VERSION ""

NS_ :

BS_:

BU_: VCM FAS EBS

BO_ 594 EBS_CpbtyAxle456_C03: 64 EBS
 SG_ CpbtyAxle5_BrkEgyCpctyLe : 320|8@1+ (150,0) [0|38250] "NotApplicable"  VCM
 SG_ CpbtyAxle4_TqCpbtyRateQltyLe : 144|4@1+ (1,0) [0|0] ""  VCM
 SG_ CpbtyAxle4_TqCpbtyRateDecRi : 72|8@1+ (1000,0) [0|255000] "NotApplicable"  VCM
 SG_ CpbtyAxle4_BrkEgyCpctyQltyRi : 44|4@1+ (1,0) [0|0] ""  VCM
 SG_ CpbtyAxle4_TqCpbtyMinRi : 110|10@1+ (50,0) [0|51150] "Nm"  VCM
 SG_ CpbtyAxle5_TqCpbtyMaxLe : 288|10@1+ (50,0) [0|51150] "Nm"  VCM
 SG_ CpbtyAxle5_TqCpbtyQltyLe : 274|4@1+ (1,0) [0|0] ""  VCM
 SG_ CpbtyAxle5_PadWearRi : 256|8@1+ (0.5,0) [0|127.5] "Percent"  VCM
 SG_ CpbtyAxle5_TqCpbtyRateIncLeRi : 224|8@1+ (1000,0) [0|255000] "NotApplicable"  VCM
 SG_ CpbtyAxle6_TqCpbtyRateQltyLe : 480|4@1+ (1,0) [0|0] ""  VCM
 SG_ CpbtyAxle5_TqCpbtyRateDecLe : 216|8@1+ (1000,0) [0|255000] "NotApplicable"  VCM
 SG_ CpbtyAxle6_TqCpbtyMinRi : 446|10@1+ (50,0) [0|51150] "Nm"  VCM
 SG_ CpbtyAxle6_BrkEgyCpctyRi : 360|8@1+ (150,0) [0|38250] "NotApplicable"  VCM
 SG_ CpbtyAxle6_TqCpbtyRateQltyRi : 484|4@1+ (1,0) [0|0] ""  VCM
 SG_ CpbtyAxle6_TqCpbtyRateIncLeRi : 392|8@1+ (1000,0) [0|255000] "NotApplicable"  VCM
 SG_ CpbtyAxle5_TqCpbtyMaxRi : 302|10@1+ (50,0) [0|51150] "Nm"  VCM
 SG_ CpbtyAxle5_CRC : 168|16@1+ (1,0) [0|65535] "NotApplicable"  VCM
 SG_ CpbtyAxle6_TqCpbtyRateDecLe : 384|8@1+ (1000,0) [0|255000] "NotApplicable"  VCM
 SG_ CpbtyAxle5_SlipCtrlEna : 328|2@1+ (1,0) [0|0] ""  VCM
 SG_ CpbtyAxle5_PadWearQltyLe : 200|4@1+ (1,0) [0|0] ""  VCM
 SG_ CpbtyAxle6_BrkEgyCpctyQltyRi : 380|4@1+ (1,0) [0|0] ""  VCM
 SG_ CpbtyAxle5_BrkEgyCpctyQltyLe : 208|4@1+ (1,0) [0|0] ""  VCM
 SG_ CpbtyAxle6_PadWearQltyRi : 372|4@1+ (1,0) [0|0] ""  VCM
 SG_ CpbtyAxle6_TqCpbtyMaxRi : 470|10@1+ (50,0) [0|51150] "Nm"  VCM
 SG_ CpbtyAxle4_TqCpbtyQltyLe : 106|4@1+ (1,0) [0|0] ""  VCM
 SG_ CpbtyAxle4_SlipCtrlEna : 160|2@1+ (1,0) [0|0] ""  VCM
 SG_ CpbtyAxle4_BrkEgyCpctyRi : 24|8@1+ (150,0) [0|38250] "NotApplicable"  VCM
 SG_ CpbtyAxle6_TqCpbtyQltyRi : 466|4@1+ (1,0) [0|0] ""  VCM
 SG_ CpbtyAxle6_CRC : 336|16@1+ (1,0) [0|65535] "NotApplicable"  VCM
 SG_ CpbtyAxle5_TqCpbtyRateQltyLe : 312|4@1+ (1,0) [0|0] ""  VCM
 SG_ CpbtyAxle4_TqCpbtyMaxLe : 120|10@1+ (50,0) [0|51150] "Nm"  VCM
 SG_ CpbtyAxle4_PadWearRi : 88|8@1+ (0.5,0) [0|127.5] "Percent"  VCM
 SG_ CpbtyAxle6_TqCpbtyMinLe : 432|10@1+ (50,0) [0|51150] "Nm"  VCM
 SG_ CpbtyAxle4_CRC : 0|16@1+ (1,0) [0|65535] "NotApplicable"  VCM
 SG_ CpbtyAxle4_SqC : 16|8@1+ (1,0) [0|255] "Count"  VCM
 SG_ CpbtyAxle5_TqCpbtyMinLe : 264|10@1+ (50,0) [0|51150] "Nm"  VCM
 SG_ CpbtyAxle6_PadWearQltyLe : 368|4@1+ (1,0) [0|0] ""  VCM
 SG_ CpbtyAxle6_PadWearRi : 424|8@1+ (0.5,0) [0|127.5] "Percent"  VCM
 SG_ CpbtyAxle5_TqCpbtyRateQltyRi : 316|4@1+ (1,0) [0|0] ""  VCM
 SG_ CpbtyAxle4_TqCpbtyQltyRi : 130|4@1+ (1,0) [0|0] ""  VCM
 SG_ CpbtyAxle6_SlipCtrlEna : 496|2@1+ (1,0) [0|0] ""  VCM
 SG_ CpbtyAxle5_TqCpbtyQltyRi : 298|4@1+ (1,0) [0|0] ""  VCM
 SG_ CpbtyAxle4_BrkEgyCpctyQltyLe : 40|4@1+ (1,0) [0|0] ""  VCM
 SG_ CpbtyAxle4_TqCpbtyMinLe : 96|10@1+ (50,0) [0|51150] "Nm"  VCM
 SG_ CpbtyAxle5_TqCpbtyMinRi : 278|10@1+ (50,0) [0|51150] "Nm"  VCM
 SG_ CpbtyAxle6_SqC : 352|8@1+ (1,0) [0|255] "Count"  VCM
 SG_ CpbtyAxle6_TqCpbtyRateDecRi : 408|8@1+ (1000,0) [0|255000] "NotApplicable"  VCM
 SG_ CpbtyAxle6_TqCpbtyRateIncLeLe : 400|8@1+ (1000,0) [0|255000] "NotApplicable"  VCM
 SG_ CpbtyAxle4_TqCpbtyRateDecLe : 48|8@1+ (1000,0) [0|255000] "NotApplicable"  VCM
 SG_ CpbtyAxle4_TqCpbtyRateQltyRi : 148|4@1+ (1,0) [0|0] ""  VCM
 SG_ CpbtyAxle4_BrkEgyCpctyLe : 152|8@1+ (150,0) [0|38250] "NotApplicable"  VCM
 SG_ CpbtyAxle4_TqCpbtyMaxRi : 134|10@1+ (50,0) [0|51150] "Nm"  VCM
 SG_ CpbtyAxle6_TqCpbtyMaxLe : 456|10@1+ (50,0) [0|51150] "Nm"  VCM
 SG_ CpbtyAxle5_TqCpbtyRateIncLeLe : 232|8@1+ (1000,0) [0|255000] "NotApplicable"  VCM
 SG_ CpbtyAxle5_PadWearQltyRi : 204|4@1+ (1,0) [0|0] ""  VCM
 SG_ CpbtyAxle6_BrkEgyCpctyQltyLe : 376|4@1+ (1,0) [0|0] ""  VCM
 SG_ CpbtyAxle5_TqCpbtyRateDecRi : 240|8@1+ (1000,0) [0|255000] "NotApplicable"  VCM
 SG_ CpbtyAxle6_TqCpbtyQltyLe : 442|4@1+ (1,0) [0|0] ""  VCM
 SG_ CpbtyAxle5_SqC : 184|8@1+ (1,0) [0|255] "Count"  VCM
 SG_ CpbtyAxle4_TqCpbtyRateIncLeRi : 56|8@1+ (1000,0) [0|255000] "NotApplicable"  VCM
 SG_ CpbtyAxle6_BrkEgyCpctyLe : 488|8@1+ (150,0) [0|38250] "NotApplicable"  VCM
 SG_ CpbtyAxle5_BrkEgyCpctyRi : 192|8@1+ (150,0) [0|38250] "NotApplicable"  VCM
 SG_ CpbtyAxle5_BrkEgyCpctyQltyRi : 212|4@1+ (1,0) [0|0] ""  VCM
 SG_ CpbtyAxle6_PadWearLe : 416|8@1+ (0.5,0) [0|127.5] "Percent"  VCM
 SG_ CpbtyAxle4_PadWearLe : 80|8@1+ (0.5,0) [0|127.5] "Percent"  VCM
 SG_ CpbtyAxle4_PadWearQltyRi : 36|4@1+ (1,0) [0|0] ""  VCM
 SG_ CpbtyAxle4_TqCpbtyRateIncLeLe : 64|8@1+ (1000,0) [0|255000] "NotApplicable"  VCM
 SG_ CpbtyAxle5_PadWearLe : 248|8@1+ (0.5,0) [0|127.5] "Percent"  VCM
 SG_ CpbtyAxle4_PadWearQltyLe : 32|4@1+ (1,0) [0|0] ""  VCM

BO_ 592 EBS_CpbtyAxle123_C03: 64 EBS
 SG_ CpbtyAxle3_BrkEgyCpctyQltyLe : 376|4@1+ (1,0) [0|0] ""  VCM
 SG_ CpbtyAxle3_TqCpbtyRateIncLeLe : 400|8@1+ (1000,0) [0|255000] "NotApplicable"  VCM
 SG_ CpbtyAxle3_TqCpbtyRateQltyRi : 484|4@1+ (1,0) [0|0] ""  VCM
 SG_ CpbtyAxle1_PadWearQltyLe : 32|4@1+ (1,0) [0|0] ""  VCM
 SG_ CpbtyAxle1_SlipCtrlEna : 160|2@1+ (1,0) [0|0] ""  VCM
 SG_ CpbtyAxle2_PadWearRi : 256|8@1+ (0.5,0) [0|127.5] "Percent"  VCM
 SG_ CpbtyAxle3_TqCpbtyRateQltyLe : 480|4@1+ (1,0) [0|0] ""  VCM
 SG_ CpbtyAxle1_BrkEgyCpctyQltyRi : 44|4@1+ (1,0) [0|0] ""  VCM
 SG_ CpbtyAxle2_TqCpbtyMaxRi : 302|10@1+ (50,0) [0|51150] "Nm"  VCM
 SG_ CpbtyAxle2_TqCpbtyMinLe : 264|10@1+ (50,0) [0|51150] "Nm"  VCM
 SG_ CpbtyAxle2_BrkEgyCpctyQltyLe : 208|4@1+ (1,0) [0|0] ""  VCM
 SG_ CpbtyAxle2_TqCpbtyRateDecLe : 216|8@1+ (1000,0) [0|255000] "NotApplicable"  VCM
 SG_ CpbtyAxle3_SlipCtrlEna : 496|2@1+ (1,0) [0|0] ""  VCM
 SG_ CpbtyAxle3_TqCpbtyQltyLe : 442|4@1+ (1,0) [0|0] ""  VCM
 SG_ CpbtyAxle3_BrkEgyCpctyRi : 360|8@1+ (150,0) [0|38250] "NotApplicable"  VCM
 SG_ CpbtyAxle1_SqC : 16|8@1+ (1,0) [0|255] "Count"  VCM
 SG_ CpbtyAxle1_TqCpbtyQltyLe : 106|4@1+ (1,0) [0|0] ""  VCM
 SG_ CpbtyAxle2_TqCpbtyRateDecRi : 240|8@1+ (1000,0) [0|255000] "NotApplicable"  VCM
 SG_ CpbtyAxle1_TqCpbtyRateIncLeLe : 64|8@1+ (1000,0) [0|255000] "NotApplicable"  VCM
 SG_ CpbtyAxle3_BrkEgyCpctyQltyRi : 380|4@1+ (1,0) [0|0] ""  VCM
 SG_ CpbtyAxle3_TqCpbtyRateDecLe : 384|8@1+ (1000,0) [0|255000] "NotApplicable"  VCM
 SG_ CpbtyAxle3_TqCpbtyRateDecRi : 408|8@1+ (1000,0) [0|255000] "NotApplicable"  VCM
 SG_ CpbtyAxle1_PadWearRi : 88|8@1+ (0.5,0) [0|127.5] "Percent"  VCM
 SG_ CpbtyAxle2_TqCpbtyMaxLe : 288|10@1+ (50,0) [0|51150] "Nm"  VCM
 SG_ CpbtyAxle3_TqCpbtyQltyRi : 466|4@1+ (1,0) [0|0] ""  VCM
 SG_ CpbtyAxle1_TqCpbtyRateDecLe : 48|8@1+ (1000,0) [0|255000] "NotApplicable"  VCM
 SG_ CpbtyAxle1_BrkEgyCpctyRi : 24|8@1+ (150,0) [0|38250] "NotApplicable"  VCM
 SG_ CpbtyAxle3_TqCpbtyMinLe : 432|10@1+ (50,0) [0|51150] "Nm"  VCM
 SG_ CpbtyAxle3_TqCpbtyMinRi : 446|10@1+ (50,0) [0|51150] "Nm"  VCM
 SG_ CpbtyAxle2_BrkEgyCpctyQltyRi : 212|4@1+ (1,0) [0|0] ""  VCM
 SG_ CpbtyAxle2_PadWearLe : 248|8@1+ (0.5,0) [0|127.5] "Percent"  VCM
 SG_ CpbtyAxle2_TqCpbtyQltyRi : 298|4@1+ (1,0) [0|0] ""  VCM
 SG_ CpbtyAxle2_PadWearQltyRi : 204|4@1+ (1,0) [0|0] ""  VCM
 SG_ CpbtyAxle3_PadWearRi : 424|8@1+ (0.5,0) [0|127.5] "Percent"  VCM
 SG_ CpbtyAxle3_PadWearQltyRi : 372|4@1+ (1,0) [0|0] ""  VCM
 SG_ CpbtyAxle1_TqCpbtyMaxRi : 134|10@1+ (50,0) [0|51150] "Nm"  VCM
 SG_ CpbtyAxle2_TqCpbtyRateQltyRi : 316|4@1+ (1,0) [0|0] ""  VCM
 SG_ CpbtyAxle1_BrkEgyCpctyLe : 152|8@1+ (150,0) [0|38250] "NotApplicable"  VCM
 SG_ CpbtyAxle2_SlipCtrlEna : 328|2@1+ (1,0) [0|0] ""  VCM
 SG_ CpbtyAxle1_TqCpbtyRateIncLeRi : 56|8@1+ (1000,0) [0|255000] "NotApplicable"  VCM
 SG_ CpbtyAxle2_TqCpbtyMinRi : 278|10@1+ (50,0) [0|51150] "Nm"  VCM
 SG_ CpbtyAxle3_TqCpbtyMaxLe : 456|10@1+ (50,0) [0|51150] "Nm"  VCM
 SG_ CpbtyAxle1_TqCpbtyRateQltyRi : 148|4@1+ (1,0) [0|0] ""  VCM
 SG_ CpbtyAxle1_CRC : 0|16@1+ (1,0) [0|65535] "NotApplicable"  VCM
 SG_ CpbtyAxle1_PadWearQltyRi : 36|4@1+ (1,0) [0|0] ""  VCM
 SG_ CpbtyAxle2_CRC : 168|16@1+ (1,0) [0|65535] "NotApplicable"  VCM
 SG_ CpbtyAxle2_SqC : 184|8@1+ (1,0) [0|255] "Count"  VCM
 SG_ CpbtyAxle2_TqCpbtyRateIncLeLe : 232|8@1+ (1000,0) [0|255000] "NotApplicable"  VCM
 SG_ CpbtyAxle2_TqCpbtyRateIncLeRi : 224|8@1+ (1000,0) [0|255000] "NotApplicable"  VCM
 SG_ CpbtyAxle2_BrkEgyCpctyLe : 320|8@1+ (150,0) [0|38250] "NotApplicable"  VCM
 SG_ CpbtyAxle1_TqCpbtyRateDecRi : 72|8@1+ (1000,0) [0|255000] "NotApplicable"  VCM
 SG_ CpbtyAxle3_TqCpbtyMaxRi : 470|10@1+ (50,0) [0|51150] "Nm"  VCM
 SG_ CpbtyAxle3_PadWearQltyLe : 368|4@1+ (1,0) [0|0] ""  VCM
 SG_ CpbtyAxle3_PadWearLe : 416|8@1+ (0.5,0) [0|127.5] "Percent"  VCM
 SG_ CpbtyAxle1_TqCpbtyRateQltyLe : 144|4@1+ (1,0) [0|0] ""  VCM
 SG_ CpbtyAxle1_PadWearLe : 80|8@1+ (0.5,0) [0|127.5] "Percent"  VCM
 SG_ CpbtyAxle1_TqCpbtyMinRi : 110|10@1+ (50,0) [0|51150] "Nm"  VCM
 SG_ CpbtyAxle1_TqCpbtyQltyRi : 130|4@1+ (1,0) [0|0] ""  VCM
 SG_ CpbtyAxle3_BrkEgyCpctyLe : 488|8@1+ (150,0) [0|38250] "NotApplicable"  VCM
 SG_ CpbtyAxle3_TqCpbtyRateIncLeRi : 392|8@1+ (1000,0) [0|255000] "NotApplicable"  VCM
 SG_ CpbtyAxle1_TqCpbtyMinLe : 96|10@1+ (50,0) [0|51150] "Nm"  VCM
 SG_ CpbtyAxle2_TqCpbtyQltyLe : 274|4@1+ (1,0) [0|0] ""  VCM
 SG_ CpbtyAxle2_TqCpbtyRateQltyLe : 312|4@1+ (1,0) [0|0] ""  VCM
 SG_ CpbtyAxle2_BrkEgyCpctyRi : 192|8@1+ (150,0) [0|38250] "NotApplicable"  VCM
 SG_ CpbtyAxle1_BrkEgyCpctyQltyLe : 40|4@1+ (1,0) [0|0] ""  VCM
 SG_ CpbtyAxle2_PadWearQltyLe : 200|4@1+ (1,0) [0|0] ""  VCM
 SG_ CpbtyAxle1_TqCpbtyMaxLe : 120|10@1+ (50,0) [0|51150] "Nm"  VCM
 SG_ CpbtyAxle3_CRC : 336|16@1+ (1,0) [0|65535] "NotApplicable"  VCM
 SG_ CpbtyAxle3_SqC : 352|8@1+ (1,0) [0|255] "Count"  VCM

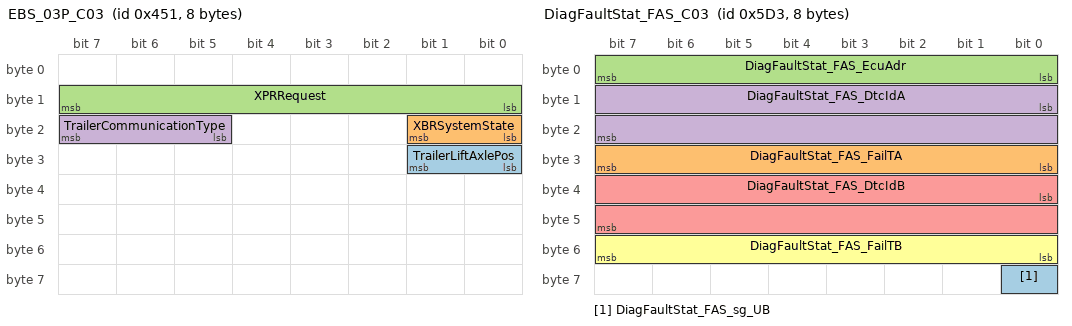
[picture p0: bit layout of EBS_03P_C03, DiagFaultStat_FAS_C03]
BO_ 1105 EBS_03P_C03: 8 EBS
 SG_ TrailerLiftAxlePos : 24|2@1+ (1,0) [0|0] ""  VCM
 SG_ XBRSystemState : 16|2@1+ (1,0) [0|0] ""  VCM
 SG_ XPRRequest : 8|8@1+ (1,0) [0|255] "NotApplicable"  VCM
 SG_ TrailerCommunicationType : 21|3@1+ (1,0) [0|0] ""  VCM

BO_ 439 EBS_02P_C03: 48 EBS
 SG_ ABSAxle5Active : 152|2@1+ (1,0) [0|0] ""  VCM
 SG_ EACompound_CRC : 0|8@1+ (1,0) [0|255] ""  VCM
 SG_ RrAxle1RtWhlBrakeApplPrsHiRng : 72|8@1+ (5,0) [0|1275] "kPa"  VCM
 SG_ RrAxle3RtWhlBrakeApplPrsHiRng : 104|8@1+ (5,0) [0|1275] "kPa"  VCM
 SG_ Trailer1LiftAxle2Pos : 216|2@1+ (1,0) [0|0] ""  VCM
 SG_ Trailer1TractionHelp : 218|2@1+ (1,0) [0|0] ""  VCM
 SG_ FrAxleRtWhlBrakeApplPrsHiRng : 56|8@1+ (5,0) [0|1275] "kPa"  VCM
 SG_ EBSBrakeSwitch : 162|2@1+ (1,0) [0|0] ""  VCM
 SG_ RrAxle3RightWheelRelativeSpeed : 120|8@1+ (0.0625,-7.8125) [-7.8125|8.125] "Km_per_h"  VCM
 SG_ EACompound_SystemState : 12|2@1+ (1,0) [0|0] ""  VCM
 SG_ Trailer1LiftAxle1Pos : 160|2@1+ (1,0) [0|0] ""  VCM
 SG_ EBSBrakePedalPosition : 176|8@1+ (0.4,0) [0|102] "Percent"  VCM
 SG_ AntiLockBrakingActive : 154|2@1+ (1,0) [0|0] ""  FAS,VCM
 SG_ RrAxle3LeftWheelRelativeSpeed : 112|8@1+ (0.0625,-7.8125) [-7.8125|8.125] "Km_per_h"  VCM
 SG_ StretchBrake_Stat : 141|3@1+ (1,0) [0|0] ""  VCM
 SG_ HillHolderMode : 136|3@1+ (1,0) [0|0] ""  VCM
 SG_ ABSAxle4Active : 150|2@1+ (1,0) [0|0] ""  VCM
 SG_ TrailerBrake_Stat : 172|2@1+ (1,0) [0|0] ""  VCM
 SG_ CombinedWheelSpeed_CRC : 184|8@1+ (1,0) [0|255] ""  VCM
 SG_ ABSAxle2Active : 146|2@1+ (1,0) [0|0] ""  VCM
 SG_ TrailerEBSAmberWarning : 174|2@1+ (1,0) [0|0] ""  VCM
 SG_ CombinedWheelSpeed_SqC : 192|4@1+ (1,0) [0|14] "NotApplicable"  VCM
 SG_ ABSAxle1Active : 144|2@1+ (1,0) [0|0] ""  VCM
 SG_ RrAxle2LtWhlBrakeApplPrsHiRng : 80|8@1+ (5,0) [0|1275] "kPa"  VCM
 SG_ ABSAxle3Active : 148|2@1+ (1,0) [0|0] ""  VCM
 SG_ TCMSupply_SqC : 32|4@1+ (1,0) [0|14] "NotApplicable"  VCM
 SG_ PusherLiftAxleLoweringInhibit : 170|2@1+ (1,0) [0|0] ""  VCM
 SG_ CombinedWheelSpeed_Quality : 196|3@1+ (1,0) [0|0] ""  VCM
 SG_ SplitBoxDiffLockActvnFuncReq : 166|2@1+ (1,0) [0|0] ""  VCM
 SG_ FrontParkBrakeOverrideStatus : 158|2@1+ (1,0) [0|0] ""  VCM
 SG_ SteerableLiftAxleLoweringInhib : 168|2@1+ (1,0) [0|0] ""  VCM
 SG_ RrAxle3LtWhlBrakeApplPrsHiRng : 96|8@1+ (5,0) [0|1275] "kPa"  VCM
 SG_ EACompound_AppliedRatio : 16|8@1+ (0.004,0) [0|1.02] ""  VCM
 SG_ BrakingSystemPressureLim_rqst : 156|2@1+ (1,0) [0|0] ""  VCM
 SG_ RrAxle1LtWhlBrakeApplPrsHiRng : 64|8@1+ (5,0) [0|1275] "kPa"  VCM
 SG_ EACompound_SqC : 8|4@1+ (1,0) [0|14] "NotApplicable"  VCM
 SG_ TCMSupply_CRC : 24|8@1+ (1,0) [0|255] ""  VCM
 SG_ TrailerControlPressure : 128|8@1+ (5,0) [0|1275] "kPa"  VCM
 SG_ RrAxle2RtWhlBrakeApplPrsHiRng : 88|8@1+ (5,0) [0|1275] "kPa"  VCM
 SG_ ScndRrAxlDiffLckActvnFuncReq : 164|2@1+ (1,0) [0|0] ""  VCM
 SG_ TCMSupply_TrailerPressure : 40|8@1+ (8,0) [0|2040] "kPa"  VCM
 SG_ CombinedWheelSpeed_Speed : 200|16@1+ (0.00390625,0) [0|255.99609375] "Km_per_h"  VCM
 SG_ HSAState : 139|2@1+ (1,0) [0|0] ""  VCM
 SG_ FrAxleLtWhlBrakeApplPrsHiRng : 48|8@1+ (5,0) [0|1275] "kPa"  VCM

BO_ 315 EBS_01P_C03: 20 EBS
 SG_ FrontAxleLeftWheelSpeed : 80|16@1+ (0.00390625,0) [0|255.99609375] "Km_per_h"  VCM,FAS
 SG_ SteeringWheel_AngleCRC : 16|8@1+ (1,0) [0|255] "NotApplicable"  VCM
 SG_ SteeringWheel_AngleCounter : 24|4@1+ (1,0) [0|15] "NotApplicable"  VCM
 SG_ FrontAxleRightWheelSpeed : 96|16@1+ (0.00390625,0) [0|255.99609375] "Km_per_h"  VCM,FAS
 SG_ SteeringWheel_AngleValue : 0|16@1+ (0.0009765625,-31.374) [-31.374|32.6250234375] "rad"  VCM
 SG_ SteeringWheelAngle : 32|16@1+ (0.0009765625,-31.374) [-31.374|32.6250234375] "rad"  VCM,FAS
 SG_ SteeringWheelAngleComp : 48|16@1+ (0.0009765625,-31.374) [-31.374|32.6250234375] "rad"  VCM,FAS
 SG_ YawRate : 64|16@1+ (0.000122,-3.92) [-3.92|4.07527] "Rad_per_s"  FAS,VCM

BO_ 2671964720 DiagUUDTRespMsg1_F2_30_C03: 8 FAS
 SG_ DiagUUDTRespSig_F2_30 : 0|64@1+ (1,0) [0|0] ""  VCM

BO_ 2671964707 DiagUUDTRespMsg1_F2_23_C03: 8 Vector__XXX
 SG_ DiagUUDTRespSig_F2_23 : 0|64@1+ (1,0) [0|0] "" Vector__XXX

BO_ 2671834160 DiagRespMsgForIntTest_F4_30_C03: 8 FAS
 SG_ InternalTesterDiagSig_F4_30 : 0|64@1+ (1,0) [0|0] ""  VCM

BO_ 2671834147 DiagRespMsgForIntTest_F4_23_C03: 8 Vector__XXX
 SG_ InternalTesterDiagSig_F4_23 : 0|64@1+ (1,0) [0|0] "" Vector__XXX

BO_ 2671784180 DiagReqMsgOfIntTest_30_F4_C03: 8 VCM
 SG_ InternalTesterDiagSig_30_F4 : 0|64@1+ (1,0) [0|0] ""  FAS

BO_ 2671780852 DiagReqMsgOfIntTest_23_F4_C03: 8 Vector__XXX
 SG_ InternalTesterDiagSig_23_F4 : 0|64@1+ (1,0) [0|0] "" Vector__XXX

BO_ 1491 DiagFaultStat_FAS_C03: 8 FAS
 SG_ DiagFaultStat_FAS_sg_UB : 56|1@1+ (1,0) [0|0] ""  VCM
 SG_ DiagFaultStat_FAS_FailTA : 24|8@1+ (1,0) [0|255] ""  VCM
 SG_ DiagFaultStat_FAS_EcuAdr : 0|8@1+ (1,0) [0|255] ""  VCM
 SG_ DiagFaultStat_FAS_DtcIdA : 8|16@1+ (1,0) [0|65535] ""  VCM
 SG_ DiagFaultStat_FAS_DtcIdB : 32|16@1+ (1,0) [0|65535] ""  VCM
 SG_ DiagFaultStat_FAS_FailTB : 48|8@1+ (1,0) [0|255] ""  VCM

BO_ 1954 Debug9_FAS_C03: 8 FAS
 SG_ Debug_9_FAS : 0|64@1+ (1,0) [0|0] "" Vector__XXX

BO_ 1949 Debug8_FAS_C03: 8 Vector__XXX
 SG_ Debug_8_FAS : 0|64@1+ (1,0) [0|0] ""  FAS

BO_ 1944 Debug7_FAS_C03: 8 Vector__XXX
 SG_ Debug_7_FAS : 0|64@1+ (1,0) [0|0] ""  FAS

BO_ 1938 Debug6_FAS_C03: 8 FAS
 SG_ Debug_6_FAS : 0|64@1+ (1,0) [0|0] "" Vector__XXX

BO_ 1930 Debug5_FAS_C03: 8 FAS
 SG_ Debug_5_FAS : 0|64@1+ (1,0) [0|0] "" Vector__XXX

BO_ 1922 Debug4_FAS_C03: 8 FAS
 SG_ Debug_4_FAS : 0|64@1+ (1,0) [0|0] "" Vector__XXX

BO_ 1914 Debug3_FAS_C03: 8 FAS
 SG_ Debug_3_FAS : 0|64@1+ (1,0) [0|0] "" Vector__XXX

BO_ 1906 Debug2_FAS_C03: 8 FAS
 SG_ Debug_2_FAS : 0|64@1+ (1,0) [0|0] "" Vector__XXX

BO_ 1898 Debug1_FAS_C03: 8 Vector__XXX
 SG_ Debug_1_FAS : 0|64@1+ (1,0) [0|0] ""  FAS

BO_ 1959 Debug16_FAS_C03: 8 FAS
 SG_ Debug_16_FAS : 0|64@1+ (1,0) [0|0] "" Vector__XXX

BO_ 1891 Debug15_FAS_C03: 8 FAS
 SG_ Debug_15_FAS : 0|64@1+ (1,0) [0|0] "" Vector__XXX

BO_ 1890 Debug14_FAS_C03: 8 FAS
 SG_ Debug_14_FAS : 0|64@1+ (1,0) [0|0] "" Vector__XXX

BO_ 1889 Debug13_FAS_C03: 8 FAS
 SG_ Debug_13_FAS : 0|64@1+ (1,0) [0|0] "" Vector__XXX

BO_ 1888 Debug12_FAS_C03: 8 FAS
 SG_ Debug_12_FAS : 0|64@1+ (1,0) [0|0] "" Vector__XXX

BO_ 1887 Debug11_FAS_C03: 8 FAS
 SG_ Debug_11_FAS : 0|64@1+ (1,0) [0|0] "" Vector__XXX

BO_ 1886 Debug10_FAS_C03: 8 FAS
 SG_ Debug_10_FAS : 0|64@1+ (1,0) [0|0] "" Vector__XXX

BO_ 2041 DSPTesterRespFAS_C03: 8 FAS
 SG_ DSPTesterRespSigFAS : 0|64@1+ (1,0) [0|0] "" Vector__XXX

BO_ 2047 DSPTesterReqFAS_C03: 8 Vector__XXX
 SG_ DSPTesterReqSigFAS : 0|64@1+ (1,0) [0|0] ""  FAS

BO_ 1703 AnmMsg_VCM_C03: 8 VCM
 SG_ AnmSig_VCM_CAN03 : 0|32@1+ (1,0) [0|0] ""  EBS,FAS

BO_ 1701 AnmMsg_FAS_C03: 8 FAS
 SG_ AnmSig_FAS_CAN03 : 0|32@1+ (1,0) [0|0] ""  EBS,VCM

BO_ 1704 AnmMsg_EBS_C03: 8 EBS
 SG_ AnmSig_EBS_CAN03 : 0|32@1+ (1,0) [0|0] ""  FAS,VCM

BO_ 1702 AnmMsg_APM_C03: 8 Vector__XXX
 SG_ AnmSig_APM_CAN03 : 0|32@1+ (1,0) [0|0] ""  EBS,VCM,FAS

CM_ BO_ 2041 "This message is used only for supplier production test.";
CM_ BO_ 2047 "This message is used only for supplier production test.";
BA_DEF_ BO_  "GenMsgStartDelayTime" INT 0 0;
BA_DEF_ BO_  "GenMsgDelayTime" INT 0 0;
BA_DEF_ BO_  "GenMsgCycleTime" INT 0 0;
BA_DEF_ BO_  "GenMsgSendType" ENUM  "Cyclic","NotUsed","NotUsed","NotUsed","NotUsed","NotUsed","NotUsed","IfActive","NoMsgSendType","NotUsed";
BA_DEF_ SG_  "GenSigStartValue" INT 0 0;
BA_DEF_ SG_  "GenSigCycleTimeActive" INT 0 0;
BA_DEF_ SG_  "GenSigCycleTime" INT 0 0;
BA_DEF_ SG_  "GenSigSendType" ENUM  "Cyclic","OnWrite","OnWriteWithRepetition","OnChange","OnChangeWithRepetition","IfActive","IfActiveWithRepetition","NoSigSendType","NotUsed","NotUsed","NotUsed","NotUsed","NotUsed";
BA_DEF_ BO_  "VFrameFormat" ENUM  "StandardCAN","ExtendedCAN","reserved","J1939PG","reserved","reserved","reserved","reserved","reserved","reserved","reserved","reserved","reserved","reserved","StandardCAN_FD","ExtendedCAN_FD";
BA_DEF_ SG_  "SigType" ENUM  "Default","Range","RangeSigned","ASCII","Discrete","Control","ReferencePGN","DTC","StringDelimiter","StringLength","StringLengthControl";
BA_DEF_ BO_  "NmAsrMessage" ENUM  "No","Yes";
BA_DEF_ SG_  "NeedsUpdateBit" ENUM  "No","Yes";
BA_DEF_ SG_  "MmAnSignal" ENUM  "No","Yes";
BA_DEF_ SG_  "GenSigMaxLatency" INT 0 65535;
BA_DEF_ SG_  "GenSigILSupport" ENUM  "Yes","No";
BA_DEF_ BO_  "GenMsgILSupport" ENUM  "No","Yes";
BA_DEF_ SG_  "E2EProfile" STRING ;
BA_DEF_ SG_  "E2EDataLength" INT 0 65535;
BA_DEF_ SG_  "E2EDataId" INT 0 65535;
BA_DEF_ BO_  "DiagUUDTResponse" ENUM  "No","Yes";
BA_DEF_ BO_  "DiagState" ENUM  "No","Yes";
BA_DEF_ BO_  "DiagResponse" ENUM  "No","Yes";
BA_DEF_ BO_  "DiagRequest" ENUM  "No","Yes";
BA_DEF_ BO_  "DiagConnection" HEX 0 65535;
BA_DEF_ BO_  "CanTpFcFrameId" HEX 0 2147483647;
BA_DEF_ BO_  "CanTpBs" INT 0 255;
BA_DEF_ BO_  "CANFD_BRS" ENUM  "0","1";
BA_DEF_REL_ BU_SG_REL_  "GenSigTimeoutTime" INT 0 65535;
BA_DEF_REL_ BU_SG_REL_  "GenSigFirstTimeoutTime" INT 0 65535;
BA_DEF_DEF_  "GenMsgStartDelayTime" 0;
BA_DEF_DEF_  "GenMsgDelayTime" 0;
BA_DEF_DEF_  "GenMsgCycleTime" 0;
BA_DEF_DEF_  "GenMsgSendType" "Cyclic";
BA_DEF_DEF_  "GenSigStartValue" 0;
BA_DEF_DEF_  "GenSigCycleTimeActive" 0;
BA_DEF_DEF_  "GenSigCycleTime" 0;
BA_DEF_DEF_  "GenSigSendType" "Cyclic";
BA_DEF_DEF_  "VFrameFormat" "ExtendedCAN";
BA_DEF_DEF_  "SigType" "Default";
BA_DEF_DEF_  "NmAsrMessage" "No";
BA_DEF_DEF_  "NeedsUpdateBit" "No";
BA_DEF_DEF_  "MmAnSignal" "No";
BA_DEF_DEF_  "GenSigMaxLatency" 0;
BA_DEF_DEF_  "GenSigILSupport" "Yes";
BA_DEF_DEF_  "GenMsgILSupport" "Yes";
BA_DEF_DEF_  "E2EProfile" "none";
BA_DEF_DEF_  "E2EDataLength" 0;
BA_DEF_DEF_  "E2EDataId" 0;
BA_DEF_DEF_  "DiagUUDTResponse" "No";
BA_DEF_DEF_  "DiagState" "No";
BA_DEF_DEF_  "DiagResponse" "No";
BA_DEF_DEF_  "DiagRequest" "No";
BA_DEF_DEF_  "DiagConnection" 0;
BA_DEF_DEF_  "CanTpFcFrameId" 2147483647;
BA_DEF_DEF_  "CanTpBs" 255;
BA_DEF_DEF_  "CANFD_BRS" "0";
BA_DEF_DEF_REL_ "GenSigTimeoutTime" 0;
BA_DEF_DEF_REL_ "GenSigFirstTimeoutTime" 0;
BA_ "CANFD_BRS" BO_ 594 1;
BA_ "GenMsgCycleTime" BO_ 594 50;
BA_ "GenMsgStartDelayTime" BO_ 594 15;
BA_ "VFrameFormat" BO_ 594 14;
BA_ "CANFD_BRS" BO_ 592 1;
BA_ "GenMsgCycleTime" BO_ 592 50;
BA_ "GenMsgStartDelayTime" BO_ 592 5;
BA_ "VFrameFormat" BO_ 592 14;
BA_ "CANFD_BRS" BO_ 1105 1;
BA_ "GenMsgCycleTime" BO_ 1105 100;
BA_ "GenMsgStartDelayTime" BO_ 1105 35;
BA_ "VFrameFormat" BO_ 1105 14;
BA_ "CANFD_BRS" BO_ 439 1;
BA_ "GenMsgCycleTime" BO_ 439 20;
BA_ "GenMsgStartDelayTime" BO_ 439 5;
BA_ "VFrameFormat" BO_ 439 14;
BA_ "CANFD_BRS" BO_ 315 1;
BA_ "GenMsgCycleTime" BO_ 315 10;
BA_ "GenMsgStartDelayTime" BO_ 315 5;
BA_ "VFrameFormat" BO_ 315 14;
BA_ "DiagConnection" BO_ 2671964720 62000;
BA_ "DiagUUDTResponse" BO_ 2671964720 1;
BA_ "GenMsgILSupport" BO_ 2671964720 0;
BA_ "GenMsgSendType" BO_ 2671964720 8;
BA_ "DiagConnection" BO_ 2671964707 61987;
BA_ "DiagUUDTResponse" BO_ 2671964707 1;
BA_ "GenMsgILSupport" BO_ 2671964707 0;
BA_ "DiagConnection" BO_ 2671834160 62512;
BA_ "DiagResponse" BO_ 2671834160 1;
BA_ "GenMsgILSupport" BO_ 2671834160 0;
BA_ "GenMsgSendType" BO_ 2671834160 8;
BA_ "DiagConnection" BO_ 2671834147 62499;
BA_ "DiagResponse" BO_ 2671834147 1;
BA_ "GenMsgILSupport" BO_ 2671834147 0;
BA_ "DiagConnection" BO_ 2671784180 62512;
BA_ "DiagRequest" BO_ 2671784180 1;
BA_ "GenMsgILSupport" BO_ 2671784180 0;
BA_ "GenMsgSendType" BO_ 2671784180 8;
BA_ "DiagConnection" BO_ 2671780852 62499;
BA_ "DiagRequest" BO_ 2671780852 1;
BA_ "GenMsgILSupport" BO_ 2671780852 0;
BA_ "CANFD_BRS" BO_ 1491 1;
BA_ "GenMsgCycleTime" BO_ 1491 1000;
BA_ "GenMsgDelayTime" BO_ 1491 90;
BA_ "VFrameFormat" BO_ 1491 14;
BA_ "CANFD_BRS" BO_ 1954 1;
BA_ "GenMsgSendType" BO_ 1954 8;
BA_ "VFrameFormat" BO_ 1954 14;
BA_ "CANFD_BRS" BO_ 1949 1;
BA_ "VFrameFormat" BO_ 1949 14;
BA_ "CANFD_BRS" BO_ 1944 1;
BA_ "VFrameFormat" BO_ 1944 14;
BA_ "CANFD_BRS" BO_ 1938 1;
BA_ "GenMsgSendType" BO_ 1938 8;
BA_ "GenMsgDelayTime" BO_ 1938 50;
BA_ "VFrameFormat" BO_ 1938 14;
BA_ "CANFD_BRS" BO_ 1930 1;
BA_ "GenMsgSendType" BO_ 1930 8;
BA_ "VFrameFormat" BO_ 1930 14;
BA_ "CANFD_BRS" BO_ 1922 1;
BA_ "GenMsgSendType" BO_ 1922 8;
BA_ "VFrameFormat" BO_ 1922 14;
BA_ "CANFD_BRS" BO_ 1914 1;
BA_ "GenMsgSendType" BO_ 1914 8;
BA_ "VFrameFormat" BO_ 1914 14;
BA_ "CANFD_BRS" BO_ 1906 1;
BA_ "GenMsgSendType" BO_ 1906 8;
BA_ "VFrameFormat" BO_ 1906 14;
BA_ "CANFD_BRS" BO_ 1898 1;
BA_ "VFrameFormat" BO_ 1898 14;
BA_ "CANFD_BRS" BO_ 1959 1;
BA_ "GenMsgSendType" BO_ 1959 8;
BA_ "VFrameFormat" BO_ 1959 14;
BA_ "CANFD_BRS" BO_ 1891 1;
BA_ "GenMsgSendType" BO_ 1891 8;
BA_ "VFrameFormat" BO_ 1891 14;
BA_ "CANFD_BRS" BO_ 1890 1;
BA_ "GenMsgSendType" BO_ 1890 8;
BA_ "VFrameFormat" BO_ 1890 14;
BA_ "CANFD_BRS" BO_ 1889 1;
BA_ "GenMsgSendType" BO_ 1889 8;
BA_ "VFrameFormat" BO_ 1889 14;
BA_ "CANFD_BRS" BO_ 1888 1;
BA_ "GenMsgSendType" BO_ 1888 8;
BA_ "VFrameFormat" BO_ 1888 14;
BA_ "CANFD_BRS" BO_ 1887 1;
BA_ "GenMsgSendType" BO_ 1887 8;
BA_ "VFrameFormat" BO_ 1887 14;
BA_ "CANFD_BRS" BO_ 1886 1;
BA_ "GenMsgSendType" BO_ 1886 8;
BA_ "GenMsgStartDelayTime" BO_ 1886 50;
BA_ "VFrameFormat" BO_ 1886 14;
BA_ "VFrameFormat" BO_ 2041 0;
BA_ "GenMsgSendType" BO_ 2041 8;
BA_ "GenMsgDelayTime" BO_ 2041 50;
BA_ "VFrameFormat" BO_ 2047 0;
BA_ "CANFD_BRS" BO_ 1703 1;
BA_ "GenMsgCycleTime" BO_ 1703 100;
BA_ "VFrameFormat" BO_ 1703 14;
BA_ "CANFD_BRS" BO_ 1701 1;
BA_ "GenMsgCycleTime" BO_ 1701 100;
BA_ "GenMsgStartDelayTime" BO_ 1701 15;
BA_ "VFrameFormat" BO_ 1701 14;
BA_ "CANFD_BRS" BO_ 1704 1;
BA_ "GenMsgCycleTime" BO_ 1704 100;
BA_ "VFrameFormat" BO_ 1704 14;
BA_ "CANFD_BRS" BO_ 1702 1;
BA_ "VFrameFormat" BO_ 1702 14;
BA_ "GenSigCycleTime" SG_ 594 CpbtyAxle5_BrkEgyCpctyLe 100;
BA_ "GenSigCycleTimeActive" SG_ 594 CpbtyAxle5_BrkEgyCpctyLe 100;
BA_ "GenSigStartValue" SG_ 594 CpbtyAxle5_BrkEgyCpctyLe 255;
BA_ "GenSigCycleTime" SG_ 594 CpbtyAxle4_TqCpbtyRateQltyLe 100;
BA_ "GenSigCycleTimeActive" SG_ 594 CpbtyAxle4_TqCpbtyRateQltyLe 100;
BA_ "GenSigStartValue" SG_ 594 CpbtyAxle4_TqCpbtyRateQltyLe 15;
BA_ "GenSigCycleTime" SG_ 594 CpbtyAxle4_TqCpbtyRateDecRi 100;
BA_ "GenSigCycleTimeActive" SG_ 594 CpbtyAxle4_TqCpbtyRateDecRi 100;
BA_ "GenSigStartValue" SG_ 594 CpbtyAxle4_TqCpbtyRateDecRi 255;
BA_ "GenSigCycleTime" SG_ 594 CpbtyAxle4_BrkEgyCpctyQltyRi 100;
BA_ "GenSigCycleTimeActive" SG_ 594 CpbtyAxle4_BrkEgyCpctyQltyRi 100;
BA_ "GenSigStartValue" SG_ 594 CpbtyAxle4_BrkEgyCpctyQltyRi 15;
BA_ "GenSigCycleTime" SG_ 594 CpbtyAxle4_TqCpbtyMinRi 100;
BA_ "GenSigCycleTimeActive" SG_ 594 CpbtyAxle4_TqCpbtyMinRi 100;
BA_ "GenSigStartValue" SG_ 594 CpbtyAxle4_TqCpbtyMinRi 1023;
BA_ "GenSigCycleTime" SG_ 594 CpbtyAxle5_TqCpbtyMaxLe 100;
BA_ "GenSigCycleTimeActive" SG_ 594 CpbtyAxle5_TqCpbtyMaxLe 100;
BA_ "GenSigStartValue" SG_ 594 CpbtyAxle5_TqCpbtyMaxLe 1023;
BA_ "GenSigCycleTime" SG_ 594 CpbtyAxle5_TqCpbtyQltyLe 100;
BA_ "GenSigCycleTimeActive" SG_ 594 CpbtyAxle5_TqCpbtyQltyLe 100;
BA_ "GenSigStartValue" SG_ 594 CpbtyAxle5_TqCpbtyQltyLe 15;
BA_ "GenSigCycleTime" SG_ 594 CpbtyAxle5_PadWearRi 100;
BA_ "GenSigCycleTimeActive" SG_ 594 CpbtyAxle5_PadWearRi 100;
BA_ "GenSigStartValue" SG_ 594 CpbtyAxle5_PadWearRi 255;
BA_ "GenSigCycleTime" SG_ 594 CpbtyAxle5_TqCpbtyRateIncLeRi 100;
BA_ "GenSigCycleTimeActive" SG_ 594 CpbtyAxle5_TqCpbtyRateIncLeRi 100;
BA_ "GenSigStartValue" SG_ 594 CpbtyAxle5_TqCpbtyRateIncLeRi 255;
BA_ "GenSigCycleTime" SG_ 594 CpbtyAxle6_TqCpbtyRateQltyLe 100;
BA_ "GenSigCycleTimeActive" SG_ 594 CpbtyAxle6_TqCpbtyRateQltyLe 100;
BA_ "GenSigStartValue" SG_ 594 CpbtyAxle6_TqCpbtyRateQltyLe 15;
BA_ "GenSigCycleTime" SG_ 594 CpbtyAxle5_TqCpbtyRateDecLe 100;
BA_ "GenSigCycleTimeActive" SG_ 594 CpbtyAxle5_TqCpbtyRateDecLe 100;
BA_ "GenSigStartValue" SG_ 594 CpbtyAxle5_TqCpbtyRateDecLe 255;
BA_ "GenSigCycleTime" SG_ 594 CpbtyAxle6_TqCpbtyMinRi 100;
BA_ "GenSigCycleTimeActive" SG_ 594 CpbtyAxle6_TqCpbtyMinRi 100;
BA_ "GenSigStartValue" SG_ 594 CpbtyAxle6_TqCpbtyMinRi 1023;
BA_ "GenSigCycleTime" SG_ 594 CpbtyAxle6_BrkEgyCpctyRi 100;
BA_ "GenSigCycleTimeActive" SG_ 594 CpbtyAxle6_BrkEgyCpctyRi 100;
BA_ "GenSigStartValue" SG_ 594 CpbtyAxle6_BrkEgyCpctyRi 255;
BA_ "GenSigCycleTime" SG_ 594 CpbtyAxle6_TqCpbtyRateQltyRi 100;
BA_ "GenSigCycleTimeActive" SG_ 594 CpbtyAxle6_TqCpbtyRateQltyRi 100;
BA_ "GenSigStartValue" SG_ 594 CpbtyAxle6_TqCpbtyRateQltyRi 15;
BA_ "GenSigCycleTime" SG_ 594 CpbtyAxle6_TqCpbtyRateIncLeRi 100;
BA_ "GenSigCycleTimeActive" SG_ 594 CpbtyAxle6_TqCpbtyRateIncLeRi 100;
BA_ "GenSigStartValue" SG_ 594 CpbtyAxle6_TqCpbtyRateIncLeRi 255;
BA_ "GenSigCycleTime" SG_ 594 CpbtyAxle5_TqCpbtyMaxRi 100;
BA_ "GenSigCycleTimeActive" SG_ 594 CpbtyAxle5_TqCpbtyMaxRi 100;
BA_ "GenSigStartValue" SG_ 594 CpbtyAxle5_TqCpbtyMaxRi 1023;
BA_ "GenSigCycleTime" SG_ 594 CpbtyAxle5_CRC 100;
BA_ "GenSigCycleTimeActive" SG_ 594 CpbtyAxle5_CRC 100;
BA_ "GenSigStartValue" SG_ 594 CpbtyAxle5_CRC 65535;
BA_ "E2EDataId" SG_ 594 CpbtyAxle5_CRC 193;
BA_ "E2EDataLength" SG_ 594 CpbtyAxle5_CRC 168;
BA_ "E2EProfile" SG_ 594 CpbtyAxle5_CRC "P05";
BA_ "GenSigCycleTime" SG_ 594 CpbtyAxle6_TqCpbtyRateDecLe 100;
BA_ "GenSigCycleTimeActive" SG_ 594 CpbtyAxle6_TqCpbtyRateDecLe 100;
BA_ "GenSigStartValue" SG_ 594 CpbtyAxle6_TqCpbtyRateDecLe 255;
BA_ "GenSigCycleTime" SG_ 594 CpbtyAxle5_SlipCtrlEna 100;
BA_ "GenSigCycleTimeActive" SG_ 594 CpbtyAxle5_SlipCtrlEna 100;
BA_ "GenSigStartValue" SG_ 594 CpbtyAxle5_SlipCtrlEna 3;
BA_ "GenSigCycleTime" SG_ 594 CpbtyAxle5_PadWearQltyLe 100;
BA_ "GenSigCycleTimeActive" SG_ 594 CpbtyAxle5_PadWearQltyLe 100;
BA_ "GenSigStartValue" SG_ 594 CpbtyAxle5_PadWearQltyLe 15;
BA_ "GenSigCycleTime" SG_ 594 CpbtyAxle6_BrkEgyCpctyQltyRi 100;
BA_ "GenSigCycleTimeActive" SG_ 594 CpbtyAxle6_BrkEgyCpctyQltyRi 100;
BA_ "GenSigStartValue" SG_ 594 CpbtyAxle6_BrkEgyCpctyQltyRi 15;
BA_ "GenSigCycleTime" SG_ 594 CpbtyAxle5_BrkEgyCpctyQltyLe 100;
BA_ "GenSigCycleTimeActive" SG_ 594 CpbtyAxle5_BrkEgyCpctyQltyLe 100;
BA_ "GenSigStartValue" SG_ 594 CpbtyAxle5_BrkEgyCpctyQltyLe 15;
BA_ "GenSigCycleTime" SG_ 594 CpbtyAxle6_PadWearQltyRi 100;
BA_ "GenSigCycleTimeActive" SG_ 594 CpbtyAxle6_PadWearQltyRi 100;
BA_ "GenSigStartValue" SG_ 594 CpbtyAxle6_PadWearQltyRi 15;
BA_ "GenSigCycleTime" SG_ 594 CpbtyAxle6_TqCpbtyMaxRi 100;
BA_ "GenSigCycleTimeActive" SG_ 594 CpbtyAxle6_TqCpbtyMaxRi 100;
BA_ "GenSigStartValue" SG_ 594 CpbtyAxle6_TqCpbtyMaxRi 1023;
BA_ "GenSigCycleTime" SG_ 594 CpbtyAxle4_TqCpbtyQltyLe 100;
BA_ "GenSigCycleTimeActive" SG_ 594 CpbtyAxle4_TqCpbtyQltyLe 100;
BA_ "GenSigStartValue" SG_ 594 CpbtyAxle4_TqCpbtyQltyLe 15;
BA_ "GenSigCycleTime" SG_ 594 CpbtyAxle4_SlipCtrlEna 100;
BA_ "GenSigCycleTimeActive" SG_ 594 CpbtyAxle4_SlipCtrlEna 100;
BA_ "GenSigStartValue" SG_ 594 CpbtyAxle4_SlipCtrlEna 3;
BA_ "GenSigCycleTime" SG_ 594 CpbtyAxle4_BrkEgyCpctyRi 100;
BA_ "GenSigCycleTimeActive" SG_ 594 CpbtyAxle4_BrkEgyCpctyRi 100;
BA_ "GenSigStartValue" SG_ 594 CpbtyAxle4_BrkEgyCpctyRi 255;
BA_ "GenSigCycleTime" SG_ 594 CpbtyAxle6_TqCpbtyQltyRi 100;
BA_ "GenSigCycleTimeActive" SG_ 594 CpbtyAxle6_TqCpbtyQltyRi 100;
BA_ "GenSigStartValue" SG_ 594 CpbtyAxle6_TqCpbtyQltyRi 15;
BA_ "GenSigCycleTime" SG_ 594 CpbtyAxle6_CRC 100;
BA_ "GenSigCycleTimeActive" SG_ 594 CpbtyAxle6_CRC 100;
BA_ "GenSigStartValue" SG_ 594 CpbtyAxle6_CRC 65535;
BA_ "E2EDataId" SG_ 594 CpbtyAxle6_CRC 194;
BA_ "E2EDataLength" SG_ 594 CpbtyAxle6_CRC 168;
BA_ "E2EProfile" SG_ 594 CpbtyAxle6_CRC "P05";
BA_ "GenSigCycleTime" SG_ 594 CpbtyAxle5_TqCpbtyRateQltyLe 100;
BA_ "GenSigCycleTimeActive" SG_ 594 CpbtyAxle5_TqCpbtyRateQltyLe 100;
BA_ "GenSigStartValue" SG_ 594 CpbtyAxle5_TqCpbtyRateQltyLe 15;
BA_ "GenSigCycleTime" SG_ 594 CpbtyAxle4_TqCpbtyMaxLe 100;
BA_ "GenSigCycleTimeActive" SG_ 594 CpbtyAxle4_TqCpbtyMaxLe 100;
BA_ "GenSigStartValue" SG_ 594 CpbtyAxle4_TqCpbtyMaxLe 1023;
BA_ "GenSigCycleTime" SG_ 594 CpbtyAxle4_PadWearRi 100;
BA_ "GenSigCycleTimeActive" SG_ 594 CpbtyAxle4_PadWearRi 100;
BA_ "GenSigStartValue" SG_ 594 CpbtyAxle4_PadWearRi 255;
BA_ "GenSigCycleTime" SG_ 594 CpbtyAxle6_TqCpbtyMinLe 100;
BA_ "GenSigCycleTimeActive" SG_ 594 CpbtyAxle6_TqCpbtyMinLe 100;
BA_ "GenSigStartValue" SG_ 594 CpbtyAxle6_TqCpbtyMinLe 1023;
BA_ "GenSigCycleTime" SG_ 594 CpbtyAxle4_CRC 100;
BA_ "GenSigCycleTimeActive" SG_ 594 CpbtyAxle4_CRC 100;
BA_ "GenSigStartValue" SG_ 594 CpbtyAxle4_CRC 65535;
BA_ "E2EDataId" SG_ 594 CpbtyAxle4_CRC 192;
BA_ "E2EDataLength" SG_ 594 CpbtyAxle4_CRC 168;
BA_ "E2EProfile" SG_ 594 CpbtyAxle4_CRC "P05";
BA_ "GenSigCycleTime" SG_ 594 CpbtyAxle4_SqC 100;
BA_ "GenSigCycleTimeActive" SG_ 594 CpbtyAxle4_SqC 100;
BA_ "GenSigStartValue" SG_ 594 CpbtyAxle4_SqC 255;
BA_ "GenSigCycleTime" SG_ 594 CpbtyAxle5_TqCpbtyMinLe 100;
BA_ "GenSigCycleTimeActive" SG_ 594 CpbtyAxle5_TqCpbtyMinLe 100;
BA_ "GenSigStartValue" SG_ 594 CpbtyAxle5_TqCpbtyMinLe 1023;
BA_ "GenSigCycleTime" SG_ 594 CpbtyAxle6_PadWearQltyLe 100;
BA_ "GenSigCycleTimeActive" SG_ 594 CpbtyAxle6_PadWearQltyLe 100;
BA_ "GenSigStartValue" SG_ 594 CpbtyAxle6_PadWearQltyLe 15;
BA_ "GenSigCycleTime" SG_ 594 CpbtyAxle6_PadWearRi 100;
BA_ "GenSigCycleTimeActive" SG_ 594 CpbtyAxle6_PadWearRi 100;
BA_ "GenSigStartValue" SG_ 594 CpbtyAxle6_PadWearRi 255;
BA_ "GenSigCycleTime" SG_ 594 CpbtyAxle5_TqCpbtyRateQltyRi 100;
BA_ "GenSigCycleTimeActive" SG_ 594 CpbtyAxle5_TqCpbtyRateQltyRi 100;
BA_ "GenSigStartValue" SG_ 594 CpbtyAxle5_TqCpbtyRateQltyRi 15;
BA_ "GenSigCycleTime" SG_ 594 CpbtyAxle4_TqCpbtyQltyRi 100;
BA_ "GenSigCycleTimeActive" SG_ 594 CpbtyAxle4_TqCpbtyQltyRi 100;
BA_ "GenSigStartValue" SG_ 594 CpbtyAxle4_TqCpbtyQltyRi 15;
BA_ "GenSigCycleTime" SG_ 594 CpbtyAxle6_SlipCtrlEna 100;
BA_ "GenSigCycleTimeActive" SG_ 594 CpbtyAxle6_SlipCtrlEna 100;
BA_ "GenSigStartValue" SG_ 594 CpbtyAxle6_SlipCtrlEna 3;
BA_ "GenSigCycleTime" SG_ 594 CpbtyAxle5_TqCpbtyQltyRi 100;
BA_ "GenSigCycleTimeActive" SG_ 594 CpbtyAxle5_TqCpbtyQltyRi 100;
BA_ "GenSigStartValue" SG_ 594 CpbtyAxle5_TqCpbtyQltyRi 15;
BA_ "GenSigCycleTime" SG_ 594 CpbtyAxle4_BrkEgyCpctyQltyLe 100;
BA_ "GenSigCycleTimeActive" SG_ 594 CpbtyAxle4_BrkEgyCpctyQltyLe 100;
BA_ "GenSigStartValue" SG_ 594 CpbtyAxle4_BrkEgyCpctyQltyLe 15;
BA_ "GenSigCycleTime" SG_ 594 CpbtyAxle4_TqCpbtyMinLe 100;
BA_ "GenSigCycleTimeActive" SG_ 594 CpbtyAxle4_TqCpbtyMinLe 100;
BA_ "GenSigStartValue" SG_ 594 CpbtyAxle4_TqCpbtyMinLe 1023;
BA_ "GenSigCycleTime" SG_ 594 CpbtyAxle5_TqCpbtyMinRi 100;
BA_ "GenSigCycleTimeActive" SG_ 594 CpbtyAxle5_TqCpbtyMinRi 100;
BA_ "GenSigStartValue" SG_ 594 CpbtyAxle5_TqCpbtyMinRi 1023;
BA_ "GenSigCycleTime" SG_ 594 CpbtyAxle6_SqC 100;
BA_ "GenSigCycleTimeActive" SG_ 594 CpbtyAxle6_SqC 100;
BA_ "GenSigStartValue" SG_ 594 CpbtyAxle6_SqC 255;
BA_ "GenSigCycleTime" SG_ 594 CpbtyAxle6_TqCpbtyRateDecRi 100;
BA_ "GenSigCycleTimeActive" SG_ 594 CpbtyAxle6_TqCpbtyRateDecRi 100;
BA_ "GenSigStartValue" SG_ 594 CpbtyAxle6_TqCpbtyRateDecRi 255;
BA_ "GenSigCycleTime" SG_ 594 CpbtyAxle6_TqCpbtyRateIncLeLe 100;
BA_ "GenSigCycleTimeActive" SG_ 594 CpbtyAxle6_TqCpbtyRateIncLeLe 100;
BA_ "GenSigStartValue" SG_ 594 CpbtyAxle6_TqCpbtyRateIncLeLe 255;
BA_ "GenSigCycleTime" SG_ 594 CpbtyAxle4_TqCpbtyRateDecLe 100;
BA_ "GenSigCycleTimeActive" SG_ 594 CpbtyAxle4_TqCpbtyRateDecLe 100;
BA_ "GenSigStartValue" SG_ 594 CpbtyAxle4_TqCpbtyRateDecLe 255;
BA_ "GenSigCycleTime" SG_ 594 CpbtyAxle4_TqCpbtyRateQltyRi 100;
BA_ "GenSigCycleTimeActive" SG_ 594 CpbtyAxle4_TqCpbtyRateQltyRi 100;
BA_ "GenSigStartValue" SG_ 594 CpbtyAxle4_TqCpbtyRateQltyRi 15;
BA_ "GenSigCycleTime" SG_ 594 CpbtyAxle4_BrkEgyCpctyLe 100;
BA_ "GenSigCycleTimeActive" SG_ 594 CpbtyAxle4_BrkEgyCpctyLe 100;
BA_ "GenSigStartValue" SG_ 594 CpbtyAxle4_BrkEgyCpctyLe 255;
BA_ "GenSigCycleTime" SG_ 594 CpbtyAxle4_TqCpbtyMaxRi 100;
BA_ "GenSigCycleTimeActive" SG_ 594 CpbtyAxle4_TqCpbtyMaxRi 100;
BA_ "GenSigStartValue" SG_ 594 CpbtyAxle4_TqCpbtyMaxRi 1023;
BA_ "GenSigCycleTime" SG_ 594 CpbtyAxle6_TqCpbtyMaxLe 100;
BA_ "GenSigCycleTimeActive" SG_ 594 CpbtyAxle6_TqCpbtyMaxLe 100;
BA_ "GenSigStartValue" SG_ 594 CpbtyAxle6_TqCpbtyMaxLe 1023;
BA_ "GenSigCycleTime" SG_ 594 CpbtyAxle5_TqCpbtyRateIncLeLe 100;
BA_ "GenSigCycleTimeActive" SG_ 594 CpbtyAxle5_TqCpbtyRateIncLeLe 100;
BA_ "GenSigStartValue" SG_ 594 CpbtyAxle5_TqCpbtyRateIncLeLe 255;
BA_ "GenSigCycleTime" SG_ 594 CpbtyAxle5_PadWearQltyRi 100;
BA_ "GenSigCycleTimeActive" SG_ 594 CpbtyAxle5_PadWearQltyRi 100;
BA_ "GenSigStartValue" SG_ 594 CpbtyAxle5_PadWearQltyRi 15;
BA_ "GenSigCycleTime" SG_ 594 CpbtyAxle6_BrkEgyCpctyQltyLe 100;
BA_ "GenSigCycleTimeActive" SG_ 594 CpbtyAxle6_BrkEgyCpctyQltyLe 100;
BA_ "GenSigStartValue" SG_ 594 CpbtyAxle6_BrkEgyCpctyQltyLe 15;
BA_ "GenSigCycleTime" SG_ 594 CpbtyAxle5_TqCpbtyRateDecRi 100;
BA_ "GenSigCycleTimeActive" SG_ 594 CpbtyAxle5_TqCpbtyRateDecRi 100;
BA_ "GenSigStartValue" SG_ 594 CpbtyAxle5_TqCpbtyRateDecRi 255;
BA_ "GenSigCycleTime" SG_ 594 CpbtyAxle6_TqCpbtyQltyLe 100;
BA_ "GenSigCycleTimeActive" SG_ 594 CpbtyAxle6_TqCpbtyQltyLe 100;
BA_ "GenSigStartValue" SG_ 594 CpbtyAxle6_TqCpbtyQltyLe 15;
BA_ "GenSigCycleTime" SG_ 594 CpbtyAxle5_SqC 100;
BA_ "GenSigCycleTimeActive" SG_ 594 CpbtyAxle5_SqC 100;
BA_ "GenSigStartValue" SG_ 594 CpbtyAxle5_SqC 255;
BA_ "GenSigCycleTime" SG_ 594 CpbtyAxle4_TqCpbtyRateIncLeRi 100;
BA_ "GenSigCycleTimeActive" SG_ 594 CpbtyAxle4_TqCpbtyRateIncLeRi 100;
BA_ "GenSigStartValue" SG_ 594 CpbtyAxle4_TqCpbtyRateIncLeRi 255;
BA_ "GenSigCycleTime" SG_ 594 CpbtyAxle6_BrkEgyCpctyLe 100;
BA_ "GenSigCycleTimeActive" SG_ 594 CpbtyAxle6_BrkEgyCpctyLe 100;
BA_ "GenSigStartValue" SG_ 594 CpbtyAxle6_BrkEgyCpctyLe 255;
BA_ "GenSigCycleTime" SG_ 594 CpbtyAxle5_BrkEgyCpctyRi 100;
BA_ "GenSigCycleTimeActive" SG_ 594 CpbtyAxle5_BrkEgyCpctyRi 100;
BA_ "GenSigStartValue" SG_ 594 CpbtyAxle5_BrkEgyCpctyRi 255;
BA_ "GenSigCycleTime" SG_ 594 CpbtyAxle5_BrkEgyCpctyQltyRi 100;
BA_ "GenSigCycleTimeActive" SG_ 594 CpbtyAxle5_BrkEgyCpctyQltyRi 100;
BA_ "GenSigStartValue" SG_ 594 CpbtyAxle5_BrkEgyCpctyQltyRi 15;
BA_ "GenSigCycleTime" SG_ 594 CpbtyAxle6_PadWearLe 100;
BA_ "GenSigCycleTimeActive" SG_ 594 CpbtyAxle6_PadWearLe 100;
BA_ "GenSigStartValue" SG_ 594 CpbtyAxle6_PadWearLe 255;
BA_ "GenSigCycleTime" SG_ 594 CpbtyAxle4_PadWearLe 100;
BA_ "GenSigCycleTimeActive" SG_ 594 CpbtyAxle4_PadWearLe 100;
BA_ "GenSigStartValue" SG_ 594 CpbtyAxle4_PadWearLe 255;
BA_ "GenSigCycleTime" SG_ 594 CpbtyAxle4_PadWearQltyRi 100;
BA_ "GenSigCycleTimeActive" SG_ 594 CpbtyAxle4_PadWearQltyRi 100;
BA_ "GenSigStartValue" SG_ 594 CpbtyAxle4_PadWearQltyRi 15;
BA_ "GenSigCycleTime" SG_ 594 CpbtyAxle4_TqCpbtyRateIncLeLe 100;
BA_ "GenSigCycleTimeActive" SG_ 594 CpbtyAxle4_TqCpbtyRateIncLeLe 100;
BA_ "GenSigStartValue" SG_ 594 CpbtyAxle4_TqCpbtyRateIncLeLe 255;
BA_ "GenSigCycleTime" SG_ 594 CpbtyAxle5_PadWearLe 100;
BA_ "GenSigCycleTimeActive" SG_ 594 CpbtyAxle5_PadWearLe 100;
BA_ "GenSigStartValue" SG_ 594 CpbtyAxle5_PadWearLe 255;
BA_ "GenSigCycleTime" SG_ 594 CpbtyAxle4_PadWearQltyLe 100;
BA_ "GenSigCycleTimeActive" SG_ 594 CpbtyAxle4_PadWearQltyLe 100;
BA_ "GenSigStartValue" SG_ 594 CpbtyAxle4_PadWearQltyLe 15;
BA_ "GenSigCycleTime" SG_ 592 CpbtyAxle3_BrkEgyCpctyQltyLe 100;
BA_ "GenSigCycleTimeActive" SG_ 592 CpbtyAxle3_BrkEgyCpctyQltyLe 100;
BA_ "GenSigStartValue" SG_ 592 CpbtyAxle3_BrkEgyCpctyQltyLe 15;
BA_ "GenSigCycleTime" SG_ 592 CpbtyAxle3_TqCpbtyRateIncLeLe 100;
BA_ "GenSigCycleTimeActive" SG_ 592 CpbtyAxle3_TqCpbtyRateIncLeLe 100;
BA_ "GenSigStartValue" SG_ 592 CpbtyAxle3_TqCpbtyRateIncLeLe 255;
BA_ "GenSigCycleTime" SG_ 592 CpbtyAxle3_TqCpbtyRateQltyRi 100;
BA_ "GenSigCycleTimeActive" SG_ 592 CpbtyAxle3_TqCpbtyRateQltyRi 100;
BA_ "GenSigStartValue" SG_ 592 CpbtyAxle3_TqCpbtyRateQltyRi 15;
BA_ "GenSigCycleTime" SG_ 592 CpbtyAxle1_PadWearQltyLe 100;
BA_ "GenSigCycleTimeActive" SG_ 592 CpbtyAxle1_PadWearQltyLe 100;
BA_ "GenSigStartValue" SG_ 592 CpbtyAxle1_PadWearQltyLe 15;
BA_ "GenSigCycleTime" SG_ 592 CpbtyAxle1_SlipCtrlEna 100;
BA_ "GenSigCycleTimeActive" SG_ 592 CpbtyAxle1_SlipCtrlEna 100;
BA_ "GenSigStartValue" SG_ 592 CpbtyAxle1_SlipCtrlEna 3;
BA_ "GenSigCycleTime" SG_ 592 CpbtyAxle2_PadWearRi 100;
BA_ "GenSigCycleTimeActive" SG_ 592 CpbtyAxle2_PadWearRi 100;
BA_ "GenSigStartValue" SG_ 592 CpbtyAxle2_PadWearRi 255;
BA_ "GenSigCycleTime" SG_ 592 CpbtyAxle3_TqCpbtyRateQltyLe 100;
BA_ "GenSigCycleTimeActive" SG_ 592 CpbtyAxle3_TqCpbtyRateQltyLe 100;
BA_ "GenSigStartValue" SG_ 592 CpbtyAxle3_TqCpbtyRateQltyLe 15;
BA_ "GenSigCycleTime" SG_ 592 CpbtyAxle1_BrkEgyCpctyQltyRi 100;
BA_ "GenSigCycleTimeActive" SG_ 592 CpbtyAxle1_BrkEgyCpctyQltyRi 100;
BA_ "GenSigStartValue" SG_ 592 CpbtyAxle1_BrkEgyCpctyQltyRi 15;
BA_ "GenSigCycleTime" SG_ 592 CpbtyAxle2_TqCpbtyMaxRi 100;
BA_ "GenSigCycleTimeActive" SG_ 592 CpbtyAxle2_TqCpbtyMaxRi 100;
BA_ "GenSigStartValue" SG_ 592 CpbtyAxle2_TqCpbtyMaxRi 1023;
BA_ "GenSigCycleTime" SG_ 592 CpbtyAxle2_TqCpbtyMinLe 100;
BA_ "GenSigCycleTimeActive" SG_ 592 CpbtyAxle2_TqCpbtyMinLe 100;
BA_ "GenSigStartValue" SG_ 592 CpbtyAxle2_TqCpbtyMinLe 1023;
BA_ "GenSigCycleTime" SG_ 592 CpbtyAxle2_BrkEgyCpctyQltyLe 100;
BA_ "GenSigCycleTimeActive" SG_ 592 CpbtyAxle2_BrkEgyCpctyQltyLe 100;
BA_ "GenSigStartValue" SG_ 592 CpbtyAxle2_BrkEgyCpctyQltyLe 15;
BA_ "GenSigCycleTime" SG_ 592 CpbtyAxle2_TqCpbtyRateDecLe 100;
BA_ "GenSigCycleTimeActive" SG_ 592 CpbtyAxle2_TqCpbtyRateDecLe 100;
BA_ "GenSigStartValue" SG_ 592 CpbtyAxle2_TqCpbtyRateDecLe 255;
BA_ "GenSigCycleTime" SG_ 592 CpbtyAxle3_SlipCtrlEna 100;
BA_ "GenSigCycleTimeActive" SG_ 592 CpbtyAxle3_SlipCtrlEna 100;
BA_ "GenSigStartValue" SG_ 592 CpbtyAxle3_SlipCtrlEna 3;
BA_ "GenSigCycleTime" SG_ 592 CpbtyAxle3_TqCpbtyQltyLe 100;
BA_ "GenSigCycleTimeActive" SG_ 592 CpbtyAxle3_TqCpbtyQltyLe 100;
BA_ "GenSigStartValue" SG_ 592 CpbtyAxle3_TqCpbtyQltyLe 15;
BA_ "GenSigCycleTime" SG_ 592 CpbtyAxle3_BrkEgyCpctyRi 100;
BA_ "GenSigCycleTimeActive" SG_ 592 CpbtyAxle3_BrkEgyCpctyRi 100;
BA_ "GenSigStartValue" SG_ 592 CpbtyAxle3_BrkEgyCpctyRi 255;
BA_ "GenSigCycleTime" SG_ 592 CpbtyAxle1_SqC 100;
BA_ "GenSigCycleTimeActive" SG_ 592 CpbtyAxle1_SqC 100;
BA_ "GenSigStartValue" SG_ 592 CpbtyAxle1_SqC 255;
BA_ "GenSigCycleTime" SG_ 592 CpbtyAxle1_TqCpbtyQltyLe 100;
BA_ "GenSigCycleTimeActive" SG_ 592 CpbtyAxle1_TqCpbtyQltyLe 100;
BA_ "GenSigStartValue" SG_ 592 CpbtyAxle1_TqCpbtyQltyLe 15;
BA_ "GenSigCycleTime" SG_ 592 CpbtyAxle2_TqCpbtyRateDecRi 100;
BA_ "GenSigCycleTimeActive" SG_ 592 CpbtyAxle2_TqCpbtyRateDecRi 100;
BA_ "GenSigStartValue" SG_ 592 CpbtyAxle2_TqCpbtyRateDecRi 255;
BA_ "GenSigCycleTime" SG_ 592 CpbtyAxle1_TqCpbtyRateIncLeLe 100;
BA_ "GenSigCycleTimeActive" SG_ 592 CpbtyAxle1_TqCpbtyRateIncLeLe 100;
BA_ "GenSigStartValue" SG_ 592 CpbtyAxle1_TqCpbtyRateIncLeLe 255;
BA_ "GenSigCycleTime" SG_ 592 CpbtyAxle3_BrkEgyCpctyQltyRi 100;
BA_ "GenSigCycleTimeActive" SG_ 592 CpbtyAxle3_BrkEgyCpctyQltyRi 100;
BA_ "GenSigStartValue" SG_ 592 CpbtyAxle3_BrkEgyCpctyQltyRi 15;
BA_ "GenSigCycleTime" SG_ 592 CpbtyAxle3_TqCpbtyRateDecLe 100;
BA_ "GenSigCycleTimeActive" SG_ 592 CpbtyAxle3_TqCpbtyRateDecLe 100;
BA_ "GenSigStartValue" SG_ 592 CpbtyAxle3_TqCpbtyRateDecLe 255;
BA_ "GenSigCycleTime" SG_ 592 CpbtyAxle3_TqCpbtyRateDecRi 100;
BA_ "GenSigCycleTimeActive" SG_ 592 CpbtyAxle3_TqCpbtyRateDecRi 100;
BA_ "GenSigStartValue" SG_ 592 CpbtyAxle3_TqCpbtyRateDecRi 255;
BA_ "GenSigCycleTime" SG_ 592 CpbtyAxle1_PadWearRi 100;
BA_ "GenSigCycleTimeActive" SG_ 592 CpbtyAxle1_PadWearRi 100;
BA_ "GenSigStartValue" SG_ 592 CpbtyAxle1_PadWearRi 255;
BA_ "GenSigCycleTime" SG_ 592 CpbtyAxle2_TqCpbtyMaxLe 100;
BA_ "GenSigCycleTimeActive" SG_ 592 CpbtyAxle2_TqCpbtyMaxLe 100;
BA_ "GenSigStartValue" SG_ 592 CpbtyAxle2_TqCpbtyMaxLe 1023;
BA_ "GenSigCycleTime" SG_ 592 CpbtyAxle3_TqCpbtyQltyRi 100;
BA_ "GenSigCycleTimeActive" SG_ 592 CpbtyAxle3_TqCpbtyQltyRi 100;
BA_ "GenSigStartValue" SG_ 592 CpbtyAxle3_TqCpbtyQltyRi 15;
BA_ "GenSigCycleTime" SG_ 592 CpbtyAxle1_TqCpbtyRateDecLe 100;
BA_ "GenSigCycleTimeActive" SG_ 592 CpbtyAxle1_TqCpbtyRateDecLe 100;
BA_ "GenSigStartValue" SG_ 592 CpbtyAxle1_TqCpbtyRateDecLe 255;
BA_ "GenSigCycleTime" SG_ 592 CpbtyAxle1_BrkEgyCpctyRi 100;
BA_ "GenSigCycleTimeActive" SG_ 592 CpbtyAxle1_BrkEgyCpctyRi 100;
BA_ "GenSigStartValue" SG_ 592 CpbtyAxle1_BrkEgyCpctyRi 255;
BA_ "GenSigCycleTime" SG_ 592 CpbtyAxle3_TqCpbtyMinLe 100;
BA_ "GenSigCycleTimeActive" SG_ 592 CpbtyAxle3_TqCpbtyMinLe 100;
BA_ "GenSigStartValue" SG_ 592 CpbtyAxle3_TqCpbtyMinLe 1023;
BA_ "GenSigCycleTime" SG_ 592 CpbtyAxle3_TqCpbtyMinRi 100;
BA_ "GenSigCycleTimeActive" SG_ 592 CpbtyAxle3_TqCpbtyMinRi 100;
BA_ "GenSigStartValue" SG_ 592 CpbtyAxle3_TqCpbtyMinRi 1023;
BA_ "GenSigCycleTime" SG_ 592 CpbtyAxle2_BrkEgyCpctyQltyRi 100;
BA_ "GenSigCycleTimeActive" SG_ 592 CpbtyAxle2_BrkEgyCpctyQltyRi 100;
BA_ "GenSigStartValue" SG_ 592 CpbtyAxle2_BrkEgyCpctyQltyRi 15;
BA_ "GenSigCycleTime" SG_ 592 CpbtyAxle2_PadWearLe 100;
BA_ "GenSigCycleTimeActive" SG_ 592 CpbtyAxle2_PadWearLe 100;
BA_ "GenSigStartValue" SG_ 592 CpbtyAxle2_PadWearLe 255;
BA_ "GenSigCycleTime" SG_ 592 CpbtyAxle2_TqCpbtyQltyRi 100;
BA_ "GenSigCycleTimeActive" SG_ 592 CpbtyAxle2_TqCpbtyQltyRi 100;
BA_ "GenSigStartValue" SG_ 592 CpbtyAxle2_TqCpbtyQltyRi 15;
BA_ "GenSigCycleTime" SG_ 592 CpbtyAxle2_PadWearQltyRi 100;
BA_ "GenSigCycleTimeActive" SG_ 592 CpbtyAxle2_PadWearQltyRi 100;
BA_ "GenSigStartValue" SG_ 592 CpbtyAxle2_PadWearQltyRi 15;
BA_ "GenSigCycleTime" SG_ 592 CpbtyAxle3_PadWearRi 100;
BA_ "GenSigCycleTimeActive" SG_ 592 CpbtyAxle3_PadWearRi 100;
BA_ "GenSigStartValue" SG_ 592 CpbtyAxle3_PadWearRi 255;
BA_ "GenSigCycleTime" SG_ 592 CpbtyAxle3_PadWearQltyRi 100;
BA_ "GenSigCycleTimeActive" SG_ 592 CpbtyAxle3_PadWearQltyRi 100;
BA_ "GenSigStartValue" SG_ 592 CpbtyAxle3_PadWearQltyRi 15;
BA_ "GenSigCycleTime" SG_ 592 CpbtyAxle1_TqCpbtyMaxRi 100;
BA_ "GenSigCycleTimeActive" SG_ 592 CpbtyAxle1_TqCpbtyMaxRi 100;
BA_ "GenSigStartValue" SG_ 592 CpbtyAxle1_TqCpbtyMaxRi 1023;
BA_ "GenSigCycleTime" SG_ 592 CpbtyAxle2_TqCpbtyRateQltyRi 100;
BA_ "GenSigCycleTimeActive" SG_ 592 CpbtyAxle2_TqCpbtyRateQltyRi 100;
BA_ "GenSigStartValue" SG_ 592 CpbtyAxle2_TqCpbtyRateQltyRi 15;
BA_ "GenSigCycleTime" SG_ 592 CpbtyAxle1_BrkEgyCpctyLe 100;
BA_ "GenSigCycleTimeActive" SG_ 592 CpbtyAxle1_BrkEgyCpctyLe 100;
BA_ "GenSigStartValue" SG_ 592 CpbtyAxle1_BrkEgyCpctyLe 255;
BA_ "GenSigCycleTime" SG_ 592 CpbtyAxle2_SlipCtrlEna 100;
BA_ "GenSigCycleTimeActive" SG_ 592 CpbtyAxle2_SlipCtrlEna 100;
BA_ "GenSigStartValue" SG_ 592 CpbtyAxle2_SlipCtrlEna 3;
BA_ "GenSigCycleTime" SG_ 592 CpbtyAxle1_TqCpbtyRateIncLeRi 100;
BA_ "GenSigCycleTimeActive" SG_ 592 CpbtyAxle1_TqCpbtyRateIncLeRi 100;
BA_ "GenSigStartValue" SG_ 592 CpbtyAxle1_TqCpbtyRateIncLeRi 255;
BA_ "GenSigCycleTime" SG_ 592 CpbtyAxle2_TqCpbtyMinRi 100;
BA_ "GenSigCycleTimeActive" SG_ 592 CpbtyAxle2_TqCpbtyMinRi 100;
BA_ "GenSigStartValue" SG_ 592 CpbtyAxle2_TqCpbtyMinRi 1023;
BA_ "GenSigCycleTime" SG_ 592 CpbtyAxle3_TqCpbtyMaxLe 100;
BA_ "GenSigCycleTimeActive" SG_ 592 CpbtyAxle3_TqCpbtyMaxLe 100;
BA_ "GenSigStartValue" SG_ 592 CpbtyAxle3_TqCpbtyMaxLe 1023;
BA_ "GenSigCycleTime" SG_ 592 CpbtyAxle1_TqCpbtyRateQltyRi 100;
BA_ "GenSigCycleTimeActive" SG_ 592 CpbtyAxle1_TqCpbtyRateQltyRi 100;
BA_ "GenSigStartValue" SG_ 592 CpbtyAxle1_TqCpbtyRateQltyRi 15;
BA_ "GenSigCycleTime" SG_ 592 CpbtyAxle1_CRC 100;
BA_ "GenSigCycleTimeActive" SG_ 592 CpbtyAxle1_CRC 100;
BA_ "GenSigStartValue" SG_ 592 CpbtyAxle1_CRC 65535;
BA_ "E2EDataId" SG_ 592 CpbtyAxle1_CRC 189;
BA_ "E2EDataLength" SG_ 592 CpbtyAxle1_CRC 168;
BA_ "E2EProfile" SG_ 592 CpbtyAxle1_CRC "P05";
BA_ "GenSigCycleTime" SG_ 592 CpbtyAxle1_PadWearQltyRi 100;
BA_ "GenSigCycleTimeActive" SG_ 592 CpbtyAxle1_PadWearQltyRi 100;
BA_ "GenSigStartValue" SG_ 592 CpbtyAxle1_PadWearQltyRi 15;
BA_ "GenSigCycleTime" SG_ 592 CpbtyAxle2_CRC 100;
BA_ "GenSigCycleTimeActive" SG_ 592 CpbtyAxle2_CRC 100;
BA_ "GenSigStartValue" SG_ 592 CpbtyAxle2_CRC 65535;
BA_ "E2EDataId" SG_ 592 CpbtyAxle2_CRC 190;
BA_ "E2EDataLength" SG_ 592 CpbtyAxle2_CRC 168;
BA_ "E2EProfile" SG_ 592 CpbtyAxle2_CRC "P05";
BA_ "GenSigCycleTime" SG_ 592 CpbtyAxle2_SqC 100;
BA_ "GenSigCycleTimeActive" SG_ 592 CpbtyAxle2_SqC 100;
BA_ "GenSigStartValue" SG_ 592 CpbtyAxle2_SqC 255;
BA_ "GenSigCycleTime" SG_ 592 CpbtyAxle2_TqCpbtyRateIncLeLe 100;
BA_ "GenSigCycleTimeActive" SG_ 592 CpbtyAxle2_TqCpbtyRateIncLeLe 100;
BA_ "GenSigStartValue" SG_ 592 CpbtyAxle2_TqCpbtyRateIncLeLe 255;
BA_ "GenSigCycleTime" SG_ 592 CpbtyAxle2_TqCpbtyRateIncLeRi 100;
BA_ "GenSigCycleTimeActive" SG_ 592 CpbtyAxle2_TqCpbtyRateIncLeRi 100;
BA_ "GenSigStartValue" SG_ 592 CpbtyAxle2_TqCpbtyRateIncLeRi 255;
BA_ "GenSigCycleTime" SG_ 592 CpbtyAxle2_BrkEgyCpctyLe 100;
BA_ "GenSigCycleTimeActive" SG_ 592 CpbtyAxle2_BrkEgyCpctyLe 100;
BA_ "GenSigStartValue" SG_ 592 CpbtyAxle2_BrkEgyCpctyLe 255;
BA_ "GenSigCycleTime" SG_ 592 CpbtyAxle1_TqCpbtyRateDecRi 100;
BA_ "GenSigCycleTimeActive" SG_ 592 CpbtyAxle1_TqCpbtyRateDecRi 100;
BA_ "GenSigStartValue" SG_ 592 CpbtyAxle1_TqCpbtyRateDecRi 255;
BA_ "GenSigCycleTime" SG_ 592 CpbtyAxle3_TqCpbtyMaxRi 100;
BA_ "GenSigCycleTimeActive" SG_ 592 CpbtyAxle3_TqCpbtyMaxRi 100;
BA_ "GenSigStartValue" SG_ 592 CpbtyAxle3_TqCpbtyMaxRi 1023;
BA_ "GenSigCycleTime" SG_ 592 CpbtyAxle3_PadWearQltyLe 100;
BA_ "GenSigCycleTimeActive" SG_ 592 CpbtyAxle3_PadWearQltyLe 100;
BA_ "GenSigStartValue" SG_ 592 CpbtyAxle3_PadWearQltyLe 15;
BA_ "GenSigCycleTime" SG_ 592 CpbtyAxle3_PadWearLe 100;
BA_ "GenSigCycleTimeActive" SG_ 592 CpbtyAxle3_PadWearLe 100;
BA_ "GenSigStartValue" SG_ 592 CpbtyAxle3_PadWearLe 255;
BA_ "GenSigCycleTime" SG_ 592 CpbtyAxle1_TqCpbtyRateQltyLe 100;
BA_ "GenSigCycleTimeActive" SG_ 592 CpbtyAxle1_TqCpbtyRateQltyLe 100;
BA_ "GenSigStartValue" SG_ 592 CpbtyAxle1_TqCpbtyRateQltyLe 15;
BA_ "GenSigCycleTime" SG_ 592 CpbtyAxle1_PadWearLe 100;
BA_ "GenSigCycleTimeActive" SG_ 592 CpbtyAxle1_PadWearLe 100;
BA_ "GenSigStartValue" SG_ 592 CpbtyAxle1_PadWearLe 255;
BA_ "GenSigCycleTime" SG_ 592 CpbtyAxle1_TqCpbtyMinRi 100;
BA_ "GenSigCycleTimeActive" SG_ 592 CpbtyAxle1_TqCpbtyMinRi 100;
BA_ "GenSigStartValue" SG_ 592 CpbtyAxle1_TqCpbtyMinRi 1023;
BA_ "GenSigCycleTime" SG_ 592 CpbtyAxle1_TqCpbtyQltyRi 100;
BA_ "GenSigCycleTimeActive" SG_ 592 CpbtyAxle1_TqCpbtyQltyRi 100;
BA_ "GenSigStartValue" SG_ 592 CpbtyAxle1_TqCpbtyQltyRi 15;
BA_ "GenSigCycleTime" SG_ 592 CpbtyAxle3_BrkEgyCpctyLe 100;
BA_ "GenSigCycleTimeActive" SG_ 592 CpbtyAxle3_BrkEgyCpctyLe 100;
BA_ "GenSigStartValue" SG_ 592 CpbtyAxle3_BrkEgyCpctyLe 255;
BA_ "GenSigCycleTime" SG_ 592 CpbtyAxle3_TqCpbtyRateIncLeRi 100;
BA_ "GenSigCycleTimeActive" SG_ 592 CpbtyAxle3_TqCpbtyRateIncLeRi 100;
BA_ "GenSigStartValue" SG_ 592 CpbtyAxle3_TqCpbtyRateIncLeRi 255;
BA_ "GenSigCycleTime" SG_ 592 CpbtyAxle1_TqCpbtyMinLe 100;
BA_ "GenSigCycleTimeActive" SG_ 592 CpbtyAxle1_TqCpbtyMinLe 100;
BA_ "GenSigStartValue" SG_ 592 CpbtyAxle1_TqCpbtyMinLe 1023;
BA_ "GenSigCycleTime" SG_ 592 CpbtyAxle2_TqCpbtyQltyLe 100;
BA_ "GenSigCycleTimeActive" SG_ 592 CpbtyAxle2_TqCpbtyQltyLe 100;
BA_ "GenSigStartValue" SG_ 592 CpbtyAxle2_TqCpbtyQltyLe 15;
BA_ "GenSigCycleTime" SG_ 592 CpbtyAxle2_TqCpbtyRateQltyLe 100;
BA_ "GenSigCycleTimeActive" SG_ 592 CpbtyAxle2_TqCpbtyRateQltyLe 100;
BA_ "GenSigStartValue" SG_ 592 CpbtyAxle2_TqCpbtyRateQltyLe 15;
BA_ "GenSigCycleTime" SG_ 592 CpbtyAxle2_BrkEgyCpctyRi 100;
BA_ "GenSigCycleTimeActive" SG_ 592 CpbtyAxle2_BrkEgyCpctyRi 100;
BA_ "GenSigStartValue" SG_ 592 CpbtyAxle2_BrkEgyCpctyRi 255;
BA_ "GenSigCycleTime" SG_ 592 CpbtyAxle1_BrkEgyCpctyQltyLe 100;
BA_ "GenSigCycleTimeActive" SG_ 592 CpbtyAxle1_BrkEgyCpctyQltyLe 100;
BA_ "GenSigStartValue" SG_ 592 CpbtyAxle1_BrkEgyCpctyQltyLe 15;
BA_ "GenSigCycleTime" SG_ 592 CpbtyAxle2_PadWearQltyLe 100;
BA_ "GenSigCycleTimeActive" SG_ 592 CpbtyAxle2_PadWearQltyLe 100;
BA_ "GenSigStartValue" SG_ 592 CpbtyAxle2_PadWearQltyLe 15;
BA_ "GenSigCycleTime" SG_ 592 CpbtyAxle1_TqCpbtyMaxLe 100;
BA_ "GenSigCycleTimeActive" SG_ 592 CpbtyAxle1_TqCpbtyMaxLe 100;
BA_ "GenSigStartValue" SG_ 592 CpbtyAxle1_TqCpbtyMaxLe 1023;
BA_ "GenSigCycleTime" SG_ 592 CpbtyAxle3_CRC 100;
BA_ "GenSigCycleTimeActive" SG_ 592 CpbtyAxle3_CRC 100;
BA_ "GenSigStartValue" SG_ 592 CpbtyAxle3_CRC 65535;
BA_ "E2EDataId" SG_ 592 CpbtyAxle3_CRC 191;
BA_ "E2EDataLength" SG_ 592 CpbtyAxle3_CRC 168;
BA_ "E2EProfile" SG_ 592 CpbtyAxle3_CRC "P05";
BA_ "GenSigCycleTime" SG_ 592 CpbtyAxle3_SqC 100;
BA_ "GenSigCycleTimeActive" SG_ 592 CpbtyAxle3_SqC 100;
BA_ "GenSigStartValue" SG_ 592 CpbtyAxle3_SqC 255;
BA_ "GenSigCycleTime" SG_ 1105 TrailerLiftAxlePos 100;
BA_ "GenSigCycleTimeActive" SG_ 1105 TrailerLiftAxlePos 100;
BA_ "GenSigStartValue" SG_ 1105 TrailerLiftAxlePos 3;
BA_ "GenSigMaxLatency" SG_ 1105 TrailerLiftAxlePos 100;
BA_ "GenSigCycleTime" SG_ 1105 XBRSystemState 100;
BA_ "GenSigCycleTimeActive" SG_ 1105 XBRSystemState 100;
BA_ "GenSigStartValue" SG_ 1105 XBRSystemState 3;
BA_ "GenSigMaxLatency" SG_ 1105 XBRSystemState 100;
BA_ "GenSigCycleTime" SG_ 1105 XPRRequest 100;
BA_ "GenSigCycleTimeActive" SG_ 1105 XPRRequest 100;
BA_ "GenSigStartValue" SG_ 1105 XPRRequest 255;
BA_ "GenSigMaxLatency" SG_ 1105 XPRRequest 100;
BA_ "GenSigCycleTime" SG_ 1105 TrailerCommunicationType 100;
BA_ "GenSigCycleTimeActive" SG_ 1105 TrailerCommunicationType 100;
BA_ "GenSigStartValue" SG_ 1105 TrailerCommunicationType 7;
BA_ "GenSigMaxLatency" SG_ 1105 TrailerCommunicationType 100;
BA_ "GenSigCycleTime" SG_ 439 ABSAxle5Active 100;
BA_ "GenSigCycleTimeActive" SG_ 439 ABSAxle5Active 100;
BA_ "GenSigStartValue" SG_ 439 ABSAxle5Active 3;
BA_ "GenSigMaxLatency" SG_ 439 ABSAxle5Active 20;
BA_ "GenSigCycleTime" SG_ 439 EACompound_CRC 100;
BA_ "GenSigCycleTimeActive" SG_ 439 EACompound_CRC 100;
BA_ "GenSigStartValue" SG_ 439 EACompound_CRC 255;
BA_ "GenSigMaxLatency" SG_ 439 EACompound_CRC 20;
BA_ "E2EDataId" SG_ 439 EACompound_CRC 106;
BA_ "E2EDataLength" SG_ 439 EACompound_CRC 24;
BA_ "E2EProfile" SG_ 439 EACompound_CRC "P01";
BA_ "GenSigCycleTime" SG_ 439 RrAxle1RtWhlBrakeApplPrsHiRng 100;
BA_ "GenSigCycleTimeActive" SG_ 439 RrAxle1RtWhlBrakeApplPrsHiRng 100;
BA_ "GenSigStartValue" SG_ 439 RrAxle1RtWhlBrakeApplPrsHiRng 255;
BA_ "GenSigMaxLatency" SG_ 439 RrAxle1RtWhlBrakeApplPrsHiRng 20;
BA_ "GenSigCycleTime" SG_ 439 RrAxle3RtWhlBrakeApplPrsHiRng 100;
BA_ "GenSigCycleTimeActive" SG_ 439 RrAxle3RtWhlBrakeApplPrsHiRng 100;
BA_ "GenSigStartValue" SG_ 439 RrAxle3RtWhlBrakeApplPrsHiRng 255;
BA_ "GenSigMaxLatency" SG_ 439 RrAxle3RtWhlBrakeApplPrsHiRng 20;
BA_ "GenSigCycleTime" SG_ 439 Trailer1LiftAxle2Pos 100;
BA_ "GenSigCycleTimeActive" SG_ 439 Trailer1LiftAxle2Pos 100;
BA_ "GenSigStartValue" SG_ 439 Trailer1LiftAxle2Pos 3;
BA_ "GenSigCycleTime" SG_ 439 Trailer1TractionHelp 100;
BA_ "GenSigCycleTimeActive" SG_ 439 Trailer1TractionHelp 100;
BA_ "GenSigStartValue" SG_ 439 Trailer1TractionHelp 3;
BA_ "GenSigCycleTime" SG_ 439 FrAxleRtWhlBrakeApplPrsHiRng 100;
BA_ "GenSigCycleTimeActive" SG_ 439 FrAxleRtWhlBrakeApplPrsHiRng 100;
BA_ "GenSigStartValue" SG_ 439 FrAxleRtWhlBrakeApplPrsHiRng 255;
BA_ "GenSigMaxLatency" SG_ 439 FrAxleRtWhlBrakeApplPrsHiRng 20;
BA_ "GenSigCycleTime" SG_ 439 EBSBrakeSwitch 100;
BA_ "GenSigCycleTimeActive" SG_ 439 EBSBrakeSwitch 100;
BA_ "GenSigStartValue" SG_ 439 EBSBrakeSwitch 3;
BA_ "GenSigCycleTime" SG_ 439 RrAxle3RightWheelRelativeSpeed 100;
BA_ "GenSigCycleTimeActive" SG_ 439 RrAxle3RightWheelRelativeSpeed 100;
BA_ "GenSigStartValue" SG_ 439 RrAxle3RightWheelRelativeSpeed 255;
BA_ "GenSigMaxLatency" SG_ 439 RrAxle3RightWheelRelativeSpeed 20;
BA_ "GenSigCycleTime" SG_ 439 EACompound_SystemState 100;
BA_ "GenSigCycleTimeActive" SG_ 439 EACompound_SystemState 100;
BA_ "GenSigStartValue" SG_ 439 EACompound_SystemState 3;
BA_ "GenSigMaxLatency" SG_ 439 EACompound_SystemState 20;
BA_ "GenSigCycleTime" SG_ 439 Trailer1LiftAxle1Pos 100;
BA_ "GenSigCycleTimeActive" SG_ 439 Trailer1LiftAxle1Pos 100;
BA_ "GenSigStartValue" SG_ 439 Trailer1LiftAxle1Pos 3;
BA_ "GenSigCycleTime" SG_ 439 EBSBrakePedalPosition 100;
BA_ "GenSigCycleTimeActive" SG_ 439 EBSBrakePedalPosition 100;
BA_ "GenSigStartValue" SG_ 439 EBSBrakePedalPosition 255;
BA_ "GenSigCycleTime" SG_ 439 AntiLockBrakingActive 100;
BA_ "GenSigCycleTimeActive" SG_ 439 AntiLockBrakingActive 100;
BA_ "GenSigStartValue" SG_ 439 AntiLockBrakingActive 3;
BA_ "GenSigMaxLatency" SG_ 439 AntiLockBrakingActive 20;
BA_ "GenSigCycleTime" SG_ 439 RrAxle3LeftWheelRelativeSpeed 100;
BA_ "GenSigCycleTimeActive" SG_ 439 RrAxle3LeftWheelRelativeSpeed 100;
BA_ "GenSigStartValue" SG_ 439 RrAxle3LeftWheelRelativeSpeed 255;
BA_ "GenSigMaxLatency" SG_ 439 RrAxle3LeftWheelRelativeSpeed 20;
BA_ "GenSigCycleTime" SG_ 439 StretchBrake_Stat 100;
BA_ "GenSigCycleTimeActive" SG_ 439 StretchBrake_Stat 100;
BA_ "GenSigStartValue" SG_ 439 StretchBrake_Stat 7;
BA_ "GenSigMaxLatency" SG_ 439 StretchBrake_Stat 20;
BA_ "GenSigCycleTime" SG_ 439 HillHolderMode 100;
BA_ "GenSigCycleTimeActive" SG_ 439 HillHolderMode 100;
BA_ "GenSigStartValue" SG_ 439 HillHolderMode 7;
BA_ "GenSigMaxLatency" SG_ 439 HillHolderMode 20;
BA_ "GenSigCycleTime" SG_ 439 ABSAxle4Active 100;
BA_ "GenSigCycleTimeActive" SG_ 439 ABSAxle4Active 100;
BA_ "GenSigStartValue" SG_ 439 ABSAxle4Active 3;
BA_ "GenSigMaxLatency" SG_ 439 ABSAxle4Active 20;
BA_ "GenSigCycleTime" SG_ 439 TrailerBrake_Stat 100;
BA_ "GenSigCycleTimeActive" SG_ 439 TrailerBrake_Stat 100;
BA_ "GenSigStartValue" SG_ 439 TrailerBrake_Stat 3;
BA_ "GenSigMaxLatency" SG_ 439 TrailerBrake_Stat 20;
BA_ "GenSigCycleTime" SG_ 439 CombinedWheelSpeed_CRC 100;
BA_ "GenSigCycleTimeActive" SG_ 439 CombinedWheelSpeed_CRC 100;
BA_ "GenSigStartValue" SG_ 439 CombinedWheelSpeed_CRC 255;
BA_ "GenSigMaxLatency" SG_ 439 CombinedWheelSpeed_CRC 20;
BA_ "E2EDataId" SG_ 439 CombinedWheelSpeed_CRC 221;
BA_ "E2EDataLength" SG_ 439 CombinedWheelSpeed_CRC 31;
BA_ "E2EProfile" SG_ 439 CombinedWheelSpeed_CRC "P01";
BA_ "GenSigCycleTime" SG_ 439 ABSAxle2Active 100;
BA_ "GenSigCycleTimeActive" SG_ 439 ABSAxle2Active 100;
BA_ "GenSigStartValue" SG_ 439 ABSAxle2Active 3;
BA_ "GenSigMaxLatency" SG_ 439 ABSAxle2Active 20;
BA_ "GenSigCycleTime" SG_ 439 TrailerEBSAmberWarning 100;
BA_ "GenSigCycleTimeActive" SG_ 439 TrailerEBSAmberWarning 100;
BA_ "GenSigStartValue" SG_ 439 TrailerEBSAmberWarning 3;
BA_ "GenSigMaxLatency" SG_ 439 TrailerEBSAmberWarning 20;
BA_ "GenSigCycleTime" SG_ 439 CombinedWheelSpeed_SqC 100;
BA_ "GenSigCycleTimeActive" SG_ 439 CombinedWheelSpeed_SqC 100;
BA_ "GenSigStartValue" SG_ 439 CombinedWheelSpeed_SqC 14;
BA_ "GenSigMaxLatency" SG_ 439 CombinedWheelSpeed_SqC 20;
BA_ "GenSigCycleTime" SG_ 439 ABSAxle1Active 100;
BA_ "GenSigCycleTimeActive" SG_ 439 ABSAxle1Active 100;
BA_ "GenSigStartValue" SG_ 439 ABSAxle1Active 3;
BA_ "GenSigMaxLatency" SG_ 439 ABSAxle1Active 20;
BA_ "GenSigCycleTime" SG_ 439 RrAxle2LtWhlBrakeApplPrsHiRng 100;
BA_ "GenSigCycleTimeActive" SG_ 439 RrAxle2LtWhlBrakeApplPrsHiRng 100;
BA_ "GenSigStartValue" SG_ 439 RrAxle2LtWhlBrakeApplPrsHiRng 255;
BA_ "GenSigMaxLatency" SG_ 439 RrAxle2LtWhlBrakeApplPrsHiRng 20;
BA_ "GenSigCycleTime" SG_ 439 ABSAxle3Active 100;
BA_ "GenSigCycleTimeActive" SG_ 439 ABSAxle3Active 100;
BA_ "GenSigStartValue" SG_ 439 ABSAxle3Active 3;
BA_ "GenSigMaxLatency" SG_ 439 ABSAxle3Active 20;
BA_ "GenSigCycleTime" SG_ 439 TCMSupply_SqC 100;
BA_ "GenSigCycleTimeActive" SG_ 439 TCMSupply_SqC 100;
BA_ "GenSigStartValue" SG_ 439 TCMSupply_SqC 14;
BA_ "GenSigMaxLatency" SG_ 439 TCMSupply_SqC 20;
BA_ "GenSigCycleTime" SG_ 439 PusherLiftAxleLoweringInhibit 100;
BA_ "GenSigCycleTimeActive" SG_ 439 PusherLiftAxleLoweringInhibit 100;
BA_ "GenSigStartValue" SG_ 439 PusherLiftAxleLoweringInhibit 3;
BA_ "GenSigCycleTime" SG_ 439 CombinedWheelSpeed_Quality 100;
BA_ "GenSigCycleTimeActive" SG_ 439 CombinedWheelSpeed_Quality 100;
BA_ "GenSigStartValue" SG_ 439 CombinedWheelSpeed_Quality 7;
BA_ "GenSigMaxLatency" SG_ 439 CombinedWheelSpeed_Quality 20;
BA_ "GenSigCycleTime" SG_ 439 SplitBoxDiffLockActvnFuncReq 100;
BA_ "GenSigCycleTimeActive" SG_ 439 SplitBoxDiffLockActvnFuncReq 100;
BA_ "GenSigStartValue" SG_ 439 SplitBoxDiffLockActvnFuncReq 3;
BA_ "GenSigMaxLatency" SG_ 439 SplitBoxDiffLockActvnFuncReq 20;
BA_ "GenSigCycleTime" SG_ 439 FrontParkBrakeOverrideStatus 100;
BA_ "GenSigCycleTimeActive" SG_ 439 FrontParkBrakeOverrideStatus 100;
BA_ "GenSigStartValue" SG_ 439 FrontParkBrakeOverrideStatus 3;
BA_ "GenSigMaxLatency" SG_ 439 FrontParkBrakeOverrideStatus 20;
BA_ "GenSigCycleTime" SG_ 439 SteerableLiftAxleLoweringInhib 100;
BA_ "GenSigCycleTimeActive" SG_ 439 SteerableLiftAxleLoweringInhib 100;
BA_ "GenSigStartValue" SG_ 439 SteerableLiftAxleLoweringInhib 3;
BA_ "GenSigMaxLatency" SG_ 439 SteerableLiftAxleLoweringInhib 20;
BA_ "GenSigCycleTime" SG_ 439 RrAxle3LtWhlBrakeApplPrsHiRng 100;
BA_ "GenSigCycleTimeActive" SG_ 439 RrAxle3LtWhlBrakeApplPrsHiRng 100;
BA_ "GenSigStartValue" SG_ 439 RrAxle3LtWhlBrakeApplPrsHiRng 255;
BA_ "GenSigMaxLatency" SG_ 439 RrAxle3LtWhlBrakeApplPrsHiRng 20;
BA_ "GenSigCycleTime" SG_ 439 EACompound_AppliedRatio 100;
BA_ "GenSigCycleTimeActive" SG_ 439 EACompound_AppliedRatio 100;
BA_ "GenSigStartValue" SG_ 439 EACompound_AppliedRatio 255;
BA_ "GenSigMaxLatency" SG_ 439 EACompound_AppliedRatio 20;
BA_ "GenSigCycleTime" SG_ 439 BrakingSystemPressureLim_rqst 100;
BA_ "GenSigCycleTimeActive" SG_ 439 BrakingSystemPressureLim_rqst 100;
BA_ "GenSigStartValue" SG_ 439 BrakingSystemPressureLim_rqst 3;
BA_ "GenSigMaxLatency" SG_ 439 BrakingSystemPressureLim_rqst 20;
BA_ "GenSigCycleTime" SG_ 439 RrAxle1LtWhlBrakeApplPrsHiRng 100;
BA_ "GenSigCycleTimeActive" SG_ 439 RrAxle1LtWhlBrakeApplPrsHiRng 100;
BA_ "GenSigStartValue" SG_ 439 RrAxle1LtWhlBrakeApplPrsHiRng 255;
BA_ "GenSigMaxLatency" SG_ 439 RrAxle1LtWhlBrakeApplPrsHiRng 20;
BA_ "GenSigCycleTime" SG_ 439 EACompound_SqC 100;
BA_ "GenSigCycleTimeActive" SG_ 439 EACompound_SqC 100;
BA_ "GenSigStartValue" SG_ 439 EACompound_SqC 14;
BA_ "GenSigMaxLatency" SG_ 439 EACompound_SqC 20;
BA_ "GenSigCycleTime" SG_ 439 TCMSupply_CRC 100;
BA_ "GenSigCycleTimeActive" SG_ 439 TCMSupply_CRC 100;
BA_ "GenSigStartValue" SG_ 439 TCMSupply_CRC 255;
BA_ "GenSigMaxLatency" SG_ 439 TCMSupply_CRC 20;
BA_ "E2EDataId" SG_ 439 TCMSupply_CRC 109;
BA_ "E2EDataLength" SG_ 439 TCMSupply_CRC 24;
BA_ "E2EProfile" SG_ 439 TCMSupply_CRC "P01";
BA_ "GenSigCycleTime" SG_ 439 TrailerControlPressure 100;
BA_ "GenSigCycleTimeActive" SG_ 439 TrailerControlPressure 100;
BA_ "GenSigStartValue" SG_ 439 TrailerControlPressure 255;
BA_ "GenSigMaxLatency" SG_ 439 TrailerControlPressure 20;
BA_ "GenSigCycleTime" SG_ 439 RrAxle2RtWhlBrakeApplPrsHiRng 100;
BA_ "GenSigCycleTimeActive" SG_ 439 RrAxle2RtWhlBrakeApplPrsHiRng 100;
BA_ "GenSigStartValue" SG_ 439 RrAxle2RtWhlBrakeApplPrsHiRng 255;
BA_ "GenSigMaxLatency" SG_ 439 RrAxle2RtWhlBrakeApplPrsHiRng 20;
BA_ "GenSigCycleTime" SG_ 439 ScndRrAxlDiffLckActvnFuncReq 100;
BA_ "GenSigCycleTimeActive" SG_ 439 ScndRrAxlDiffLckActvnFuncReq 100;
BA_ "GenSigStartValue" SG_ 439 ScndRrAxlDiffLckActvnFuncReq 3;
BA_ "GenSigMaxLatency" SG_ 439 ScndRrAxlDiffLckActvnFuncReq 20;
BA_ "GenSigCycleTime" SG_ 439 TCMSupply_TrailerPressure 100;
BA_ "GenSigCycleTimeActive" SG_ 439 TCMSupply_TrailerPressure 100;
BA_ "GenSigStartValue" SG_ 439 TCMSupply_TrailerPressure 255;
BA_ "GenSigMaxLatency" SG_ 439 TCMSupply_TrailerPressure 20;
BA_ "GenSigCycleTime" SG_ 439 CombinedWheelSpeed_Speed 100;
BA_ "GenSigCycleTimeActive" SG_ 439 CombinedWheelSpeed_Speed 100;
BA_ "GenSigStartValue" SG_ 439 CombinedWheelSpeed_Speed 65535;
BA_ "GenSigMaxLatency" SG_ 439 CombinedWheelSpeed_Speed 20;
BA_ "GenSigCycleTime" SG_ 439 HSAState 100;
BA_ "GenSigCycleTimeActive" SG_ 439 HSAState 100;
BA_ "GenSigStartValue" SG_ 439 HSAState 3;
BA_ "GenSigMaxLatency" SG_ 439 HSAState 20;
BA_ "GenSigCycleTime" SG_ 439 FrAxleLtWhlBrakeApplPrsHiRng 100;
BA_ "GenSigCycleTimeActive" SG_ 439 FrAxleLtWhlBrakeApplPrsHiRng 100;
BA_ "GenSigStartValue" SG_ 439 FrAxleLtWhlBrakeApplPrsHiRng 255;
BA_ "GenSigMaxLatency" SG_ 439 FrAxleLtWhlBrakeApplPrsHiRng 20;
BA_ "GenSigCycleTime" SG_ 315 FrontAxleLeftWheelSpeed 100;
BA_ "GenSigCycleTimeActive" SG_ 315 FrontAxleLeftWheelSpeed 100;
BA_ "GenSigStartValue" SG_ 315 FrontAxleLeftWheelSpeed 65535;
BA_ "GenSigMaxLatency" SG_ 315 FrontAxleLeftWheelSpeed 10;
BA_ "GenSigCycleTime" SG_ 315 SteeringWheel_AngleCRC 100;
BA_ "GenSigCycleTimeActive" SG_ 315 SteeringWheel_AngleCRC 100;
BA_ "GenSigMaxLatency" SG_ 315 SteeringWheel_AngleCRC 10;
BA_ "GenSigCycleTime" SG_ 315 SteeringWheel_AngleCounter 100;
BA_ "GenSigCycleTimeActive" SG_ 315 SteeringWheel_AngleCounter 100;
BA_ "GenSigMaxLatency" SG_ 315 SteeringWheel_AngleCounter 10;
BA_ "GenSigCycleTime" SG_ 315 FrontAxleRightWheelSpeed 100;
BA_ "GenSigCycleTimeActive" SG_ 315 FrontAxleRightWheelSpeed 100;
BA_ "GenSigStartValue" SG_ 315 FrontAxleRightWheelSpeed 65535;
BA_ "GenSigMaxLatency" SG_ 315 FrontAxleRightWheelSpeed 10;
BA_ "GenSigCycleTime" SG_ 315 SteeringWheel_AngleValue 100;
BA_ "GenSigCycleTimeActive" SG_ 315 SteeringWheel_AngleValue 100;
BA_ "GenSigStartValue" SG_ 315 SteeringWheel_AngleValue 65535;
BA_ "GenSigMaxLatency" SG_ 315 SteeringWheel_AngleValue 10;
BA_ "GenSigCycleTime" SG_ 315 SteeringWheelAngle 100;
BA_ "GenSigCycleTimeActive" SG_ 315 SteeringWheelAngle 100;
BA_ "GenSigStartValue" SG_ 315 SteeringWheelAngle 65535;
BA_ "GenSigMaxLatency" SG_ 315 SteeringWheelAngle 10;
BA_ "GenSigCycleTime" SG_ 315 SteeringWheelAngleComp 100;
BA_ "GenSigCycleTimeActive" SG_ 315 SteeringWheelAngleComp 100;
BA_ "GenSigStartValue" SG_ 315 SteeringWheelAngleComp 65535;
BA_ "GenSigMaxLatency" SG_ 315 SteeringWheelAngleComp 10;
BA_ "GenSigCycleTime" SG_ 315 YawRate 100;
BA_ "GenSigCycleTimeActive" SG_ 315 YawRate 100;
BA_ "GenSigStartValue" SG_ 315 YawRate 65535;
BA_ "GenSigMaxLatency" SG_ 315 YawRate 10;
BA_ "GenSigSendType" SG_ 2671964720 DiagUUDTRespSig_F2_30 7;
BA_ "GenSigSendType" SG_ 2671964707 DiagUUDTRespSig_F2_23 7;
BA_ "GenSigSendType" SG_ 2671834160 InternalTesterDiagSig_F4_30 7;
BA_ "GenSigSendType" SG_ 2671834147 InternalTesterDiagSig_F4_23 7;
BA_ "GenSigSendType" SG_ 2671784180 InternalTesterDiagSig_30_F4 7;
BA_ "GenSigSendType" SG_ 2671780852 InternalTesterDiagSig_23_F4 7;
BA_ "GenSigSendType" SG_ 1491 DiagFaultStat_FAS_sg_UB 7;
BA_ "GenSigSendType" SG_ 1491 DiagFaultStat_FAS_FailTA 3;
BA_ "NeedsUpdateBit" SG_ 1491 DiagFaultStat_FAS_FailTA 1;
BA_ "GenSigSendType" SG_ 1491 DiagFaultStat_FAS_EcuAdr 3;
BA_ "GenSigStartValue" SG_ 1491 DiagFaultStat_FAS_EcuAdr 255;
BA_ "NeedsUpdateBit" SG_ 1491 DiagFaultStat_FAS_EcuAdr 1;
BA_ "GenSigSendType" SG_ 1491 DiagFaultStat_FAS_DtcIdA 3;
BA_ "NeedsUpdateBit" SG_ 1491 DiagFaultStat_FAS_DtcIdA 1;
BA_ "GenSigSendType" SG_ 1491 DiagFaultStat_FAS_DtcIdB 3;
BA_ "NeedsUpdateBit" SG_ 1491 DiagFaultStat_FAS_DtcIdB 1;
BA_ "GenSigSendType" SG_ 1491 DiagFaultStat_FAS_FailTB 3;
BA_ "NeedsUpdateBit" SG_ 1491 DiagFaultStat_FAS_FailTB 1;
BA_ "GenSigSendType" SG_ 1954 Debug_9_FAS 1;
BA_ "GenSigSendType" SG_ 1949 Debug_8_FAS 1;
BA_ "GenSigSendType" SG_ 1944 Debug_7_FAS 1;
BA_ "GenSigSendType" SG_ 1938 Debug_6_FAS 1;
BA_ "GenSigSendType" SG_ 1930 Debug_5_FAS 1;
BA_ "GenSigSendType" SG_ 1922 Debug_4_FAS 1;
BA_ "GenSigSendType" SG_ 1914 Debug_3_FAS 1;
BA_ "GenSigSendType" SG_ 1906 Debug_2_FAS 1;
BA_ "GenSigSendType" SG_ 1898 Debug_1_FAS 1;
BA_ "GenSigSendType" SG_ 1959 Debug_16_FAS 1;
BA_ "GenSigSendType" SG_ 1891 Debug_15_FAS 1;
BA_ "GenSigSendType" SG_ 1890 Debug_14_FAS 1;
BA_ "GenSigSendType" SG_ 1889 Debug_13_FAS 1;
BA_ "GenSigSendType" SG_ 1888 Debug_12_FAS 1;
BA_ "GenSigSendType" SG_ 1887 Debug_11_FAS 1;
BA_ "GenSigSendType" SG_ 1886 Debug_10_FAS 1;
BA_ "GenSigSendType" SG_ 2041 DSPTesterRespSigFAS 1;
BA_ "GenSigCycleTimeActive" SG_ 2041 DSPTesterRespSigFAS 100;
BA_ "GenSigSendType" SG_ 2047 DSPTesterReqSigFAS 1;
BA_ "GenSigCycleTime" SG_ 2047 DSPTesterReqSigFAS 100;
BA_ "GenSigCycleTimeActive" SG_ 2047 DSPTesterReqSigFAS 100;
BA_ "GenSigSendType" SG_ 1703 AnmSig_VCM_CAN03 1;
BA_ "GenSigCycleTime" SG_ 1703 AnmSig_VCM_CAN03 100;
BA_ "GenSigCycleTimeActive" SG_ 1703 AnmSig_VCM_CAN03 100;
BA_ "MmAnSignal" SG_ 1703 AnmSig_VCM_CAN03 1;
BA_ "GenSigSendType" SG_ 1701 AnmSig_FAS_CAN03 1;
BA_ "GenSigCycleTime" SG_ 1701 AnmSig_FAS_CAN03 100;
BA_ "GenSigCycleTimeActive" SG_ 1701 AnmSig_FAS_CAN03 100;
BA_ "MmAnSignal" SG_ 1701 AnmSig_FAS_CAN03 1;
BA_ "GenSigSendType" SG_ 1704 AnmSig_EBS_CAN03 1;
BA_ "GenSigCycleTime" SG_ 1704 AnmSig_EBS_CAN03 100;
BA_ "GenSigCycleTimeActive" SG_ 1704 AnmSig_EBS_CAN03 100;
BA_ "MmAnSignal" SG_ 1704 AnmSig_EBS_CAN03 1;
BA_ "GenSigSendType" SG_ 1702 AnmSig_APM_CAN03 1;
BA_ "GenSigCycleTime" SG_ 1702 AnmSig_APM_CAN03 100;
BA_ "GenSigCycleTimeActive" SG_ 1702 AnmSig_APM_CAN03 100;
BA_ "MmAnSignal" SG_ 1702 AnmSig_APM_CAN03 1;
BA_REL_ "GenSigFirstTimeoutTime" BU_SG_REL_ VCM SG_ 594 CpbtyAxle5_BrkEgyCpctyLe 3000;
BA_REL_ "GenSigTimeoutTime" BU_SG_REL_ VCM SG_ 594 CpbtyAxle5_BrkEgyCpctyLe 300;
BA_REL_ "GenSigFirstTimeoutTime" BU_SG_REL_ VCM SG_ 594 CpbtyAxle4_TqCpbtyRateQltyLe 3000;
BA_REL_ "GenSigTimeoutTime" BU_SG_REL_ VCM SG_ 594 CpbtyAxle4_TqCpbtyRateQltyLe 300;
BA_REL_ "GenSigFirstTimeoutTime" BU_SG_REL_ VCM SG_ 594 CpbtyAxle4_TqCpbtyRateDecRi 3000;
BA_REL_ "GenSigTimeoutTime" BU_SG_REL_ VCM SG_ 594 CpbtyAxle4_TqCpbtyRateDecRi 300;
BA_REL_ "GenSigFirstTimeoutTime" BU_SG_REL_ VCM SG_ 594 CpbtyAxle4_BrkEgyCpctyQltyRi 3000;
BA_REL_ "GenSigTimeoutTime" BU_SG_REL_ VCM SG_ 594 CpbtyAxle4_BrkEgyCpctyQltyRi 300;
BA_REL_ "GenSigFirstTimeoutTime" BU_SG_REL_ VCM SG_ 594 CpbtyAxle4_TqCpbtyMinRi 3000;
BA_REL_ "GenSigTimeoutTime" BU_SG_REL_ VCM SG_ 594 CpbtyAxle4_TqCpbtyMinRi 300;
BA_REL_ "GenSigFirstTimeoutTime" BU_SG_REL_ VCM SG_ 594 CpbtyAxle5_TqCpbtyMaxLe 3000;
BA_REL_ "GenSigTimeoutTime" BU_SG_REL_ VCM SG_ 594 CpbtyAxle5_TqCpbtyMaxLe 300;
BA_REL_ "GenSigFirstTimeoutTime" BU_SG_REL_ VCM SG_ 594 CpbtyAxle5_TqCpbtyQltyLe 3000;
BA_REL_ "GenSigTimeoutTime" BU_SG_REL_ VCM SG_ 594 CpbtyAxle5_TqCpbtyQltyLe 300;
BA_REL_ "GenSigFirstTimeoutTime" BU_SG_REL_ VCM SG_ 594 CpbtyAxle5_PadWearRi 3000;
BA_REL_ "GenSigTimeoutTime" BU_SG_REL_ VCM SG_ 594 CpbtyAxle5_PadWearRi 300;
BA_REL_ "GenSigFirstTimeoutTime" BU_SG_REL_ VCM SG_ 594 CpbtyAxle5_TqCpbtyRateIncLeRi 3000;
BA_REL_ "GenSigTimeoutTime" BU_SG_REL_ VCM SG_ 594 CpbtyAxle5_TqCpbtyRateIncLeRi 300;
BA_REL_ "GenSigFirstTimeoutTime" BU_SG_REL_ VCM SG_ 594 CpbtyAxle6_TqCpbtyRateQltyLe 3000;
BA_REL_ "GenSigTimeoutTime" BU_SG_REL_ VCM SG_ 594 CpbtyAxle6_TqCpbtyRateQltyLe 300;
BA_REL_ "GenSigFirstTimeoutTime" BU_SG_REL_ VCM SG_ 594 CpbtyAxle5_TqCpbtyRateDecLe 3000;
BA_REL_ "GenSigTimeoutTime" BU_SG_REL_ VCM SG_ 594 CpbtyAxle5_TqCpbtyRateDecLe 300;
BA_REL_ "GenSigFirstTimeoutTime" BU_SG_REL_ VCM SG_ 594 CpbtyAxle6_TqCpbtyMinRi 3000;
BA_REL_ "GenSigTimeoutTime" BU_SG_REL_ VCM SG_ 594 CpbtyAxle6_TqCpbtyMinRi 300;
BA_REL_ "GenSigFirstTimeoutTime" BU_SG_REL_ VCM SG_ 594 CpbtyAxle6_BrkEgyCpctyRi 3000;
BA_REL_ "GenSigTimeoutTime" BU_SG_REL_ VCM SG_ 594 CpbtyAxle6_BrkEgyCpctyRi 300;
BA_REL_ "GenSigFirstTimeoutTime" BU_SG_REL_ VCM SG_ 594 CpbtyAxle6_TqCpbtyRateQltyRi 3000;
BA_REL_ "GenSigTimeoutTime" BU_SG_REL_ VCM SG_ 594 CpbtyAxle6_TqCpbtyRateQltyRi 300;
BA_REL_ "GenSigFirstTimeoutTime" BU_SG_REL_ VCM SG_ 594 CpbtyAxle6_TqCpbtyRateIncLeRi 3000;
BA_REL_ "GenSigTimeoutTime" BU_SG_REL_ VCM SG_ 594 CpbtyAxle6_TqCpbtyRateIncLeRi 300;
BA_REL_ "GenSigFirstTimeoutTime" BU_SG_REL_ VCM SG_ 594 CpbtyAxle5_TqCpbtyMaxRi 3000;
BA_REL_ "GenSigTimeoutTime" BU_SG_REL_ VCM SG_ 594 CpbtyAxle5_TqCpbtyMaxRi 300;
BA_REL_ "GenSigFirstTimeoutTime" BU_SG_REL_ VCM SG_ 594 CpbtyAxle5_CRC 3000;
BA_REL_ "GenSigTimeoutTime" BU_SG_REL_ VCM SG_ 594 CpbtyAxle5_CRC 300;
BA_REL_ "GenSigFirstTimeoutTime" BU_SG_REL_ VCM SG_ 594 CpbtyAxle6_TqCpbtyRateDecLe 3000;
BA_REL_ "GenSigTimeoutTime" BU_SG_REL_ VCM SG_ 594 CpbtyAxle6_TqCpbtyRateDecLe 300;
BA_REL_ "GenSigFirstTimeoutTime" BU_SG_REL_ VCM SG_ 594 CpbtyAxle5_SlipCtrlEna 3000;
BA_REL_ "GenSigTimeoutTime" BU_SG_REL_ VCM SG_ 594 CpbtyAxle5_SlipCtrlEna 300;
BA_REL_ "GenSigFirstTimeoutTime" BU_SG_REL_ VCM SG_ 594 CpbtyAxle5_PadWearQltyLe 3000;
BA_REL_ "GenSigTimeoutTime" BU_SG_REL_ VCM SG_ 594 CpbtyAxle5_PadWearQltyLe 300;
BA_REL_ "GenSigFirstTimeoutTime" BU_SG_REL_ VCM SG_ 594 CpbtyAxle6_BrkEgyCpctyQltyRi 3000;
BA_REL_ "GenSigTimeoutTime" BU_SG_REL_ VCM SG_ 594 CpbtyAxle6_BrkEgyCpctyQltyRi 300;
BA_REL_ "GenSigFirstTimeoutTime" BU_SG_REL_ VCM SG_ 594 CpbtyAxle5_BrkEgyCpctyQltyLe 3000;
BA_REL_ "GenSigTimeoutTime" BU_SG_REL_ VCM SG_ 594 CpbtyAxle5_BrkEgyCpctyQltyLe 300;
BA_REL_ "GenSigFirstTimeoutTime" BU_SG_REL_ VCM SG_ 594 CpbtyAxle6_PadWearQltyRi 3000;
BA_REL_ "GenSigTimeoutTime" BU_SG_REL_ VCM SG_ 594 CpbtyAxle6_PadWearQltyRi 300;
BA_REL_ "GenSigFirstTimeoutTime" BU_SG_REL_ VCM SG_ 594 CpbtyAxle6_TqCpbtyMaxRi 3000;
BA_REL_ "GenSigTimeoutTime" BU_SG_REL_ VCM SG_ 594 CpbtyAxle6_TqCpbtyMaxRi 300;
BA_REL_ "GenSigFirstTimeoutTime" BU_SG_REL_ VCM SG_ 594 CpbtyAxle4_TqCpbtyQltyLe 3000;
BA_REL_ "GenSigTimeoutTime" BU_SG_REL_ VCM SG_ 594 CpbtyAxle4_TqCpbtyQltyLe 300;
BA_REL_ "GenSigFirstTimeoutTime" BU_SG_REL_ VCM SG_ 594 CpbtyAxle4_SlipCtrlEna 3000;
BA_REL_ "GenSigTimeoutTime" BU_SG_REL_ VCM SG_ 594 CpbtyAxle4_SlipCtrlEna 300;
BA_REL_ "GenSigFirstTimeoutTime" BU_SG_REL_ VCM SG_ 594 CpbtyAxle4_BrkEgyCpctyRi 3000;
BA_REL_ "GenSigTimeoutTime" BU_SG_REL_ VCM SG_ 594 CpbtyAxle4_BrkEgyCpctyRi 300;
BA_REL_ "GenSigFirstTimeoutTime" BU_SG_REL_ VCM SG_ 594 CpbtyAxle6_TqCpbtyQltyRi 3000;
BA_REL_ "GenSigTimeoutTime" BU_SG_REL_ VCM SG_ 594 CpbtyAxle6_TqCpbtyQltyRi 300;
BA_REL_ "GenSigFirstTimeoutTime" BU_SG_REL_ VCM SG_ 594 CpbtyAxle6_CRC 3000;
BA_REL_ "GenSigTimeoutTime" BU_SG_REL_ VCM SG_ 594 CpbtyAxle6_CRC 300;
BA_REL_ "GenSigFirstTimeoutTime" BU_SG_REL_ VCM SG_ 594 CpbtyAxle5_TqCpbtyRateQltyLe 3000;
BA_REL_ "GenSigTimeoutTime" BU_SG_REL_ VCM SG_ 594 CpbtyAxle5_TqCpbtyRateQltyLe 300;
BA_REL_ "GenSigFirstTimeoutTime" BU_SG_REL_ VCM SG_ 594 CpbtyAxle4_TqCpbtyMaxLe 3000;
BA_REL_ "GenSigTimeoutTime" BU_SG_REL_ VCM SG_ 594 CpbtyAxle4_TqCpbtyMaxLe 300;
BA_REL_ "GenSigFirstTimeoutTime" BU_SG_REL_ VCM SG_ 594 CpbtyAxle4_PadWearRi 3000;
BA_REL_ "GenSigTimeoutTime" BU_SG_REL_ VCM SG_ 594 CpbtyAxle4_PadWearRi 300;
BA_REL_ "GenSigFirstTimeoutTime" BU_SG_REL_ VCM SG_ 594 CpbtyAxle6_TqCpbtyMinLe 3000;
BA_REL_ "GenSigTimeoutTime" BU_SG_REL_ VCM SG_ 594 CpbtyAxle6_TqCpbtyMinLe 300;
BA_REL_ "GenSigFirstTimeoutTime" BU_SG_REL_ VCM SG_ 594 CpbtyAxle4_CRC 3000;
BA_REL_ "GenSigTimeoutTime" BU_SG_REL_ VCM SG_ 594 CpbtyAxle4_CRC 300;
BA_REL_ "GenSigFirstTimeoutTime" BU_SG_REL_ VCM SG_ 594 CpbtyAxle4_SqC 3000;
BA_REL_ "GenSigTimeoutTime" BU_SG_REL_ VCM SG_ 594 CpbtyAxle4_SqC 300;
BA_REL_ "GenSigFirstTimeoutTime" BU_SG_REL_ VCM SG_ 594 CpbtyAxle5_TqCpbtyMinLe 3000;
BA_REL_ "GenSigTimeoutTime" BU_SG_REL_ VCM SG_ 594 CpbtyAxle5_TqCpbtyMinLe 300;
BA_REL_ "GenSigFirstTimeoutTime" BU_SG_REL_ VCM SG_ 594 CpbtyAxle6_PadWearQltyLe 3000;
BA_REL_ "GenSigTimeoutTime" BU_SG_REL_ VCM SG_ 594 CpbtyAxle6_PadWearQltyLe 300;
BA_REL_ "GenSigFirstTimeoutTime" BU_SG_REL_ VCM SG_ 594 CpbtyAxle6_PadWearRi 3000;
BA_REL_ "GenSigTimeoutTime" BU_SG_REL_ VCM SG_ 594 CpbtyAxle6_PadWearRi 300;
BA_REL_ "GenSigFirstTimeoutTime" BU_SG_REL_ VCM SG_ 594 CpbtyAxle5_TqCpbtyRateQltyRi 3000;
BA_REL_ "GenSigTimeoutTime" BU_SG_REL_ VCM SG_ 594 CpbtyAxle5_TqCpbtyRateQltyRi 300;
BA_REL_ "GenSigFirstTimeoutTime" BU_SG_REL_ VCM SG_ 594 CpbtyAxle4_TqCpbtyQltyRi 3000;
BA_REL_ "GenSigTimeoutTime" BU_SG_REL_ VCM SG_ 594 CpbtyAxle4_TqCpbtyQltyRi 300;
BA_REL_ "GenSigFirstTimeoutTime" BU_SG_REL_ VCM SG_ 594 CpbtyAxle6_SlipCtrlEna 3000;
BA_REL_ "GenSigTimeoutTime" BU_SG_REL_ VCM SG_ 594 CpbtyAxle6_SlipCtrlEna 300;
BA_REL_ "GenSigFirstTimeoutTime" BU_SG_REL_ VCM SG_ 594 CpbtyAxle5_TqCpbtyQltyRi 3000;
BA_REL_ "GenSigTimeoutTime" BU_SG_REL_ VCM SG_ 594 CpbtyAxle5_TqCpbtyQltyRi 300;
BA_REL_ "GenSigFirstTimeoutTime" BU_SG_REL_ VCM SG_ 594 CpbtyAxle4_BrkEgyCpctyQltyLe 3000;
BA_REL_ "GenSigTimeoutTime" BU_SG_REL_ VCM SG_ 594 CpbtyAxle4_BrkEgyCpctyQltyLe 300;
BA_REL_ "GenSigFirstTimeoutTime" BU_SG_REL_ VCM SG_ 594 CpbtyAxle4_TqCpbtyMinLe 3000;
BA_REL_ "GenSigTimeoutTime" BU_SG_REL_ VCM SG_ 594 CpbtyAxle4_TqCpbtyMinLe 300;
BA_REL_ "GenSigFirstTimeoutTime" BU_SG_REL_ VCM SG_ 594 CpbtyAxle5_TqCpbtyMinRi 3000;
BA_REL_ "GenSigTimeoutTime" BU_SG_REL_ VCM SG_ 594 CpbtyAxle5_TqCpbtyMinRi 300;
BA_REL_ "GenSigFirstTimeoutTime" BU_SG_REL_ VCM SG_ 594 CpbtyAxle6_SqC 3000;
BA_REL_ "GenSigTimeoutTime" BU_SG_REL_ VCM SG_ 594 CpbtyAxle6_SqC 300;
BA_REL_ "GenSigFirstTimeoutTime" BU_SG_REL_ VCM SG_ 594 CpbtyAxle6_TqCpbtyRateDecRi 3000;
BA_REL_ "GenSigTimeoutTime" BU_SG_REL_ VCM SG_ 594 CpbtyAxle6_TqCpbtyRateDecRi 300;
BA_REL_ "GenSigFirstTimeoutTime" BU_SG_REL_ VCM SG_ 594 CpbtyAxle6_TqCpbtyRateIncLeLe 3000;
BA_REL_ "GenSigTimeoutTime" BU_SG_REL_ VCM SG_ 594 CpbtyAxle6_TqCpbtyRateIncLeLe 300;
BA_REL_ "GenSigFirstTimeoutTime" BU_SG_REL_ VCM SG_ 594 CpbtyAxle4_TqCpbtyRateDecLe 3000;
BA_REL_ "GenSigTimeoutTime" BU_SG_REL_ VCM SG_ 594 CpbtyAxle4_TqCpbtyRateDecLe 300;
BA_REL_ "GenSigFirstTimeoutTime" BU_SG_REL_ VCM SG_ 594 CpbtyAxle4_TqCpbtyRateQltyRi 3000;
BA_REL_ "GenSigTimeoutTime" BU_SG_REL_ VCM SG_ 594 CpbtyAxle4_TqCpbtyRateQltyRi 300;
BA_REL_ "GenSigFirstTimeoutTime" BU_SG_REL_ VCM SG_ 594 CpbtyAxle4_BrkEgyCpctyLe 3000;
BA_REL_ "GenSigTimeoutTime" BU_SG_REL_ VCM SG_ 594 CpbtyAxle4_BrkEgyCpctyLe 300;
BA_REL_ "GenSigFirstTimeoutTime" BU_SG_REL_ VCM SG_ 594 CpbtyAxle4_TqCpbtyMaxRi 3000;
BA_REL_ "GenSigTimeoutTime" BU_SG_REL_ VCM SG_ 594 CpbtyAxle4_TqCpbtyMaxRi 300;
BA_REL_ "GenSigFirstTimeoutTime" BU_SG_REL_ VCM SG_ 594 CpbtyAxle6_TqCpbtyMaxLe 3000;
BA_REL_ "GenSigTimeoutTime" BU_SG_REL_ VCM SG_ 594 CpbtyAxle6_TqCpbtyMaxLe 300;
BA_REL_ "GenSigFirstTimeoutTime" BU_SG_REL_ VCM SG_ 594 CpbtyAxle5_TqCpbtyRateIncLeLe 3000;
BA_REL_ "GenSigTimeoutTime" BU_SG_REL_ VCM SG_ 594 CpbtyAxle5_TqCpbtyRateIncLeLe 300;
BA_REL_ "GenSigFirstTimeoutTime" BU_SG_REL_ VCM SG_ 594 CpbtyAxle5_PadWearQltyRi 3000;
BA_REL_ "GenSigTimeoutTime" BU_SG_REL_ VCM SG_ 594 CpbtyAxle5_PadWearQltyRi 300;
BA_REL_ "GenSigFirstTimeoutTime" BU_SG_REL_ VCM SG_ 594 CpbtyAxle6_BrkEgyCpctyQltyLe 3000;
BA_REL_ "GenSigTimeoutTime" BU_SG_REL_ VCM SG_ 594 CpbtyAxle6_BrkEgyCpctyQltyLe 300;
BA_REL_ "GenSigFirstTimeoutTime" BU_SG_REL_ VCM SG_ 594 CpbtyAxle5_TqCpbtyRateDecRi 3000;
BA_REL_ "GenSigTimeoutTime" BU_SG_REL_ VCM SG_ 594 CpbtyAxle5_TqCpbtyRateDecRi 300;
BA_REL_ "GenSigFirstTimeoutTime" BU_SG_REL_ VCM SG_ 594 CpbtyAxle6_TqCpbtyQltyLe 3000;
BA_REL_ "GenSigTimeoutTime" BU_SG_REL_ VCM SG_ 594 CpbtyAxle6_TqCpbtyQltyLe 300;
BA_REL_ "GenSigFirstTimeoutTime" BU_SG_REL_ VCM SG_ 594 CpbtyAxle5_SqC 3000;
BA_REL_ "GenSigTimeoutTime" BU_SG_REL_ VCM SG_ 594 CpbtyAxle5_SqC 300;
BA_REL_ "GenSigFirstTimeoutTime" BU_SG_REL_ VCM SG_ 594 CpbtyAxle4_TqCpbtyRateIncLeRi 3000;
BA_REL_ "GenSigTimeoutTime" BU_SG_REL_ VCM SG_ 594 CpbtyAxle4_TqCpbtyRateIncLeRi 300;
BA_REL_ "GenSigFirstTimeoutTime" BU_SG_REL_ VCM SG_ 594 CpbtyAxle6_BrkEgyCpctyLe 3000;
BA_REL_ "GenSigTimeoutTime" BU_SG_REL_ VCM SG_ 594 CpbtyAxle6_BrkEgyCpctyLe 300;
BA_REL_ "GenSigFirstTimeoutTime" BU_SG_REL_ VCM SG_ 594 CpbtyAxle5_BrkEgyCpctyRi 3000;
BA_REL_ "GenSigTimeoutTime" BU_SG_REL_ VCM SG_ 594 CpbtyAxle5_BrkEgyCpctyRi 300;
BA_REL_ "GenSigFirstTimeoutTime" BU_SG_REL_ VCM SG_ 594 CpbtyAxle5_BrkEgyCpctyQltyRi 3000;
BA_REL_ "GenSigTimeoutTime" BU_SG_REL_ VCM SG_ 594 CpbtyAxle5_BrkEgyCpctyQltyRi 300;
BA_REL_ "GenSigFirstTimeoutTime" BU_SG_REL_ VCM SG_ 594 CpbtyAxle6_PadWearLe 3000;
BA_REL_ "GenSigTimeoutTime" BU_SG_REL_ VCM SG_ 594 CpbtyAxle6_PadWearLe 300;
BA_REL_ "GenSigFirstTimeoutTime" BU_SG_REL_ VCM SG_ 594 CpbtyAxle4_PadWearLe 3000;
BA_REL_ "GenSigTimeoutTime" BU_SG_REL_ VCM SG_ 594 CpbtyAxle4_PadWearLe 300;
BA_REL_ "GenSigFirstTimeoutTime" BU_SG_REL_ VCM SG_ 594 CpbtyAxle4_PadWearQltyRi 3000;
BA_REL_ "GenSigTimeoutTime" BU_SG_REL_ VCM SG_ 594 CpbtyAxle4_PadWearQltyRi 300;
BA_REL_ "GenSigFirstTimeoutTime" BU_SG_REL_ VCM SG_ 594 CpbtyAxle4_TqCpbtyRateIncLeLe 3000;
BA_REL_ "GenSigTimeoutTime" BU_SG_REL_ VCM SG_ 594 CpbtyAxle4_TqCpbtyRateIncLeLe 300;
BA_REL_ "GenSigFirstTimeoutTime" BU_SG_REL_ VCM SG_ 594 CpbtyAxle5_PadWearLe 3000;
BA_REL_ "GenSigTimeoutTime" BU_SG_REL_ VCM SG_ 594 CpbtyAxle5_PadWearLe 300;
BA_REL_ "GenSigFirstTimeoutTime" BU_SG_REL_ VCM SG_ 594 CpbtyAxle4_PadWearQltyLe 3000;
BA_REL_ "GenSigTimeoutTime" BU_SG_REL_ VCM SG_ 594 CpbtyAxle4_PadWearQltyLe 300;
BA_REL_ "GenSigFirstTimeoutTime" BU_SG_REL_ VCM SG_ 592 CpbtyAxle3_BrkEgyCpctyQltyLe 3000;
BA_REL_ "GenSigTimeoutTime" BU_SG_REL_ VCM SG_ 592 CpbtyAxle3_BrkEgyCpctyQltyLe 300;
BA_REL_ "GenSigFirstTimeoutTime" BU_SG_REL_ VCM SG_ 592 CpbtyAxle3_TqCpbtyRateIncLeLe 3000;
BA_REL_ "GenSigTimeoutTime" BU_SG_REL_ VCM SG_ 592 CpbtyAxle3_TqCpbtyRateIncLeLe 300;
BA_REL_ "GenSigFirstTimeoutTime" BU_SG_REL_ VCM SG_ 592 CpbtyAxle3_TqCpbtyRateQltyRi 3000;
BA_REL_ "GenSigTimeoutTime" BU_SG_REL_ VCM SG_ 592 CpbtyAxle3_TqCpbtyRateQltyRi 300;
BA_REL_ "GenSigFirstTimeoutTime" BU_SG_REL_ VCM SG_ 592 CpbtyAxle1_PadWearQltyLe 3000;
BA_REL_ "GenSigTimeoutTime" BU_SG_REL_ VCM SG_ 592 CpbtyAxle1_PadWearQltyLe 300;
BA_REL_ "GenSigFirstTimeoutTime" BU_SG_REL_ VCM SG_ 592 CpbtyAxle1_SlipCtrlEna 3000;
BA_REL_ "GenSigTimeoutTime" BU_SG_REL_ VCM SG_ 592 CpbtyAxle1_SlipCtrlEna 300;
BA_REL_ "GenSigFirstTimeoutTime" BU_SG_REL_ VCM SG_ 592 CpbtyAxle2_PadWearRi 3000;
BA_REL_ "GenSigTimeoutTime" BU_SG_REL_ VCM SG_ 592 CpbtyAxle2_PadWearRi 300;
BA_REL_ "GenSigFirstTimeoutTime" BU_SG_REL_ VCM SG_ 592 CpbtyAxle3_TqCpbtyRateQltyLe 3000;
BA_REL_ "GenSigTimeoutTime" BU_SG_REL_ VCM SG_ 592 CpbtyAxle3_TqCpbtyRateQltyLe 300;
BA_REL_ "GenSigFirstTimeoutTime" BU_SG_REL_ VCM SG_ 592 CpbtyAxle1_BrkEgyCpctyQltyRi 3000;
BA_REL_ "GenSigTimeoutTime" BU_SG_REL_ VCM SG_ 592 CpbtyAxle1_BrkEgyCpctyQltyRi 300;
BA_REL_ "GenSigFirstTimeoutTime" BU_SG_REL_ VCM SG_ 592 CpbtyAxle2_TqCpbtyMaxRi 3000;
BA_REL_ "GenSigTimeoutTime" BU_SG_REL_ VCM SG_ 592 CpbtyAxle2_TqCpbtyMaxRi 300;
BA_REL_ "GenSigFirstTimeoutTime" BU_SG_REL_ VCM SG_ 592 CpbtyAxle2_TqCpbtyMinLe 3000;
BA_REL_ "GenSigTimeoutTime" BU_SG_REL_ VCM SG_ 592 CpbtyAxle2_TqCpbtyMinLe 300;
BA_REL_ "GenSigFirstTimeoutTime" BU_SG_REL_ VCM SG_ 592 CpbtyAxle2_BrkEgyCpctyQltyLe 3000;
BA_REL_ "GenSigTimeoutTime" BU_SG_REL_ VCM SG_ 592 CpbtyAxle2_BrkEgyCpctyQltyLe 300;
BA_REL_ "GenSigFirstTimeoutTime" BU_SG_REL_ VCM SG_ 592 CpbtyAxle2_TqCpbtyRateDecLe 3000;
BA_REL_ "GenSigTimeoutTime" BU_SG_REL_ VCM SG_ 592 CpbtyAxle2_TqCpbtyRateDecLe 300;
BA_REL_ "GenSigFirstTimeoutTime" BU_SG_REL_ VCM SG_ 592 CpbtyAxle3_SlipCtrlEna 3000;
BA_REL_ "GenSigTimeoutTime" BU_SG_REL_ VCM SG_ 592 CpbtyAxle3_SlipCtrlEna 300;
BA_REL_ "GenSigFirstTimeoutTime" BU_SG_REL_ VCM SG_ 592 CpbtyAxle3_TqCpbtyQltyLe 3000;
BA_REL_ "GenSigTimeoutTime" BU_SG_REL_ VCM SG_ 592 CpbtyAxle3_TqCpbtyQltyLe 300;
BA_REL_ "GenSigFirstTimeoutTime" BU_SG_REL_ VCM SG_ 592 CpbtyAxle3_BrkEgyCpctyRi 3000;
BA_REL_ "GenSigTimeoutTime" BU_SG_REL_ VCM SG_ 592 CpbtyAxle3_BrkEgyCpctyRi 300;
BA_REL_ "GenSigFirstTimeoutTime" BU_SG_REL_ VCM SG_ 592 CpbtyAxle1_SqC 3000;
BA_REL_ "GenSigTimeoutTime" BU_SG_REL_ VCM SG_ 592 CpbtyAxle1_SqC 300;
BA_REL_ "GenSigFirstTimeoutTime" BU_SG_REL_ VCM SG_ 592 CpbtyAxle1_TqCpbtyQltyLe 3000;
BA_REL_ "GenSigTimeoutTime" BU_SG_REL_ VCM SG_ 592 CpbtyAxle1_TqCpbtyQltyLe 300;
BA_REL_ "GenSigFirstTimeoutTime" BU_SG_REL_ VCM SG_ 592 CpbtyAxle2_TqCpbtyRateDecRi 3000;
BA_REL_ "GenSigTimeoutTime" BU_SG_REL_ VCM SG_ 592 CpbtyAxle2_TqCpbtyRateDecRi 300;
BA_REL_ "GenSigFirstTimeoutTime" BU_SG_REL_ VCM SG_ 592 CpbtyAxle1_TqCpbtyRateIncLeLe 3000;
BA_REL_ "GenSigTimeoutTime" BU_SG_REL_ VCM SG_ 592 CpbtyAxle1_TqCpbtyRateIncLeLe 300;
BA_REL_ "GenSigFirstTimeoutTime" BU_SG_REL_ VCM SG_ 592 CpbtyAxle3_BrkEgyCpctyQltyRi 3000;
BA_REL_ "GenSigTimeoutTime" BU_SG_REL_ VCM SG_ 592 CpbtyAxle3_BrkEgyCpctyQltyRi 300;
BA_REL_ "GenSigFirstTimeoutTime" BU_SG_REL_ VCM SG_ 592 CpbtyAxle3_TqCpbtyRateDecLe 3000;
BA_REL_ "GenSigTimeoutTime" BU_SG_REL_ VCM SG_ 592 CpbtyAxle3_TqCpbtyRateDecLe 300;
BA_REL_ "GenSigFirstTimeoutTime" BU_SG_REL_ VCM SG_ 592 CpbtyAxle3_TqCpbtyRateDecRi 3000;
BA_REL_ "GenSigTimeoutTime" BU_SG_REL_ VCM SG_ 592 CpbtyAxle3_TqCpbtyRateDecRi 300;
BA_REL_ "GenSigFirstTimeoutTime" BU_SG_REL_ VCM SG_ 592 CpbtyAxle1_PadWearRi 3000;
BA_REL_ "GenSigTimeoutTime" BU_SG_REL_ VCM SG_ 592 CpbtyAxle1_PadWearRi 300;
BA_REL_ "GenSigFirstTimeoutTime" BU_SG_REL_ VCM SG_ 592 CpbtyAxle2_TqCpbtyMaxLe 3000;
BA_REL_ "GenSigTimeoutTime" BU_SG_REL_ VCM SG_ 592 CpbtyAxle2_TqCpbtyMaxLe 300;
BA_REL_ "GenSigFirstTimeoutTime" BU_SG_REL_ VCM SG_ 592 CpbtyAxle3_TqCpbtyQltyRi 3000;
BA_REL_ "GenSigTimeoutTime" BU_SG_REL_ VCM SG_ 592 CpbtyAxle3_TqCpbtyQltyRi 300;
BA_REL_ "GenSigFirstTimeoutTime" BU_SG_REL_ VCM SG_ 592 CpbtyAxle1_TqCpbtyRateDecLe 3000;
BA_REL_ "GenSigTimeoutTime" BU_SG_REL_ VCM SG_ 592 CpbtyAxle1_TqCpbtyRateDecLe 300;
BA_REL_ "GenSigFirstTimeoutTime" BU_SG_REL_ VCM SG_ 592 CpbtyAxle1_BrkEgyCpctyRi 3000;
BA_REL_ "GenSigTimeoutTime" BU_SG_REL_ VCM SG_ 592 CpbtyAxle1_BrkEgyCpctyRi 300;
BA_REL_ "GenSigFirstTimeoutTime" BU_SG_REL_ VCM SG_ 592 CpbtyAxle3_TqCpbtyMinLe 3000;
BA_REL_ "GenSigTimeoutTime" BU_SG_REL_ VCM SG_ 592 CpbtyAxle3_TqCpbtyMinLe 300;
BA_REL_ "GenSigFirstTimeoutTime" BU_SG_REL_ VCM SG_ 592 CpbtyAxle3_TqCpbtyMinRi 3000;
BA_REL_ "GenSigTimeoutTime" BU_SG_REL_ VCM SG_ 592 CpbtyAxle3_TqCpbtyMinRi 300;
BA_REL_ "GenSigFirstTimeoutTime" BU_SG_REL_ VCM SG_ 592 CpbtyAxle2_BrkEgyCpctyQltyRi 3000;
BA_REL_ "GenSigTimeoutTime" BU_SG_REL_ VCM SG_ 592 CpbtyAxle2_BrkEgyCpctyQltyRi 300;
BA_REL_ "GenSigFirstTimeoutTime" BU_SG_REL_ VCM SG_ 592 CpbtyAxle2_PadWearLe 3000;
BA_REL_ "GenSigTimeoutTime" BU_SG_REL_ VCM SG_ 592 CpbtyAxle2_PadWearLe 300;
BA_REL_ "GenSigFirstTimeoutTime" BU_SG_REL_ VCM SG_ 592 CpbtyAxle2_TqCpbtyQltyRi 3000;
BA_REL_ "GenSigTimeoutTime" BU_SG_REL_ VCM SG_ 592 CpbtyAxle2_TqCpbtyQltyRi 300;
BA_REL_ "GenSigFirstTimeoutTime" BU_SG_REL_ VCM SG_ 592 CpbtyAxle2_PadWearQltyRi 3000;
BA_REL_ "GenSigTimeoutTime" BU_SG_REL_ VCM SG_ 592 CpbtyAxle2_PadWearQltyRi 300;
BA_REL_ "GenSigFirstTimeoutTime" BU_SG_REL_ VCM SG_ 592 CpbtyAxle3_PadWearRi 3000;
BA_REL_ "GenSigTimeoutTime" BU_SG_REL_ VCM SG_ 592 CpbtyAxle3_PadWearRi 300;
BA_REL_ "GenSigFirstTimeoutTime" BU_SG_REL_ VCM SG_ 592 CpbtyAxle3_PadWearQltyRi 3000;
BA_REL_ "GenSigTimeoutTime" BU_SG_REL_ VCM SG_ 592 CpbtyAxle3_PadWearQltyRi 300;
BA_REL_ "GenSigFirstTimeoutTime" BU_SG_REL_ VCM SG_ 592 CpbtyAxle1_TqCpbtyMaxRi 3000;
BA_REL_ "GenSigTimeoutTime" BU_SG_REL_ VCM SG_ 592 CpbtyAxle1_TqCpbtyMaxRi 300;
BA_REL_ "GenSigFirstTimeoutTime" BU_SG_REL_ VCM SG_ 592 CpbtyAxle2_TqCpbtyRateQltyRi 3000;
BA_REL_ "GenSigTimeoutTime" BU_SG_REL_ VCM SG_ 592 CpbtyAxle2_TqCpbtyRateQltyRi 300;
BA_REL_ "GenSigFirstTimeoutTime" BU_SG_REL_ VCM SG_ 592 CpbtyAxle1_BrkEgyCpctyLe 3000;
BA_REL_ "GenSigTimeoutTime" BU_SG_REL_ VCM SG_ 592 CpbtyAxle1_BrkEgyCpctyLe 300;
BA_REL_ "GenSigFirstTimeoutTime" BU_SG_REL_ VCM SG_ 592 CpbtyAxle2_SlipCtrlEna 3000;
BA_REL_ "GenSigTimeoutTime" BU_SG_REL_ VCM SG_ 592 CpbtyAxle2_SlipCtrlEna 300;
BA_REL_ "GenSigFirstTimeoutTime" BU_SG_REL_ VCM SG_ 592 CpbtyAxle1_TqCpbtyRateIncLeRi 3000;
BA_REL_ "GenSigTimeoutTime" BU_SG_REL_ VCM SG_ 592 CpbtyAxle1_TqCpbtyRateIncLeRi 300;
BA_REL_ "GenSigFirstTimeoutTime" BU_SG_REL_ VCM SG_ 592 CpbtyAxle2_TqCpbtyMinRi 3000;
BA_REL_ "GenSigTimeoutTime" BU_SG_REL_ VCM SG_ 592 CpbtyAxle2_TqCpbtyMinRi 300;
BA_REL_ "GenSigFirstTimeoutTime" BU_SG_REL_ VCM SG_ 592 CpbtyAxle3_TqCpbtyMaxLe 3000;
BA_REL_ "GenSigTimeoutTime" BU_SG_REL_ VCM SG_ 592 CpbtyAxle3_TqCpbtyMaxLe 300;
BA_REL_ "GenSigFirstTimeoutTime" BU_SG_REL_ VCM SG_ 592 CpbtyAxle1_TqCpbtyRateQltyRi 3000;
BA_REL_ "GenSigTimeoutTime" BU_SG_REL_ VCM SG_ 592 CpbtyAxle1_TqCpbtyRateQltyRi 300;
BA_REL_ "GenSigFirstTimeoutTime" BU_SG_REL_ VCM SG_ 592 CpbtyAxle1_CRC 3000;
BA_REL_ "GenSigTimeoutTime" BU_SG_REL_ VCM SG_ 592 CpbtyAxle1_CRC 300;
BA_REL_ "GenSigFirstTimeoutTime" BU_SG_REL_ VCM SG_ 592 CpbtyAxle1_PadWearQltyRi 3000;
BA_REL_ "GenSigTimeoutTime" BU_SG_REL_ VCM SG_ 592 CpbtyAxle1_PadWearQltyRi 300;
BA_REL_ "GenSigFirstTimeoutTime" BU_SG_REL_ VCM SG_ 592 CpbtyAxle2_CRC 3000;
BA_REL_ "GenSigTimeoutTime" BU_SG_REL_ VCM SG_ 592 CpbtyAxle2_CRC 300;
BA_REL_ "GenSigFirstTimeoutTime" BU_SG_REL_ VCM SG_ 592 CpbtyAxle2_SqC 3000;
BA_REL_ "GenSigTimeoutTime" BU_SG_REL_ VCM SG_ 592 CpbtyAxle2_SqC 300;
BA_REL_ "GenSigFirstTimeoutTime" BU_SG_REL_ VCM SG_ 592 CpbtyAxle2_TqCpbtyRateIncLeLe 3000;
BA_REL_ "GenSigTimeoutTime" BU_SG_REL_ VCM SG_ 592 CpbtyAxle2_TqCpbtyRateIncLeLe 300;
BA_REL_ "GenSigFirstTimeoutTime" BU_SG_REL_ VCM SG_ 592 CpbtyAxle2_TqCpbtyRateIncLeRi 3000;
BA_REL_ "GenSigTimeoutTime" BU_SG_REL_ VCM SG_ 592 CpbtyAxle2_TqCpbtyRateIncLeRi 300;
BA_REL_ "GenSigFirstTimeoutTime" BU_SG_REL_ VCM SG_ 592 CpbtyAxle2_BrkEgyCpctyLe 3000;
BA_REL_ "GenSigTimeoutTime" BU_SG_REL_ VCM SG_ 592 CpbtyAxle2_BrkEgyCpctyLe 300;
BA_REL_ "GenSigFirstTimeoutTime" BU_SG_REL_ VCM SG_ 592 CpbtyAxle1_TqCpbtyRateDecRi 3000;
BA_REL_ "GenSigTimeoutTime" BU_SG_REL_ VCM SG_ 592 CpbtyAxle1_TqCpbtyRateDecRi 300;
BA_REL_ "GenSigFirstTimeoutTime" BU_SG_REL_ VCM SG_ 592 CpbtyAxle3_TqCpbtyMaxRi 3000;
BA_REL_ "GenSigTimeoutTime" BU_SG_REL_ VCM SG_ 592 CpbtyAxle3_TqCpbtyMaxRi 300;
BA_REL_ "GenSigFirstTimeoutTime" BU_SG_REL_ VCM SG_ 592 CpbtyAxle3_PadWearQltyLe 3000;
BA_REL_ "GenSigTimeoutTime" BU_SG_REL_ VCM SG_ 592 CpbtyAxle3_PadWearQltyLe 300;
BA_REL_ "GenSigFirstTimeoutTime" BU_SG_REL_ VCM SG_ 592 CpbtyAxle3_PadWearLe 3000;
BA_REL_ "GenSigTimeoutTime" BU_SG_REL_ VCM SG_ 592 CpbtyAxle3_PadWearLe 300;
BA_REL_ "GenSigFirstTimeoutTime" BU_SG_REL_ VCM SG_ 592 CpbtyAxle1_TqCpbtyRateQltyLe 3000;
BA_REL_ "GenSigTimeoutTime" BU_SG_REL_ VCM SG_ 592 CpbtyAxle1_TqCpbtyRateQltyLe 300;
BA_REL_ "GenSigFirstTimeoutTime" BU_SG_REL_ VCM SG_ 592 CpbtyAxle1_PadWearLe 3000;
BA_REL_ "GenSigTimeoutTime" BU_SG_REL_ VCM SG_ 592 CpbtyAxle1_PadWearLe 300;
BA_REL_ "GenSigFirstTimeoutTime" BU_SG_REL_ VCM SG_ 592 CpbtyAxle1_TqCpbtyMinRi 3000;
BA_REL_ "GenSigTimeoutTime" BU_SG_REL_ VCM SG_ 592 CpbtyAxle1_TqCpbtyMinRi 300;
BA_REL_ "GenSigFirstTimeoutTime" BU_SG_REL_ VCM SG_ 592 CpbtyAxle1_TqCpbtyQltyRi 3000;
BA_REL_ "GenSigTimeoutTime" BU_SG_REL_ VCM SG_ 592 CpbtyAxle1_TqCpbtyQltyRi 300;
BA_REL_ "GenSigFirstTimeoutTime" BU_SG_REL_ VCM SG_ 592 CpbtyAxle3_BrkEgyCpctyLe 3000;
BA_REL_ "GenSigTimeoutTime" BU_SG_REL_ VCM SG_ 592 CpbtyAxle3_BrkEgyCpctyLe 300;
BA_REL_ "GenSigFirstTimeoutTime" BU_SG_REL_ VCM SG_ 592 CpbtyAxle3_TqCpbtyRateIncLeRi 3000;
BA_REL_ "GenSigTimeoutTime" BU_SG_REL_ VCM SG_ 592 CpbtyAxle3_TqCpbtyRateIncLeRi 300;
BA_REL_ "GenSigFirstTimeoutTime" BU_SG_REL_ VCM SG_ 592 CpbtyAxle1_TqCpbtyMinLe 3000;
BA_REL_ "GenSigTimeoutTime" BU_SG_REL_ VCM SG_ 592 CpbtyAxle1_TqCpbtyMinLe 300;
BA_REL_ "GenSigFirstTimeoutTime" BU_SG_REL_ VCM SG_ 592 CpbtyAxle2_TqCpbtyQltyLe 3000;
BA_REL_ "GenSigTimeoutTime" BU_SG_REL_ VCM SG_ 592 CpbtyAxle2_TqCpbtyQltyLe 300;
BA_REL_ "GenSigFirstTimeoutTime" BU_SG_REL_ VCM SG_ 592 CpbtyAxle2_TqCpbtyRateQltyLe 3000;
BA_REL_ "GenSigTimeoutTime" BU_SG_REL_ VCM SG_ 592 CpbtyAxle2_TqCpbtyRateQltyLe 300;
BA_REL_ "GenSigFirstTimeoutTime" BU_SG_REL_ VCM SG_ 592 CpbtyAxle2_BrkEgyCpctyRi 3000;
BA_REL_ "GenSigTimeoutTime" BU_SG_REL_ VCM SG_ 592 CpbtyAxle2_BrkEgyCpctyRi 300;
BA_REL_ "GenSigFirstTimeoutTime" BU_SG_REL_ VCM SG_ 592 CpbtyAxle1_BrkEgyCpctyQltyLe 3000;
BA_REL_ "GenSigTimeoutTime" BU_SG_REL_ VCM SG_ 592 CpbtyAxle1_BrkEgyCpctyQltyLe 300;
BA_REL_ "GenSigFirstTimeoutTime" BU_SG_REL_ VCM SG_ 592 CpbtyAxle2_PadWearQltyLe 3000;
BA_REL_ "GenSigTimeoutTime" BU_SG_REL_ VCM SG_ 592 CpbtyAxle2_PadWearQltyLe 300;
BA_REL_ "GenSigFirstTimeoutTime" BU_SG_REL_ VCM SG_ 592 CpbtyAxle1_TqCpbtyMaxLe 3000;
BA_REL_ "GenSigTimeoutTime" BU_SG_REL_ VCM SG_ 592 CpbtyAxle1_TqCpbtyMaxLe 300;
BA_REL_ "GenSigFirstTimeoutTime" BU_SG_REL_ VCM SG_ 592 CpbtyAxle3_CRC 3000;
BA_REL_ "GenSigTimeoutTime" BU_SG_REL_ VCM SG_ 592 CpbtyAxle3_CRC 300;
BA_REL_ "GenSigFirstTimeoutTime" BU_SG_REL_ VCM SG_ 592 CpbtyAxle3_SqC 3000;
BA_REL_ "GenSigTimeoutTime" BU_SG_REL_ VCM SG_ 592 CpbtyAxle3_SqC 300;
BA_REL_ "GenSigFirstTimeoutTime" BU_SG_REL_ VCM SG_ 1105 TrailerLiftAxlePos 3000;
BA_REL_ "GenSigTimeoutTime" BU_SG_REL_ VCM SG_ 1105 TrailerLiftAxlePos 600;
BA_REL_ "GenSigFirstTimeoutTime" BU_SG_REL_ VCM SG_ 1105 XBRSystemState 3000;
BA_REL_ "GenSigTimeoutTime" BU_SG_REL_ VCM SG_ 1105 XBRSystemState 600;
BA_REL_ "GenSigFirstTimeoutTime" BU_SG_REL_ VCM SG_ 1105 XPRRequest 3000;
BA_REL_ "GenSigTimeoutTime" BU_SG_REL_ VCM SG_ 1105 XPRRequest 600;
BA_REL_ "GenSigFirstTimeoutTime" BU_SG_REL_ VCM SG_ 1105 TrailerCommunicationType 3000;
BA_REL_ "GenSigTimeoutTime" BU_SG_REL_ VCM SG_ 1105 TrailerCommunicationType 600;
BA_REL_ "GenSigFirstTimeoutTime" BU_SG_REL_ VCM SG_ 439 ABSAxle5Active 3000;
BA_REL_ "GenSigTimeoutTime" BU_SG_REL_ VCM SG_ 439 ABSAxle5Active 120;
BA_REL_ "GenSigFirstTimeoutTime" BU_SG_REL_ VCM SG_ 439 EACompound_CRC 3000;
BA_REL_ "GenSigTimeoutTime" BU_SG_REL_ VCM SG_ 439 EACompound_CRC 120;
BA_REL_ "GenSigFirstTimeoutTime" BU_SG_REL_ VCM SG_ 439 RrAxle1RtWhlBrakeApplPrsHiRng 3000;
BA_REL_ "GenSigTimeoutTime" BU_SG_REL_ VCM SG_ 439 RrAxle1RtWhlBrakeApplPrsHiRng 120;
BA_REL_ "GenSigFirstTimeoutTime" BU_SG_REL_ VCM SG_ 439 RrAxle3RtWhlBrakeApplPrsHiRng 3000;
BA_REL_ "GenSigTimeoutTime" BU_SG_REL_ VCM SG_ 439 RrAxle3RtWhlBrakeApplPrsHiRng 120;
BA_REL_ "GenSigFirstTimeoutTime" BU_SG_REL_ VCM SG_ 439 Trailer1LiftAxle2Pos 3000;
BA_REL_ "GenSigTimeoutTime" BU_SG_REL_ VCM SG_ 439 Trailer1LiftAxle2Pos 120;
BA_REL_ "GenSigFirstTimeoutTime" BU_SG_REL_ VCM SG_ 439 Trailer1TractionHelp 3000;
BA_REL_ "GenSigTimeoutTime" BU_SG_REL_ VCM SG_ 439 Trailer1TractionHelp 120;
BA_REL_ "GenSigFirstTimeoutTime" BU_SG_REL_ VCM SG_ 439 FrAxleRtWhlBrakeApplPrsHiRng 3000;
BA_REL_ "GenSigTimeoutTime" BU_SG_REL_ VCM SG_ 439 FrAxleRtWhlBrakeApplPrsHiRng 120;
BA_REL_ "GenSigFirstTimeoutTime" BU_SG_REL_ VCM SG_ 439 EBSBrakeSwitch 3000;
BA_REL_ "GenSigTimeoutTime" BU_SG_REL_ VCM SG_ 439 EBSBrakeSwitch 120;
BA_REL_ "GenSigFirstTimeoutTime" BU_SG_REL_ VCM SG_ 439 RrAxle3RightWheelRelativeSpeed 3000;
BA_REL_ "GenSigTimeoutTime" BU_SG_REL_ VCM SG_ 439 RrAxle3RightWheelRelativeSpeed 120;
BA_REL_ "GenSigFirstTimeoutTime" BU_SG_REL_ VCM SG_ 439 EACompound_SystemState 3000;
BA_REL_ "GenSigTimeoutTime" BU_SG_REL_ VCM SG_ 439 EACompound_SystemState 120;
BA_REL_ "GenSigFirstTimeoutTime" BU_SG_REL_ VCM SG_ 439 Trailer1LiftAxle1Pos 3000;
BA_REL_ "GenSigTimeoutTime" BU_SG_REL_ VCM SG_ 439 Trailer1LiftAxle1Pos 120;
BA_REL_ "GenSigFirstTimeoutTime" BU_SG_REL_ VCM SG_ 439 EBSBrakePedalPosition 3000;
BA_REL_ "GenSigTimeoutTime" BU_SG_REL_ VCM SG_ 439 EBSBrakePedalPosition 120;
BA_REL_ "GenSigFirstTimeoutTime" BU_SG_REL_ FAS SG_ 439 AntiLockBrakingActive 3000;
BA_REL_ "GenSigTimeoutTime" BU_SG_REL_ FAS SG_ 439 AntiLockBrakingActive 120;
BA_REL_ "GenSigFirstTimeoutTime" BU_SG_REL_ VCM SG_ 439 AntiLockBrakingActive 3000;
BA_REL_ "GenSigTimeoutTime" BU_SG_REL_ VCM SG_ 439 AntiLockBrakingActive 120;
BA_REL_ "GenSigFirstTimeoutTime" BU_SG_REL_ VCM SG_ 439 RrAxle3LeftWheelRelativeSpeed 3000;
BA_REL_ "GenSigTimeoutTime" BU_SG_REL_ VCM SG_ 439 RrAxle3LeftWheelRelativeSpeed 120;
BA_REL_ "GenSigFirstTimeoutTime" BU_SG_REL_ VCM SG_ 439 StretchBrake_Stat 3000;
BA_REL_ "GenSigTimeoutTime" BU_SG_REL_ VCM SG_ 439 StretchBrake_Stat 120;
BA_REL_ "GenSigFirstTimeoutTime" BU_SG_REL_ VCM SG_ 439 HillHolderMode 3000;
BA_REL_ "GenSigTimeoutTime" BU_SG_REL_ VCM SG_ 439 HillHolderMode 120;
BA_REL_ "GenSigFirstTimeoutTime" BU_SG_REL_ VCM SG_ 439 ABSAxle4Active 3000;
BA_REL_ "GenSigTimeoutTime" BU_SG_REL_ VCM SG_ 439 ABSAxle4Active 120;
BA_REL_ "GenSigFirstTimeoutTime" BU_SG_REL_ VCM SG_ 439 TrailerBrake_Stat 3000;
BA_REL_ "GenSigTimeoutTime" BU_SG_REL_ VCM SG_ 439 TrailerBrake_Stat 120;
BA_REL_ "GenSigFirstTimeoutTime" BU_SG_REL_ VCM SG_ 439 CombinedWheelSpeed_CRC 3000;
BA_REL_ "GenSigTimeoutTime" BU_SG_REL_ VCM SG_ 439 CombinedWheelSpeed_CRC 120;
BA_REL_ "GenSigFirstTimeoutTime" BU_SG_REL_ VCM SG_ 439 ABSAxle2Active 3000;
BA_REL_ "GenSigTimeoutTime" BU_SG_REL_ VCM SG_ 439 ABSAxle2Active 120;
BA_REL_ "GenSigFirstTimeoutTime" BU_SG_REL_ VCM SG_ 439 TrailerEBSAmberWarning 3000;
BA_REL_ "GenSigTimeoutTime" BU_SG_REL_ VCM SG_ 439 TrailerEBSAmberWarning 120;
BA_REL_ "GenSigFirstTimeoutTime" BU_SG_REL_ VCM SG_ 439 CombinedWheelSpeed_SqC 3000;
BA_REL_ "GenSigTimeoutTime" BU_SG_REL_ VCM SG_ 439 CombinedWheelSpeed_SqC 120;
BA_REL_ "GenSigFirstTimeoutTime" BU_SG_REL_ VCM SG_ 439 ABSAxle1Active 3000;
BA_REL_ "GenSigTimeoutTime" BU_SG_REL_ VCM SG_ 439 ABSAxle1Active 120;
BA_REL_ "GenSigFirstTimeoutTime" BU_SG_REL_ VCM SG_ 439 RrAxle2LtWhlBrakeApplPrsHiRng 3000;
BA_REL_ "GenSigTimeoutTime" BU_SG_REL_ VCM SG_ 439 RrAxle2LtWhlBrakeApplPrsHiRng 120;
BA_REL_ "GenSigFirstTimeoutTime" BU_SG_REL_ VCM SG_ 439 ABSAxle3Active 3000;
BA_REL_ "GenSigTimeoutTime" BU_SG_REL_ VCM SG_ 439 ABSAxle3Active 120;
BA_REL_ "GenSigFirstTimeoutTime" BU_SG_REL_ VCM SG_ 439 TCMSupply_SqC 3000;
BA_REL_ "GenSigTimeoutTime" BU_SG_REL_ VCM SG_ 439 TCMSupply_SqC 120;
BA_REL_ "GenSigFirstTimeoutTime" BU_SG_REL_ VCM SG_ 439 PusherLiftAxleLoweringInhibit 3000;
BA_REL_ "GenSigTimeoutTime" BU_SG_REL_ VCM SG_ 439 PusherLiftAxleLoweringInhibit 120;
BA_REL_ "GenSigFirstTimeoutTime" BU_SG_REL_ VCM SG_ 439 CombinedWheelSpeed_Quality 3000;
BA_REL_ "GenSigTimeoutTime" BU_SG_REL_ VCM SG_ 439 CombinedWheelSpeed_Quality 120;
BA_REL_ "GenSigFirstTimeoutTime" BU_SG_REL_ VCM SG_ 439 SplitBoxDiffLockActvnFuncReq 3000;
BA_REL_ "GenSigTimeoutTime" BU_SG_REL_ VCM SG_ 439 SplitBoxDiffLockActvnFuncReq 120;
BA_REL_ "GenSigFirstTimeoutTime" BU_SG_REL_ VCM SG_ 439 FrontParkBrakeOverrideStatus 3000;
BA_REL_ "GenSigTimeoutTime" BU_SG_REL_ VCM SG_ 439 FrontParkBrakeOverrideStatus 120;
BA_REL_ "GenSigFirstTimeoutTime" BU_SG_REL_ VCM SG_ 439 SteerableLiftAxleLoweringInhib 3000;
BA_REL_ "GenSigTimeoutTime" BU_SG_REL_ VCM SG_ 439 SteerableLiftAxleLoweringInhib 120;
BA_REL_ "GenSigFirstTimeoutTime" BU_SG_REL_ VCM SG_ 439 RrAxle3LtWhlBrakeApplPrsHiRng 3000;
BA_REL_ "GenSigTimeoutTime" BU_SG_REL_ VCM SG_ 439 RrAxle3LtWhlBrakeApplPrsHiRng 120;
BA_REL_ "GenSigFirstTimeoutTime" BU_SG_REL_ VCM SG_ 439 EACompound_AppliedRatio 3000;
BA_REL_ "GenSigTimeoutTime" BU_SG_REL_ VCM SG_ 439 EACompound_AppliedRatio 120;
BA_REL_ "GenSigFirstTimeoutTime" BU_SG_REL_ VCM SG_ 439 BrakingSystemPressureLim_rqst 3000;
BA_REL_ "GenSigTimeoutTime" BU_SG_REL_ VCM SG_ 439 BrakingSystemPressureLim_rqst 120;
BA_REL_ "GenSigFirstTimeoutTime" BU_SG_REL_ VCM SG_ 439 RrAxle1LtWhlBrakeApplPrsHiRng 3000;
BA_REL_ "GenSigTimeoutTime" BU_SG_REL_ VCM SG_ 439 RrAxle1LtWhlBrakeApplPrsHiRng 120;
BA_REL_ "GenSigFirstTimeoutTime" BU_SG_REL_ VCM SG_ 439 EACompound_SqC 3000;
BA_REL_ "GenSigTimeoutTime" BU_SG_REL_ VCM SG_ 439 EACompound_SqC 120;
BA_REL_ "GenSigFirstTimeoutTime" BU_SG_REL_ VCM SG_ 439 TCMSupply_CRC 3000;
BA_REL_ "GenSigTimeoutTime" BU_SG_REL_ VCM SG_ 439 TCMSupply_CRC 120;
BA_REL_ "GenSigFirstTimeoutTime" BU_SG_REL_ VCM SG_ 439 TrailerControlPressure 3000;
BA_REL_ "GenSigTimeoutTime" BU_SG_REL_ VCM SG_ 439 TrailerControlPressure 120;
BA_REL_ "GenSigFirstTimeoutTime" BU_SG_REL_ VCM SG_ 439 RrAxle2RtWhlBrakeApplPrsHiRng 3000;
BA_REL_ "GenSigTimeoutTime" BU_SG_REL_ VCM SG_ 439 RrAxle2RtWhlBrakeApplPrsHiRng 120;
BA_REL_ "GenSigFirstTimeoutTime" BU_SG_REL_ VCM SG_ 439 ScndRrAxlDiffLckActvnFuncReq 3000;
BA_REL_ "GenSigTimeoutTime" BU_SG_REL_ VCM SG_ 439 ScndRrAxlDiffLckActvnFuncReq 120;
BA_REL_ "GenSigFirstTimeoutTime" BU_SG_REL_ VCM SG_ 439 TCMSupply_TrailerPressure 3000;
BA_REL_ "GenSigTimeoutTime" BU_SG_REL_ VCM SG_ 439 TCMSupply_TrailerPressure 120;
BA_REL_ "GenSigFirstTimeoutTime" BU_SG_REL_ VCM SG_ 439 CombinedWheelSpeed_Speed 3000;
BA_REL_ "GenSigTimeoutTime" BU_SG_REL_ VCM SG_ 439 CombinedWheelSpeed_Speed 120;
BA_REL_ "GenSigFirstTimeoutTime" BU_SG_REL_ VCM SG_ 439 HSAState 3000;
BA_REL_ "GenSigTimeoutTime" BU_SG_REL_ VCM SG_ 439 HSAState 120;
BA_REL_ "GenSigFirstTimeoutTime" BU_SG_REL_ VCM SG_ 439 FrAxleLtWhlBrakeApplPrsHiRng 3000;
BA_REL_ "GenSigTimeoutTime" BU_SG_REL_ VCM SG_ 439 FrAxleLtWhlBrakeApplPrsHiRng 120;
BA_REL_ "GenSigFirstTimeoutTime" BU_SG_REL_ VCM SG_ 315 FrontAxleLeftWheelSpeed 3000;
BA_REL_ "GenSigTimeoutTime" BU_SG_REL_ VCM SG_ 315 FrontAxleLeftWheelSpeed 100;
BA_REL_ "GenSigFirstTimeoutTime" BU_SG_REL_ FAS SG_ 315 FrontAxleLeftWheelSpeed 3000;
BA_REL_ "GenSigTimeoutTime" BU_SG_REL_ FAS SG_ 315 FrontAxleLeftWheelSpeed 100;
BA_REL_ "GenSigFirstTimeoutTime" BU_SG_REL_ VCM SG_ 315 SteeringWheel_AngleCRC 3000;
BA_REL_ "GenSigTimeoutTime" BU_SG_REL_ VCM SG_ 315 SteeringWheel_AngleCRC 100;
BA_REL_ "GenSigFirstTimeoutTime" BU_SG_REL_ VCM SG_ 315 SteeringWheel_AngleCounter 3000;
BA_REL_ "GenSigTimeoutTime" BU_SG_REL_ VCM SG_ 315 SteeringWheel_AngleCounter 100;
BA_REL_ "GenSigFirstTimeoutTime" BU_SG_REL_ VCM SG_ 315 FrontAxleRightWheelSpeed 3000;
BA_REL_ "GenSigTimeoutTime" BU_SG_REL_ VCM SG_ 315 FrontAxleRightWheelSpeed 100;
BA_REL_ "GenSigFirstTimeoutTime" BU_SG_REL_ FAS SG_ 315 FrontAxleRightWheelSpeed 3000;
BA_REL_ "GenSigTimeoutTime" BU_SG_REL_ FAS SG_ 315 FrontAxleRightWheelSpeed 100;
BA_REL_ "GenSigFirstTimeoutTime" BU_SG_REL_ VCM SG_ 315 SteeringWheel_AngleValue 3000;
BA_REL_ "GenSigTimeoutTime" BU_SG_REL_ VCM SG_ 315 SteeringWheel_AngleValue 100;
BA_REL_ "GenSigFirstTimeoutTime" BU_SG_REL_ VCM SG_ 315 SteeringWheelAngle 3000;
BA_REL_ "GenSigTimeoutTime" BU_SG_REL_ VCM SG_ 315 SteeringWheelAngle 100;
BA_REL_ "GenSigFirstTimeoutTime" BU_SG_REL_ FAS SG_ 315 SteeringWheelAngle 3000;
BA_REL_ "GenSigTimeoutTime" BU_SG_REL_ FAS SG_ 315 SteeringWheelAngle 100;
BA_REL_ "GenSigFirstTimeoutTime" BU_SG_REL_ VCM SG_ 315 SteeringWheelAngleComp 3000;
BA_REL_ "GenSigTimeoutTime" BU_SG_REL_ VCM SG_ 315 SteeringWheelAngleComp 100;
BA_REL_ "GenSigFirstTimeoutTime" BU_SG_REL_ FAS SG_ 315 SteeringWheelAngleComp 3000;
BA_REL_ "GenSigTimeoutTime" BU_SG_REL_ FAS SG_ 315 SteeringWheelAngleComp 100;
BA_REL_ "GenSigFirstTimeoutTime" BU_SG_REL_ FAS SG_ 315 YawRate 3000;
BA_REL_ "GenSigTimeoutTime" BU_SG_REL_ FAS SG_ 315 YawRate 100;
BA_REL_ "GenSigFirstTimeoutTime" BU_SG_REL_ VCM SG_ 315 YawRate 3000;
BA_REL_ "GenSigTimeoutTime" BU_SG_REL_ VCM SG_ 315 YawRate 100;
BA_REL_ "GenSigFirstTimeoutTime" BU_SG_REL_ VCM SG_ 1491 DiagFaultStat_FAS_FailTA 24000;
BA_REL_ "GenSigTimeoutTime" BU_SG_REL_ VCM SG_ 1491 DiagFaultStat_FAS_FailTA 6000;
BA_REL_ "GenSigFirstTimeoutTime" BU_SG_REL_ VCM SG_ 1491 DiagFaultStat_FAS_EcuAdr 24000;
BA_REL_ "GenSigTimeoutTime" BU_SG_REL_ VCM SG_ 1491 DiagFaultStat_FAS_EcuAdr 6000;
BA_REL_ "GenSigFirstTimeoutTime" BU_SG_REL_ VCM SG_ 1491 DiagFaultStat_FAS_DtcIdA 24000;
BA_REL_ "GenSigTimeoutTime" BU_SG_REL_ VCM SG_ 1491 DiagFaultStat_FAS_DtcIdA 6000;
BA_REL_ "GenSigFirstTimeoutTime" BU_SG_REL_ VCM SG_ 1491 DiagFaultStat_FAS_DtcIdB 24000;
BA_REL_ "GenSigTimeoutTime" BU_SG_REL_ VCM SG_ 1491 DiagFaultStat_FAS_DtcIdB 6000;
BA_REL_ "GenSigFirstTimeoutTime" BU_SG_REL_ VCM SG_ 1491 DiagFaultStat_FAS_FailTB 24000;
BA_REL_ "GenSigTimeoutTime" BU_SG_REL_ VCM SG_ 1491 DiagFaultStat_FAS_FailTB 6000;
VAL_ 594 CpbtyAxle4_TqCpbtyRateQltyLe 15 "QualityEnum4Bit_NotAvailable" 14 "QualityEnum4Bit_Error" 13 "QualityEnum4Bit_Spare12" 12 "QualityEnum4Bit_Spare11" 11 "QualityEnum4Bit_Spare10" 10 "QualityEnum4Bit_Spare9" 9 "QualityEnum4Bit_Spare8" 8 "QualityEnum4Bit_Spare7" 7 "QualityEnum4Bit_Spare6" 6 "QualityEnum4Bit_Spare5" 5 "QualityEnum4Bit_Spare4" 4 "QualityEnum4Bit_Spare3" 3 "QualityEnum4Bit_Spare2" 2 "QualityEnum4Bit_Spare1" 1 "QualityEnum4Bit_Acceptable" 0 "QualityEnum4Bit_NotAcceptable" ;
VAL_ 594 CpbtyAxle4_BrkEgyCpctyQltyRi 15 "QualityEnum4Bit_NotAvailable" 14 "QualityEnum4Bit_Error" 13 "QualityEnum4Bit_Spare12" 12 "QualityEnum4Bit_Spare11" 11 "QualityEnum4Bit_Spare10" 10 "QualityEnum4Bit_Spare9" 9 "QualityEnum4Bit_Spare8" 8 "QualityEnum4Bit_Spare7" 7 "QualityEnum4Bit_Spare6" 6 "QualityEnum4Bit_Spare5" 5 "QualityEnum4Bit_Spare4" 4 "QualityEnum4Bit_Spare3" 3 "QualityEnum4Bit_Spare2" 2 "QualityEnum4Bit_Spare1" 1 "QualityEnum4Bit_Acceptable" 0 "QualityEnum4Bit_NotAcceptable" ;
VAL_ 594 CpbtyAxle5_TqCpbtyQltyLe 15 "QualityEnum4Bit_NotAvailable" 14 "QualityEnum4Bit_Error" 13 "QualityEnum4Bit_Spare12" 12 "QualityEnum4Bit_Spare11" 11 "QualityEnum4Bit_Spare10" 10 "QualityEnum4Bit_Spare9" 9 "QualityEnum4Bit_Spare8" 8 "QualityEnum4Bit_Spare7" 7 "QualityEnum4Bit_Spare6" 6 "QualityEnum4Bit_Spare5" 5 "QualityEnum4Bit_Spare4" 4 "QualityEnum4Bit_Spare3" 3 "QualityEnum4Bit_Spare2" 2 "QualityEnum4Bit_Spare1" 1 "QualityEnum4Bit_Acceptable" 0 "QualityEnum4Bit_NotAcceptable" ;
VAL_ 594 CpbtyAxle6_TqCpbtyRateQltyLe 15 "QualityEnum4Bit_NotAvailable" 14 "QualityEnum4Bit_Error" 13 "QualityEnum4Bit_Spare12" 12 "QualityEnum4Bit_Spare11" 11 "QualityEnum4Bit_Spare10" 10 "QualityEnum4Bit_Spare9" 9 "QualityEnum4Bit_Spare8" 8 "QualityEnum4Bit_Spare7" 7 "QualityEnum4Bit_Spare6" 6 "QualityEnum4Bit_Spare5" 5 "QualityEnum4Bit_Spare4" 4 "QualityEnum4Bit_Spare3" 3 "QualityEnum4Bit_Spare2" 2 "QualityEnum4Bit_Spare1" 1 "QualityEnum4Bit_Acceptable" 0 "QualityEnum4Bit_NotAcceptable" ;
VAL_ 594 CpbtyAxle6_TqCpbtyRateQltyRi 15 "QualityEnum4Bit_NotAvailable" 14 "QualityEnum4Bit_Error" 13 "QualityEnum4Bit_Spare12" 12 "QualityEnum4Bit_Spare11" 11 "QualityEnum4Bit_Spare10" 10 "QualityEnum4Bit_Spare9" 9 "QualityEnum4Bit_Spare8" 8 "QualityEnum4Bit_Spare7" 7 "QualityEnum4Bit_Spare6" 6 "QualityEnum4Bit_Spare5" 5 "QualityEnum4Bit_Spare4" 4 "QualityEnum4Bit_Spare3" 3 "QualityEnum4Bit_Spare2" 2 "QualityEnum4Bit_Spare1" 1 "QualityEnum4Bit_Acceptable" 0 "QualityEnum4Bit_NotAcceptable" ;
VAL_ 594 CpbtyAxle5_SlipCtrlEna 3 "DisableEnable_NotAvailable" 2 "DisableEnable_Error" 1 "DisableEnable_Enable" 0 "DisableEnable_Disable" ;
VAL_ 594 CpbtyAxle5_PadWearQltyLe 15 "QualityEnum4Bit_NotAvailable" 14 "QualityEnum4Bit_Error" 13 "QualityEnum4Bit_Spare12" 12 "QualityEnum4Bit_Spare11" 11 "QualityEnum4Bit_Spare10" 10 "QualityEnum4Bit_Spare9" 9 "QualityEnum4Bit_Spare8" 8 "QualityEnum4Bit_Spare7" 7 "QualityEnum4Bit_Spare6" 6 "QualityEnum4Bit_Spare5" 5 "QualityEnum4Bit_Spare4" 4 "QualityEnum4Bit_Spare3" 3 "QualityEnum4Bit_Spare2" 2 "QualityEnum4Bit_Spare1" 1 "QualityEnum4Bit_Acceptable" 0 "QualityEnum4Bit_NotAcceptable" ;
VAL_ 594 CpbtyAxle6_BrkEgyCpctyQltyRi 15 "QualityEnum4Bit_NotAvailable" 14 "QualityEnum4Bit_Error" 13 "QualityEnum4Bit_Spare12" 12 "QualityEnum4Bit_Spare11" 11 "QualityEnum4Bit_Spare10" 10 "QualityEnum4Bit_Spare9" 9 "QualityEnum4Bit_Spare8" 8 "QualityEnum4Bit_Spare7" 7 "QualityEnum4Bit_Spare6" 6 "QualityEnum4Bit_Spare5" 5 "QualityEnum4Bit_Spare4" 4 "QualityEnum4Bit_Spare3" 3 "QualityEnum4Bit_Spare2" 2 "QualityEnum4Bit_Spare1" 1 "QualityEnum4Bit_Acceptable" 0 "QualityEnum4Bit_NotAcceptable" ;
VAL_ 594 CpbtyAxle5_BrkEgyCpctyQltyLe 15 "QualityEnum4Bit_NotAvailable" 14 "QualityEnum4Bit_Error" 13 "QualityEnum4Bit_Spare12" 12 "QualityEnum4Bit_Spare11" 11 "QualityEnum4Bit_Spare10" 10 "QualityEnum4Bit_Spare9" 9 "QualityEnum4Bit_Spare8" 8 "QualityEnum4Bit_Spare7" 7 "QualityEnum4Bit_Spare6" 6 "QualityEnum4Bit_Spare5" 5 "QualityEnum4Bit_Spare4" 4 "QualityEnum4Bit_Spare3" 3 "QualityEnum4Bit_Spare2" 2 "QualityEnum4Bit_Spare1" 1 "QualityEnum4Bit_Acceptable" 0 "QualityEnum4Bit_NotAcceptable" ;
VAL_ 594 CpbtyAxle6_PadWearQltyRi 15 "QualityEnum4Bit_NotAvailable" 14 "QualityEnum4Bit_Error" 13 "QualityEnum4Bit_Spare12" 12 "QualityEnum4Bit_Spare11" 11 "QualityEnum4Bit_Spare10" 10 "QualityEnum4Bit_Spare9" 9 "QualityEnum4Bit_Spare8" 8 "QualityEnum4Bit_Spare7" 7 "QualityEnum4Bit_Spare6" 6 "QualityEnum4Bit_Spare5" 5 "QualityEnum4Bit_Spare4" 4 "QualityEnum4Bit_Spare3" 3 "QualityEnum4Bit_Spare2" 2 "QualityEnum4Bit_Spare1" 1 "QualityEnum4Bit_Acceptable" 0 "QualityEnum4Bit_NotAcceptable" ;
VAL_ 594 CpbtyAxle4_TqCpbtyQltyLe 15 "QualityEnum4Bit_NotAvailable" 14 "QualityEnum4Bit_Error" 13 "QualityEnum4Bit_Spare12" 12 "QualityEnum4Bit_Spare11" 11 "QualityEnum4Bit_Spare10" 10 "QualityEnum4Bit_Spare9" 9 "QualityEnum4Bit_Spare8" 8 "QualityEnum4Bit_Spare7" 7 "QualityEnum4Bit_Spare6" 6 "QualityEnum4Bit_Spare5" 5 "QualityEnum4Bit_Spare4" 4 "QualityEnum4Bit_Spare3" 3 "QualityEnum4Bit_Spare2" 2 "QualityEnum4Bit_Spare1" 1 "QualityEnum4Bit_Acceptable" 0 "QualityEnum4Bit_NotAcceptable" ;
VAL_ 594 CpbtyAxle4_SlipCtrlEna 3 "DisableEnable_NotAvailable" 2 "DisableEnable_Error" 1 "DisableEnable_Enable" 0 "DisableEnable_Disable" ;
VAL_ 594 CpbtyAxle6_TqCpbtyQltyRi 15 "QualityEnum4Bit_NotAvailable" 14 "QualityEnum4Bit_Error" 13 "QualityEnum4Bit_Spare12" 12 "QualityEnum4Bit_Spare11" 11 "QualityEnum4Bit_Spare10" 10 "QualityEnum4Bit_Spare9" 9 "QualityEnum4Bit_Spare8" 8 "QualityEnum4Bit_Spare7" 7 "QualityEnum4Bit_Spare6" 6 "QualityEnum4Bit_Spare5" 5 "QualityEnum4Bit_Spare4" 4 "QualityEnum4Bit_Spare3" 3 "QualityEnum4Bit_Spare2" 2 "QualityEnum4Bit_Spare1" 1 "QualityEnum4Bit_Acceptable" 0 "QualityEnum4Bit_NotAcceptable" ;
VAL_ 594 CpbtyAxle5_TqCpbtyRateQltyLe 15 "QualityEnum4Bit_NotAvailable" 14 "QualityEnum4Bit_Error" 13 "QualityEnum4Bit_Spare12" 12 "QualityEnum4Bit_Spare11" 11 "QualityEnum4Bit_Spare10" 10 "QualityEnum4Bit_Spare9" 9 "QualityEnum4Bit_Spare8" 8 "QualityEnum4Bit_Spare7" 7 "QualityEnum4Bit_Spare6" 6 "QualityEnum4Bit_Spare5" 5 "QualityEnum4Bit_Spare4" 4 "QualityEnum4Bit_Spare3" 3 "QualityEnum4Bit_Spare2" 2 "QualityEnum4Bit_Spare1" 1 "QualityEnum4Bit_Acceptable" 0 "QualityEnum4Bit_NotAcceptable" ;
VAL_ 594 CpbtyAxle6_PadWearQltyLe 15 "QualityEnum4Bit_NotAvailable" 14 "QualityEnum4Bit_Error" 13 "QualityEnum4Bit_Spare12" 12 "QualityEnum4Bit_Spare11" 11 "QualityEnum4Bit_Spare10" 10 "QualityEnum4Bit_Spare9" 9 "QualityEnum4Bit_Spare8" 8 "QualityEnum4Bit_Spare7" 7 "QualityEnum4Bit_Spare6" 6 "QualityEnum4Bit_Spare5" 5 "QualityEnum4Bit_Spare4" 4 "QualityEnum4Bit_Spare3" 3 "QualityEnum4Bit_Spare2" 2 "QualityEnum4Bit_Spare1" 1 "QualityEnum4Bit_Acceptable" 0 "QualityEnum4Bit_NotAcceptable" ;
VAL_ 594 CpbtyAxle5_TqCpbtyRateQltyRi 15 "QualityEnum4Bit_NotAvailable" 14 "QualityEnum4Bit_Error" 13 "QualityEnum4Bit_Spare12" 12 "QualityEnum4Bit_Spare11" 11 "QualityEnum4Bit_Spare10" 10 "QualityEnum4Bit_Spare9" 9 "QualityEnum4Bit_Spare8" 8 "QualityEnum4Bit_Spare7" 7 "QualityEnum4Bit_Spare6" 6 "QualityEnum4Bit_Spare5" 5 "QualityEnum4Bit_Spare4" 4 "QualityEnum4Bit_Spare3" 3 "QualityEnum4Bit_Spare2" 2 "QualityEnum4Bit_Spare1" 1 "QualityEnum4Bit_Acceptable" 0 "QualityEnum4Bit_NotAcceptable" ;
VAL_ 594 CpbtyAxle4_TqCpbtyQltyRi 15 "QualityEnum4Bit_NotAvailable" 14 "QualityEnum4Bit_Error" 13 "QualityEnum4Bit_Spare12" 12 "QualityEnum4Bit_Spare11" 11 "QualityEnum4Bit_Spare10" 10 "QualityEnum4Bit_Spare9" 9 "QualityEnum4Bit_Spare8" 8 "QualityEnum4Bit_Spare7" 7 "QualityEnum4Bit_Spare6" 6 "QualityEnum4Bit_Spare5" 5 "QualityEnum4Bit_Spare4" 4 "QualityEnum4Bit_Spare3" 3 "QualityEnum4Bit_Spare2" 2 "QualityEnum4Bit_Spare1" 1 "QualityEnum4Bit_Acceptable" 0 "QualityEnum4Bit_NotAcceptable" ;
VAL_ 594 CpbtyAxle6_SlipCtrlEna 3 "DisableEnable_NotAvailable" 2 "DisableEnable_Error" 1 "DisableEnable_Enable" 0 "DisableEnable_Disable" ;
VAL_ 594 CpbtyAxle5_TqCpbtyQltyRi 15 "QualityEnum4Bit_NotAvailable" 14 "QualityEnum4Bit_Error" 13 "QualityEnum4Bit_Spare12" 12 "QualityEnum4Bit_Spare11" 11 "QualityEnum4Bit_Spare10" 10 "QualityEnum4Bit_Spare9" 9 "QualityEnum4Bit_Spare8" 8 "QualityEnum4Bit_Spare7" 7 "QualityEnum4Bit_Spare6" 6 "QualityEnum4Bit_Spare5" 5 "QualityEnum4Bit_Spare4" 4 "QualityEnum4Bit_Spare3" 3 "QualityEnum4Bit_Spare2" 2 "QualityEnum4Bit_Spare1" 1 "QualityEnum4Bit_Acceptable" 0 "QualityEnum4Bit_NotAcceptable" ;
VAL_ 594 CpbtyAxle4_BrkEgyCpctyQltyLe 15 "QualityEnum4Bit_NotAvailable" 14 "QualityEnum4Bit_Error" 13 "QualityEnum4Bit_Spare12" 12 "QualityEnum4Bit_Spare11" 11 "QualityEnum4Bit_Spare10" 10 "QualityEnum4Bit_Spare9" 9 "QualityEnum4Bit_Spare8" 8 "QualityEnum4Bit_Spare7" 7 "QualityEnum4Bit_Spare6" 6 "QualityEnum4Bit_Spare5" 5 "QualityEnum4Bit_Spare4" 4 "QualityEnum4Bit_Spare3" 3 "QualityEnum4Bit_Spare2" 2 "QualityEnum4Bit_Spare1" 1 "QualityEnum4Bit_Acceptable" 0 "QualityEnum4Bit_NotAcceptable" ;
VAL_ 594 CpbtyAxle4_TqCpbtyRateQltyRi 15 "QualityEnum4Bit_NotAvailable" 14 "QualityEnum4Bit_Error" 13 "QualityEnum4Bit_Spare12" 12 "QualityEnum4Bit_Spare11" 11 "QualityEnum4Bit_Spare10" 10 "QualityEnum4Bit_Spare9" 9 "QualityEnum4Bit_Spare8" 8 "QualityEnum4Bit_Spare7" 7 "QualityEnum4Bit_Spare6" 6 "QualityEnum4Bit_Spare5" 5 "QualityEnum4Bit_Spare4" 4 "QualityEnum4Bit_Spare3" 3 "QualityEnum4Bit_Spare2" 2 "QualityEnum4Bit_Spare1" 1 "QualityEnum4Bit_Acceptable" 0 "QualityEnum4Bit_NotAcceptable" ;
VAL_ 594 CpbtyAxle5_PadWearQltyRi 15 "QualityEnum4Bit_NotAvailable" 14 "QualityEnum4Bit_Error" 13 "QualityEnum4Bit_Spare12" 12 "QualityEnum4Bit_Spare11" 11 "QualityEnum4Bit_Spare10" 10 "QualityEnum4Bit_Spare9" 9 "QualityEnum4Bit_Spare8" 8 "QualityEnum4Bit_Spare7" 7 "QualityEnum4Bit_Spare6" 6 "QualityEnum4Bit_Spare5" 5 "QualityEnum4Bit_Spare4" 4 "QualityEnum4Bit_Spare3" 3 "QualityEnum4Bit_Spare2" 2 "QualityEnum4Bit_Spare1" 1 "QualityEnum4Bit_Acceptable" 0 "QualityEnum4Bit_NotAcceptable" ;
VAL_ 594 CpbtyAxle6_BrkEgyCpctyQltyLe 15 "QualityEnum4Bit_NotAvailable" 14 "QualityEnum4Bit_Error" 13 "QualityEnum4Bit_Spare12" 12 "QualityEnum4Bit_Spare11" 11 "QualityEnum4Bit_Spare10" 10 "QualityEnum4Bit_Spare9" 9 "QualityEnum4Bit_Spare8" 8 "QualityEnum4Bit_Spare7" 7 "QualityEnum4Bit_Spare6" 6 "QualityEnum4Bit_Spare5" 5 "QualityEnum4Bit_Spare4" 4 "QualityEnum4Bit_Spare3" 3 "QualityEnum4Bit_Spare2" 2 "QualityEnum4Bit_Spare1" 1 "QualityEnum4Bit_Acceptable" 0 "QualityEnum4Bit_NotAcceptable" ;
VAL_ 594 CpbtyAxle6_TqCpbtyQltyLe 15 "QualityEnum4Bit_NotAvailable" 14 "QualityEnum4Bit_Error" 13 "QualityEnum4Bit_Spare12" 12 "QualityEnum4Bit_Spare11" 11 "QualityEnum4Bit_Spare10" 10 "QualityEnum4Bit_Spare9" 9 "QualityEnum4Bit_Spare8" 8 "QualityEnum4Bit_Spare7" 7 "QualityEnum4Bit_Spare6" 6 "QualityEnum4Bit_Spare5" 5 "QualityEnum4Bit_Spare4" 4 "QualityEnum4Bit_Spare3" 3 "QualityEnum4Bit_Spare2" 2 "QualityEnum4Bit_Spare1" 1 "QualityEnum4Bit_Acceptable" 0 "QualityEnum4Bit_NotAcceptable" ;
VAL_ 594 CpbtyAxle5_BrkEgyCpctyQltyRi 15 "QualityEnum4Bit_NotAvailable" 14 "QualityEnum4Bit_Error" 13 "QualityEnum4Bit_Spare12" 12 "QualityEnum4Bit_Spare11" 11 "QualityEnum4Bit_Spare10" 10 "QualityEnum4Bit_Spare9" 9 "QualityEnum4Bit_Spare8" 8 "QualityEnum4Bit_Spare7" 7 "QualityEnum4Bit_Spare6" 6 "QualityEnum4Bit_Spare5" 5 "QualityEnum4Bit_Spare4" 4 "QualityEnum4Bit_Spare3" 3 "QualityEnum4Bit_Spare2" 2 "QualityEnum4Bit_Spare1" 1 "QualityEnum4Bit_Acceptable" 0 "QualityEnum4Bit_NotAcceptable" ;
VAL_ 594 CpbtyAxle4_PadWearQltyRi 15 "QualityEnum4Bit_NotAvailable" 14 "QualityEnum4Bit_Error" 13 "QualityEnum4Bit_Spare12" 12 "QualityEnum4Bit_Spare11" 11 "QualityEnum4Bit_Spare10" 10 "QualityEnum4Bit_Spare9" 9 "QualityEnum4Bit_Spare8" 8 "QualityEnum4Bit_Spare7" 7 "QualityEnum4Bit_Spare6" 6 "QualityEnum4Bit_Spare5" 5 "QualityEnum4Bit_Spare4" 4 "QualityEnum4Bit_Spare3" 3 "QualityEnum4Bit_Spare2" 2 "QualityEnum4Bit_Spare1" 1 "QualityEnum4Bit_Acceptable" 0 "QualityEnum4Bit_NotAcceptable" ;
VAL_ 594 CpbtyAxle4_PadWearQltyLe 15 "QualityEnum4Bit_NotAvailable" 14 "QualityEnum4Bit_Error" 13 "QualityEnum4Bit_Spare12" 12 "QualityEnum4Bit_Spare11" 11 "QualityEnum4Bit_Spare10" 10 "QualityEnum4Bit_Spare9" 9 "QualityEnum4Bit_Spare8" 8 "QualityEnum4Bit_Spare7" 7 "QualityEnum4Bit_Spare6" 6 "QualityEnum4Bit_Spare5" 5 "QualityEnum4Bit_Spare4" 4 "QualityEnum4Bit_Spare3" 3 "QualityEnum4Bit_Spare2" 2 "QualityEnum4Bit_Spare1" 1 "QualityEnum4Bit_Acceptable" 0 "QualityEnum4Bit_NotAcceptable" ;
VAL_ 592 CpbtyAxle3_BrkEgyCpctyQltyLe 15 "QualityEnum4Bit_NotAvailable" 14 "QualityEnum4Bit_Error" 13 "QualityEnum4Bit_Spare12" 12 "QualityEnum4Bit_Spare11" 11 "QualityEnum4Bit_Spare10" 10 "QualityEnum4Bit_Spare9" 9 "QualityEnum4Bit_Spare8" 8 "QualityEnum4Bit_Spare7" 7 "QualityEnum4Bit_Spare6" 6 "QualityEnum4Bit_Spare5" 5 "QualityEnum4Bit_Spare4" 4 "QualityEnum4Bit_Spare3" 3 "QualityEnum4Bit_Spare2" 2 "QualityEnum4Bit_Spare1" 1 "QualityEnum4Bit_Acceptable" 0 "QualityEnum4Bit_NotAcceptable" ;
VAL_ 592 CpbtyAxle3_TqCpbtyRateQltyRi 15 "QualityEnum4Bit_NotAvailable" 14 "QualityEnum4Bit_Error" 13 "QualityEnum4Bit_Spare12" 12 "QualityEnum4Bit_Spare11" 11 "QualityEnum4Bit_Spare10" 10 "QualityEnum4Bit_Spare9" 9 "QualityEnum4Bit_Spare8" 8 "QualityEnum4Bit_Spare7" 7 "QualityEnum4Bit_Spare6" 6 "QualityEnum4Bit_Spare5" 5 "QualityEnum4Bit_Spare4" 4 "QualityEnum4Bit_Spare3" 3 "QualityEnum4Bit_Spare2" 2 "QualityEnum4Bit_Spare1" 1 "QualityEnum4Bit_Acceptable" 0 "QualityEnum4Bit_NotAcceptable" ;
VAL_ 592 CpbtyAxle1_PadWearQltyLe 15 "QualityEnum4Bit_NotAvailable" 14 "QualityEnum4Bit_Error" 13 "QualityEnum4Bit_Spare12" 12 "QualityEnum4Bit_Spare11" 11 "QualityEnum4Bit_Spare10" 10 "QualityEnum4Bit_Spare9" 9 "QualityEnum4Bit_Spare8" 8 "QualityEnum4Bit_Spare7" 7 "QualityEnum4Bit_Spare6" 6 "QualityEnum4Bit_Spare5" 5 "QualityEnum4Bit_Spare4" 4 "QualityEnum4Bit_Spare3" 3 "QualityEnum4Bit_Spare2" 2 "QualityEnum4Bit_Spare1" 1 "QualityEnum4Bit_Acceptable" 0 "QualityEnum4Bit_NotAcceptable" ;
VAL_ 592 CpbtyAxle1_SlipCtrlEna 3 "DisableEnable_NotAvailable" 2 "DisableEnable_Error" 1 "DisableEnable_Enable" 0 "DisableEnable_Disable" ;
VAL_ 592 CpbtyAxle3_TqCpbtyRateQltyLe 15 "QualityEnum4Bit_NotAvailable" 14 "QualityEnum4Bit_Error" 13 "QualityEnum4Bit_Spare12" 12 "QualityEnum4Bit_Spare11" 11 "QualityEnum4Bit_Spare10" 10 "QualityEnum4Bit_Spare9" 9 "QualityEnum4Bit_Spare8" 8 "QualityEnum4Bit_Spare7" 7 "QualityEnum4Bit_Spare6" 6 "QualityEnum4Bit_Spare5" 5 "QualityEnum4Bit_Spare4" 4 "QualityEnum4Bit_Spare3" 3 "QualityEnum4Bit_Spare2" 2 "QualityEnum4Bit_Spare1" 1 "QualityEnum4Bit_Acceptable" 0 "QualityEnum4Bit_NotAcceptable" ;
VAL_ 592 CpbtyAxle1_BrkEgyCpctyQltyRi 15 "QualityEnum4Bit_NotAvailable" 14 "QualityEnum4Bit_Error" 13 "QualityEnum4Bit_Spare12" 12 "QualityEnum4Bit_Spare11" 11 "QualityEnum4Bit_Spare10" 10 "QualityEnum4Bit_Spare9" 9 "QualityEnum4Bit_Spare8" 8 "QualityEnum4Bit_Spare7" 7 "QualityEnum4Bit_Spare6" 6 "QualityEnum4Bit_Spare5" 5 "QualityEnum4Bit_Spare4" 4 "QualityEnum4Bit_Spare3" 3 "QualityEnum4Bit_Spare2" 2 "QualityEnum4Bit_Spare1" 1 "QualityEnum4Bit_Acceptable" 0 "QualityEnum4Bit_NotAcceptable" ;
VAL_ 592 CpbtyAxle2_BrkEgyCpctyQltyLe 15 "QualityEnum4Bit_NotAvailable" 14 "QualityEnum4Bit_Error" 13 "QualityEnum4Bit_Spare12" 12 "QualityEnum4Bit_Spare11" 11 "QualityEnum4Bit_Spare10" 10 "QualityEnum4Bit_Spare9" 9 "QualityEnum4Bit_Spare8" 8 "QualityEnum4Bit_Spare7" 7 "QualityEnum4Bit_Spare6" 6 "QualityEnum4Bit_Spare5" 5 "QualityEnum4Bit_Spare4" 4 "QualityEnum4Bit_Spare3" 3 "QualityEnum4Bit_Spare2" 2 "QualityEnum4Bit_Spare1" 1 "QualityEnum4Bit_Acceptable" 0 "QualityEnum4Bit_NotAcceptable" ;
VAL_ 592 CpbtyAxle3_SlipCtrlEna 3 "DisableEnable_NotAvailable" 2 "DisableEnable_Error" 1 "DisableEnable_Enable" 0 "DisableEnable_Disable" ;
VAL_ 592 CpbtyAxle3_TqCpbtyQltyLe 15 "QualityEnum4Bit_NotAvailable" 14 "QualityEnum4Bit_Error" 13 "QualityEnum4Bit_Spare12" 12 "QualityEnum4Bit_Spare11" 11 "QualityEnum4Bit_Spare10" 10 "QualityEnum4Bit_Spare9" 9 "QualityEnum4Bit_Spare8" 8 "QualityEnum4Bit_Spare7" 7 "QualityEnum4Bit_Spare6" 6 "QualityEnum4Bit_Spare5" 5 "QualityEnum4Bit_Spare4" 4 "QualityEnum4Bit_Spare3" 3 "QualityEnum4Bit_Spare2" 2 "QualityEnum4Bit_Spare1" 1 "QualityEnum4Bit_Acceptable" 0 "QualityEnum4Bit_NotAcceptable" ;
VAL_ 592 CpbtyAxle1_TqCpbtyQltyLe 15 "QualityEnum4Bit_NotAvailable" 14 "QualityEnum4Bit_Error" 13 "QualityEnum4Bit_Spare12" 12 "QualityEnum4Bit_Spare11" 11 "QualityEnum4Bit_Spare10" 10 "QualityEnum4Bit_Spare9" 9 "QualityEnum4Bit_Spare8" 8 "QualityEnum4Bit_Spare7" 7 "QualityEnum4Bit_Spare6" 6 "QualityEnum4Bit_Spare5" 5 "QualityEnum4Bit_Spare4" 4 "QualityEnum4Bit_Spare3" 3 "QualityEnum4Bit_Spare2" 2 "QualityEnum4Bit_Spare1" 1 "QualityEnum4Bit_Acceptable" 0 "QualityEnum4Bit_NotAcceptable" ;
VAL_ 592 CpbtyAxle3_BrkEgyCpctyQltyRi 15 "QualityEnum4Bit_NotAvailable" 14 "QualityEnum4Bit_Error" 13 "QualityEnum4Bit_Spare12" 12 "QualityEnum4Bit_Spare11" 11 "QualityEnum4Bit_Spare10" 10 "QualityEnum4Bit_Spare9" 9 "QualityEnum4Bit_Spare8" 8 "QualityEnum4Bit_Spare7" 7 "QualityEnum4Bit_Spare6" 6 "QualityEnum4Bit_Spare5" 5 "QualityEnum4Bit_Spare4" 4 "QualityEnum4Bit_Spare3" 3 "QualityEnum4Bit_Spare2" 2 "QualityEnum4Bit_Spare1" 1 "QualityEnum4Bit_Acceptable" 0 "QualityEnum4Bit_NotAcceptable" ;
VAL_ 592 CpbtyAxle3_TqCpbtyQltyRi 15 "QualityEnum4Bit_NotAvailable" 14 "QualityEnum4Bit_Error" 13 "QualityEnum4Bit_Spare12" 12 "QualityEnum4Bit_Spare11" 11 "QualityEnum4Bit_Spare10" 10 "QualityEnum4Bit_Spare9" 9 "QualityEnum4Bit_Spare8" 8 "QualityEnum4Bit_Spare7" 7 "QualityEnum4Bit_Spare6" 6 "QualityEnum4Bit_Spare5" 5 "QualityEnum4Bit_Spare4" 4 "QualityEnum4Bit_Spare3" 3 "QualityEnum4Bit_Spare2" 2 "QualityEnum4Bit_Spare1" 1 "QualityEnum4Bit_Acceptable" 0 "QualityEnum4Bit_NotAcceptable" ;
VAL_ 592 CpbtyAxle2_BrkEgyCpctyQltyRi 15 "QualityEnum4Bit_NotAvailable" 14 "QualityEnum4Bit_Error" 13 "QualityEnum4Bit_Spare12" 12 "QualityEnum4Bit_Spare11" 11 "QualityEnum4Bit_Spare10" 10 "QualityEnum4Bit_Spare9" 9 "QualityEnum4Bit_Spare8" 8 "QualityEnum4Bit_Spare7" 7 "QualityEnum4Bit_Spare6" 6 "QualityEnum4Bit_Spare5" 5 "QualityEnum4Bit_Spare4" 4 "QualityEnum4Bit_Spare3" 3 "QualityEnum4Bit_Spare2" 2 "QualityEnum4Bit_Spare1" 1 "QualityEnum4Bit_Acceptable" 0 "QualityEnum4Bit_NotAcceptable" ;
VAL_ 592 CpbtyAxle2_TqCpbtyQltyRi 15 "QualityEnum4Bit_NotAvailable" 14 "QualityEnum4Bit_Error" 13 "QualityEnum4Bit_Spare12" 12 "QualityEnum4Bit_Spare11" 11 "QualityEnum4Bit_Spare10" 10 "QualityEnum4Bit_Spare9" 9 "QualityEnum4Bit_Spare8" 8 "QualityEnum4Bit_Spare7" 7 "QualityEnum4Bit_Spare6" 6 "QualityEnum4Bit_Spare5" 5 "QualityEnum4Bit_Spare4" 4 "QualityEnum4Bit_Spare3" 3 "QualityEnum4Bit_Spare2" 2 "QualityEnum4Bit_Spare1" 1 "QualityEnum4Bit_Acceptable" 0 "QualityEnum4Bit_NotAcceptable" ;
VAL_ 592 CpbtyAxle2_PadWearQltyRi 15 "QualityEnum4Bit_NotAvailable" 14 "QualityEnum4Bit_Error" 13 "QualityEnum4Bit_Spare12" 12 "QualityEnum4Bit_Spare11" 11 "QualityEnum4Bit_Spare10" 10 "QualityEnum4Bit_Spare9" 9 "QualityEnum4Bit_Spare8" 8 "QualityEnum4Bit_Spare7" 7 "QualityEnum4Bit_Spare6" 6 "QualityEnum4Bit_Spare5" 5 "QualityEnum4Bit_Spare4" 4 "QualityEnum4Bit_Spare3" 3 "QualityEnum4Bit_Spare2" 2 "QualityEnum4Bit_Spare1" 1 "QualityEnum4Bit_Acceptable" 0 "QualityEnum4Bit_NotAcceptable" ;
VAL_ 592 CpbtyAxle3_PadWearQltyRi 15 "QualityEnum4Bit_NotAvailable" 14 "QualityEnum4Bit_Error" 13 "QualityEnum4Bit_Spare12" 12 "QualityEnum4Bit_Spare11" 11 "QualityEnum4Bit_Spare10" 10 "QualityEnum4Bit_Spare9" 9 "QualityEnum4Bit_Spare8" 8 "QualityEnum4Bit_Spare7" 7 "QualityEnum4Bit_Spare6" 6 "QualityEnum4Bit_Spare5" 5 "QualityEnum4Bit_Spare4" 4 "QualityEnum4Bit_Spare3" 3 "QualityEnum4Bit_Spare2" 2 "QualityEnum4Bit_Spare1" 1 "QualityEnum4Bit_Acceptable" 0 "QualityEnum4Bit_NotAcceptable" ;
VAL_ 592 CpbtyAxle2_TqCpbtyRateQltyRi 15 "QualityEnum4Bit_NotAvailable" 14 "QualityEnum4Bit_Error" 13 "QualityEnum4Bit_Spare12" 12 "QualityEnum4Bit_Spare11" 11 "QualityEnum4Bit_Spare10" 10 "QualityEnum4Bit_Spare9" 9 "QualityEnum4Bit_Spare8" 8 "QualityEnum4Bit_Spare7" 7 "QualityEnum4Bit_Spare6" 6 "QualityEnum4Bit_Spare5" 5 "QualityEnum4Bit_Spare4" 4 "QualityEnum4Bit_Spare3" 3 "QualityEnum4Bit_Spare2" 2 "QualityEnum4Bit_Spare1" 1 "QualityEnum4Bit_Acceptable" 0 "QualityEnum4Bit_NotAcceptable" ;
VAL_ 592 CpbtyAxle2_SlipCtrlEna 3 "DisableEnable_NotAvailable" 2 "DisableEnable_Error" 1 "DisableEnable_Enable" 0 "DisableEnable_Disable" ;
VAL_ 592 CpbtyAxle1_TqCpbtyRateQltyRi 15 "QualityEnum4Bit_NotAvailable" 14 "QualityEnum4Bit_Error" 13 "QualityEnum4Bit_Spare12" 12 "QualityEnum4Bit_Spare11" 11 "QualityEnum4Bit_Spare10" 10 "QualityEnum4Bit_Spare9" 9 "QualityEnum4Bit_Spare8" 8 "QualityEnum4Bit_Spare7" 7 "QualityEnum4Bit_Spare6" 6 "QualityEnum4Bit_Spare5" 5 "QualityEnum4Bit_Spare4" 4 "QualityEnum4Bit_Spare3" 3 "QualityEnum4Bit_Spare2" 2 "QualityEnum4Bit_Spare1" 1 "QualityEnum4Bit_Acceptable" 0 "QualityEnum4Bit_NotAcceptable" ;
VAL_ 592 CpbtyAxle1_PadWearQltyRi 15 "QualityEnum4Bit_NotAvailable" 14 "QualityEnum4Bit_Error" 13 "QualityEnum4Bit_Spare12" 12 "QualityEnum4Bit_Spare11" 11 "QualityEnum4Bit_Spare10" 10 "QualityEnum4Bit_Spare9" 9 "QualityEnum4Bit_Spare8" 8 "QualityEnum4Bit_Spare7" 7 "QualityEnum4Bit_Spare6" 6 "QualityEnum4Bit_Spare5" 5 "QualityEnum4Bit_Spare4" 4 "QualityEnum4Bit_Spare3" 3 "QualityEnum4Bit_Spare2" 2 "QualityEnum4Bit_Spare1" 1 "QualityEnum4Bit_Acceptable" 0 "QualityEnum4Bit_NotAcceptable" ;
VAL_ 592 CpbtyAxle3_PadWearQltyLe 15 "QualityEnum4Bit_NotAvailable" 14 "QualityEnum4Bit_Error" 13 "QualityEnum4Bit_Spare12" 12 "QualityEnum4Bit_Spare11" 11 "QualityEnum4Bit_Spare10" 10 "QualityEnum4Bit_Spare9" 9 "QualityEnum4Bit_Spare8" 8 "QualityEnum4Bit_Spare7" 7 "QualityEnum4Bit_Spare6" 6 "QualityEnum4Bit_Spare5" 5 "QualityEnum4Bit_Spare4" 4 "QualityEnum4Bit_Spare3" 3 "QualityEnum4Bit_Spare2" 2 "QualityEnum4Bit_Spare1" 1 "QualityEnum4Bit_Acceptable" 0 "QualityEnum4Bit_NotAcceptable" ;
VAL_ 592 CpbtyAxle1_TqCpbtyRateQltyLe 15 "QualityEnum4Bit_NotAvailable" 14 "QualityEnum4Bit_Error" 13 "QualityEnum4Bit_Spare12" 12 "QualityEnum4Bit_Spare11" 11 "QualityEnum4Bit_Spare10" 10 "QualityEnum4Bit_Spare9" 9 "QualityEnum4Bit_Spare8" 8 "QualityEnum4Bit_Spare7" 7 "QualityEnum4Bit_Spare6" 6 "QualityEnum4Bit_Spare5" 5 "QualityEnum4Bit_Spare4" 4 "QualityEnum4Bit_Spare3" 3 "QualityEnum4Bit_Spare2" 2 "QualityEnum4Bit_Spare1" 1 "QualityEnum4Bit_Acceptable" 0 "QualityEnum4Bit_NotAcceptable" ;
VAL_ 592 CpbtyAxle1_TqCpbtyQltyRi 15 "QualityEnum4Bit_NotAvailable" 14 "QualityEnum4Bit_Error" 13 "QualityEnum4Bit_Spare12" 12 "QualityEnum4Bit_Spare11" 11 "QualityEnum4Bit_Spare10" 10 "QualityEnum4Bit_Spare9" 9 "QualityEnum4Bit_Spare8" 8 "QualityEnum4Bit_Spare7" 7 "QualityEnum4Bit_Spare6" 6 "QualityEnum4Bit_Spare5" 5 "QualityEnum4Bit_Spare4" 4 "QualityEnum4Bit_Spare3" 3 "QualityEnum4Bit_Spare2" 2 "QualityEnum4Bit_Spare1" 1 "QualityEnum4Bit_Acceptable" 0 "QualityEnum4Bit_NotAcceptable" ;
VAL_ 592 CpbtyAxle2_TqCpbtyQltyLe 15 "QualityEnum4Bit_NotAvailable" 14 "QualityEnum4Bit_Error" 13 "QualityEnum4Bit_Spare12" 12 "QualityEnum4Bit_Spare11" 11 "QualityEnum4Bit_Spare10" 10 "QualityEnum4Bit_Spare9" 9 "QualityEnum4Bit_Spare8" 8 "QualityEnum4Bit_Spare7" 7 "QualityEnum4Bit_Spare6" 6 "QualityEnum4Bit_Spare5" 5 "QualityEnum4Bit_Spare4" 4 "QualityEnum4Bit_Spare3" 3 "QualityEnum4Bit_Spare2" 2 "QualityEnum4Bit_Spare1" 1 "QualityEnum4Bit_Acceptable" 0 "QualityEnum4Bit_NotAcceptable" ;
VAL_ 592 CpbtyAxle2_TqCpbtyRateQltyLe 15 "QualityEnum4Bit_NotAvailable" 14 "QualityEnum4Bit_Error" 13 "QualityEnum4Bit_Spare12" 12 "QualityEnum4Bit_Spare11" 11 "QualityEnum4Bit_Spare10" 10 "QualityEnum4Bit_Spare9" 9 "QualityEnum4Bit_Spare8" 8 "QualityEnum4Bit_Spare7" 7 "QualityEnum4Bit_Spare6" 6 "QualityEnum4Bit_Spare5" 5 "QualityEnum4Bit_Spare4" 4 "QualityEnum4Bit_Spare3" 3 "QualityEnum4Bit_Spare2" 2 "QualityEnum4Bit_Spare1" 1 "QualityEnum4Bit_Acceptable" 0 "QualityEnum4Bit_NotAcceptable" ;
VAL_ 592 CpbtyAxle1_BrkEgyCpctyQltyLe 15 "QualityEnum4Bit_NotAvailable" 14 "QualityEnum4Bit_Error" 13 "QualityEnum4Bit_Spare12" 12 "QualityEnum4Bit_Spare11" 11 "QualityEnum4Bit_Spare10" 10 "QualityEnum4Bit_Spare9" 9 "QualityEnum4Bit_Spare8" 8 "QualityEnum4Bit_Spare7" 7 "QualityEnum4Bit_Spare6" 6 "QualityEnum4Bit_Spare5" 5 "QualityEnum4Bit_Spare4" 4 "QualityEnum4Bit_Spare3" 3 "QualityEnum4Bit_Spare2" 2 "QualityEnum4Bit_Spare1" 1 "QualityEnum4Bit_Acceptable" 0 "QualityEnum4Bit_NotAcceptable" ;
VAL_ 592 CpbtyAxle2_PadWearQltyLe 15 "QualityEnum4Bit_NotAvailable" 14 "QualityEnum4Bit_Error" 13 "QualityEnum4Bit_Spare12" 12 "QualityEnum4Bit_Spare11" 11 "QualityEnum4Bit_Spare10" 10 "QualityEnum4Bit_Spare9" 9 "QualityEnum4Bit_Spare8" 8 "QualityEnum4Bit_Spare7" 7 "QualityEnum4Bit_Spare6" 6 "QualityEnum4Bit_Spare5" 5 "QualityEnum4Bit_Spare4" 4 "QualityEnum4Bit_Spare3" 3 "QualityEnum4Bit_Spare2" 2 "QualityEnum4Bit_Spare1" 1 "QualityEnum4Bit_Acceptable" 0 "QualityEnum4Bit_NotAcceptable" ;
VAL_ 1105 TrailerLiftAxlePos 3 "TrailerLiftAxlePos_NotAvailable" 2 "TrailerLiftAxlePos_Error" 1 "TrailerLiftAxlePos_AxleLifted" 0 "TrailerLiftAxlePos_AxleDown" ;
VAL_ 1105 XBRSystemState 3 "XBRSystemState_NotAvailable" 2 "XBRSystemState_NoExternalBrakeDemandAccepted" 1 "XBRSystemState_OnlyHighestXBRPriorityDemandAccepted" 0 "XBRSystemState_ExternalBrakeDemandAccepted" ;
VAL_ 1105 TrailerCommunicationType 7 "TrailerCommunicationType_NotAvailable" 6 "TrailerCommunicationType_Error" 5 "TrailerCommunicationType_Spare3" 4 "TrailerCommunicationType_Spare2" 3 "TrailerCommunicationType_Spare1" 2 "TrailerCommunicationType_SAE_J2497_Communication" 1 "TrailerCommunicationType_ISO_11992_2_Communication" 0 "TrailerCommunicationType_NoCommunication" ;
VAL_ 439 ABSAxle5Active 3 "OffOn_NotAvailable" 2 "OffOn_Error" 1 "OffOn_On" 0 "OffOn_Off" ;
VAL_ 439 Trailer1LiftAxle2Pos 3 "TrailerLiftAxlePos_NotAvailable" 2 "TrailerLiftAxlePos_Error" 1 "TrailerLiftAxlePos_AxleLifted" 0 "TrailerLiftAxlePos_AxleDown" ;
VAL_ 439 Trailer1TractionHelp 3 "InactiveActive_NotAvailable" 2 "InactiveActive_Error" 1 "InactiveActive_Active" 0 "InactiveActive_Inactive" ;
VAL_ 439 EBSBrakeSwitch 3 "EBSBrakeSwitch_NotAvailable" 2 "EBSBrakeSwitch_Error" 1 "EBSBrakeSwitch_BrakePedalDepressed" 0 "EBSBrakeSwitch_BrakePedalReleased" ;
VAL_ 439 EACompound_SystemState 3 "OperationalState_NotAvailable" 2 "OperationalState_Error" 1 "OperationalState_FullyOperational" 0 "OperationalState_NotOperational" ;
VAL_ 439 Trailer1LiftAxle1Pos 3 "TrailerLiftAxlePos_NotAvailable" 2 "TrailerLiftAxlePos_Error" 1 "TrailerLiftAxlePos_AxleLifted" 0 "TrailerLiftAxlePos_AxleDown" ;
VAL_ 439 AntiLockBrakingActive 3 "AntiLockBrakingActive_NotAvailable" 2 "AntiLockBrakingActive_Reserved" 1 "AntiLockBrakingActive_ABSActive" 0 "AntiLockBrakingActive_ABSPassiveButInstalled" ;
VAL_ 439 StretchBrake_Stat 7 "StretchBrake_Stat_NotAvailable" 6 "StretchBrake_Stat_Error" 5 "StretchBrake_Stat_Spare_02" 4 "StretchBrake_Stat_Spare_01" 3 "StretchBrake_Stat_Spare" 2 "StretchBrake_Stat_Active" 1 "StretchBrake_Stat_Enabled" 0 "StretchBrake_Stat_Disabled" ;
VAL_ 439 HillHolderMode 7 "HillHolderMode_NotAvailable" 6 "HillHolderMode_Reserved" 5 "HillHolderMode_Spare2" 4 "HillHolderMode_Spare1" 3 "HillHolderMode_OnHold_PressureApplied" 2 "HillHolderMode_Active_WillChangeToInactiveSoon" 1 "HillHolderMode_Active" 0 "HillHolderMode_Inactive" ;
VAL_ 439 ABSAxle4Active 3 "OffOn_NotAvailable" 2 "OffOn_Error" 1 "OffOn_On" 0 "OffOn_Off" ;
VAL_ 439 TrailerBrake_Stat 3 "InactiveActive_NotAvailable" 2 "InactiveActive_Error" 1 "InactiveActive_Active" 0 "InactiveActive_Inactive" ;
VAL_ 439 ABSAxle2Active 3 "OffOn_NotAvailable" 2 "OffOn_Error" 1 "OffOn_On" 0 "OffOn_Off" ;
VAL_ 439 TrailerEBSAmberWarning 3 "OffOn_NotAvailable" 2 "OffOn_Error" 1 "OffOn_On" 0 "OffOn_Off" ;
VAL_ 439 ABSAxle1Active 3 "OffOn_NotAvailable" 2 "OffOn_Error" 1 "OffOn_On" 0 "OffOn_Off" ;
VAL_ 439 ABSAxle3Active 3 "OffOn_NotAvailable" 2 "OffOn_Error" 1 "OffOn_On" 0 "OffOn_Off" ;
VAL_ 439 PusherLiftAxleLoweringInhibit 3 "InhibitStatus_NotAvailable" 2 "InhibitStatus_Reserved" 1 "InhibitStatus_Inhibited" 0 "InhibitStatus_NotInhibited" ;
VAL_ 439 CombinedWheelSpeed_Quality 7 "Quality3bit_NotAvailable" 6 "Quality3bit_Error" 5 "Quality3bit_Reserved4" 4 "Quality3bit_ASIL_D" 3 "Quality3bit_Reserved3" 2 "Quality3bit_Reserved2" 1 "Quality3bit_Reserved1" 0 "Quality3bit_ASIL_QM" ;
VAL_ 439 SplitBoxDiffLockActvnFuncReq 3 "DisengageEngage_NotAvailable" 2 "DisengageEngage_Error" 1 "DisengageEngage_Engage" 0 "DisengageEngage_Disengage" ;
VAL_ 439 FrontParkBrakeOverrideStatus 3 "InactiveActive_NotAvailable" 2 "InactiveActive_Error" 1 "InactiveActive_Active" 0 "InactiveActive_Inactive" ;
VAL_ 439 SteerableLiftAxleLoweringInhib 3 "InhibitStatus_NotAvailable" 2 "InhibitStatus_Reserved" 1 "InhibitStatus_Inhibited" 0 "InhibitStatus_NotInhibited" ;
VAL_ 439 BrakingSystemPressureLim_rqst 3 "Request_NotAvailable" 2 "Request_Error" 1 "Request_RequestActive" 0 "Request_NotRequested" ;
VAL_ 439 ScndRrAxlDiffLckActvnFuncReq 3 "RearAxleDiffLockActvnFuncReq_TakeNoAction" 2 "RearAxleDiffLockActvnFuncReq_Reserved" 1 "RearAxleDiffLockActvnFuncReq_DisengageDifferentialLock" 0 "RearAxleDiffLockActvnFuncReq_EngageDifferentialLock" ;
VAL_ 439 HSAState 3 "HSAState_NotAvailable" 2 "HSAState_HSA_FunctionFullyOperational" 1 "HSAState_HSA_FunctionnotWorking" 0 "HSAState_HSA_FunctionRestrictedFunctionalityAvailable" ;
SIG_GROUP_ 594 CpbtyAxle5_sg 1 : CpbtyAxle5_BrkEgyCpctyLe CpbtyAxle5_TqCpbtyMaxLe CpbtyAxle5_TqCpbtyQltyLe CpbtyAxle5_PadWearRi CpbtyAxle5_TqCpbtyRateIncLeRi CpbtyAxle5_TqCpbtyRateDecLe CpbtyAxle5_TqCpbtyMaxRi CpbtyAxle5_CRC CpbtyAxle5_SlipCtrlEna CpbtyAxle5_PadWearQltyLe CpbtyAxle5_BrkEgyCpctyQltyLe CpbtyAxle5_TqCpbtyRateQltyLe CpbtyAxle5_TqCpbtyMinLe CpbtyAxle5_TqCpbtyRateQltyRi CpbtyAxle5_TqCpbtyQltyRi CpbtyAxle5_TqCpbtyMinRi CpbtyAxle5_TqCpbtyRateIncLeLe CpbtyAxle5_PadWearQltyRi CpbtyAxle5_TqCpbtyRateDecRi CpbtyAxle5_SqC CpbtyAxle5_BrkEgyCpctyRi CpbtyAxle5_BrkEgyCpctyQltyRi CpbtyAxle5_PadWearLe;
SIG_GROUP_ 594 CpbtyAxle4_sg 1 : CpbtyAxle4_TqCpbtyRateQltyLe CpbtyAxle4_TqCpbtyRateDecRi CpbtyAxle4_BrkEgyCpctyQltyRi CpbtyAxle4_TqCpbtyMinRi CpbtyAxle4_TqCpbtyQltyLe CpbtyAxle4_SlipCtrlEna CpbtyAxle4_BrkEgyCpctyRi CpbtyAxle4_TqCpbtyMaxLe CpbtyAxle4_PadWearRi CpbtyAxle4_CRC CpbtyAxle4_SqC CpbtyAxle4_TqCpbtyQltyRi CpbtyAxle4_BrkEgyCpctyQltyLe CpbtyAxle4_TqCpbtyMinLe CpbtyAxle4_TqCpbtyRateDecLe CpbtyAxle4_TqCpbtyRateQltyRi CpbtyAxle4_BrkEgyCpctyLe CpbtyAxle4_TqCpbtyMaxRi CpbtyAxle4_TqCpbtyRateIncLeRi CpbtyAxle4_PadWearLe CpbtyAxle4_PadWearQltyRi CpbtyAxle4_TqCpbtyRateIncLeLe CpbtyAxle4_PadWearQltyLe;
SIG_GROUP_ 594 CpbtyAxle6_sg 1 : CpbtyAxle6_TqCpbtyRateQltyLe CpbtyAxle6_TqCpbtyMinRi CpbtyAxle6_BrkEgyCpctyRi CpbtyAxle6_TqCpbtyRateQltyRi CpbtyAxle6_TqCpbtyRateIncLeRi CpbtyAxle6_TqCpbtyRateDecLe CpbtyAxle6_BrkEgyCpctyQltyRi CpbtyAxle6_PadWearQltyRi CpbtyAxle6_TqCpbtyMaxRi CpbtyAxle6_TqCpbtyQltyRi CpbtyAxle6_CRC CpbtyAxle6_TqCpbtyMinLe CpbtyAxle6_PadWearQltyLe CpbtyAxle6_PadWearRi CpbtyAxle6_SlipCtrlEna CpbtyAxle6_SqC CpbtyAxle6_TqCpbtyRateDecRi CpbtyAxle6_TqCpbtyRateIncLeLe CpbtyAxle6_TqCpbtyMaxLe CpbtyAxle6_BrkEgyCpctyQltyLe CpbtyAxle6_TqCpbtyQltyLe CpbtyAxle6_BrkEgyCpctyLe CpbtyAxle6_PadWearLe;
SIG_GROUP_ 592 CpbtyAxle2_sg 1 : CpbtyAxle2_PadWearRi CpbtyAxle2_TqCpbtyMaxRi CpbtyAxle2_TqCpbtyMinLe CpbtyAxle2_BrkEgyCpctyQltyLe CpbtyAxle2_TqCpbtyRateDecLe CpbtyAxle2_TqCpbtyRateDecRi CpbtyAxle2_TqCpbtyMaxLe CpbtyAxle2_BrkEgyCpctyQltyRi CpbtyAxle2_PadWearLe CpbtyAxle2_TqCpbtyQltyRi CpbtyAxle2_PadWearQltyRi CpbtyAxle2_TqCpbtyRateQltyRi CpbtyAxle2_SlipCtrlEna CpbtyAxle2_TqCpbtyMinRi CpbtyAxle2_CRC CpbtyAxle2_SqC CpbtyAxle2_TqCpbtyRateIncLeLe CpbtyAxle2_TqCpbtyRateIncLeRi CpbtyAxle2_BrkEgyCpctyLe CpbtyAxle2_TqCpbtyQltyLe CpbtyAxle2_TqCpbtyRateQltyLe CpbtyAxle2_BrkEgyCpctyRi CpbtyAxle2_PadWearQltyLe;
SIG_GROUP_ 592 CpbtyAxle3_sg 1 : CpbtyAxle3_BrkEgyCpctyQltyLe CpbtyAxle3_TqCpbtyRateIncLeLe CpbtyAxle3_TqCpbtyRateQltyRi CpbtyAxle3_TqCpbtyRateQltyLe CpbtyAxle3_SlipCtrlEna CpbtyAxle3_TqCpbtyQltyLe CpbtyAxle3_BrkEgyCpctyRi CpbtyAxle3_BrkEgyCpctyQltyRi CpbtyAxle3_TqCpbtyRateDecLe CpbtyAxle3_TqCpbtyRateDecRi CpbtyAxle3_TqCpbtyQltyRi CpbtyAxle3_TqCpbtyMinLe CpbtyAxle3_TqCpbtyMinRi CpbtyAxle3_PadWearRi CpbtyAxle3_PadWearQltyRi CpbtyAxle3_TqCpbtyMaxLe CpbtyAxle3_TqCpbtyMaxRi CpbtyAxle3_PadWearQltyLe CpbtyAxle3_PadWearLe CpbtyAxle3_BrkEgyCpctyLe CpbtyAxle3_TqCpbtyRateIncLeRi CpbtyAxle3_CRC CpbtyAxle3_SqC;
SIG_GROUP_ 592 CpbtyAxle1_sg 1 : CpbtyAxle1_PadWearQltyLe CpbtyAxle1_SlipCtrlEna CpbtyAxle1_BrkEgyCpctyQltyRi CpbtyAxle1_SqC CpbtyAxle1_TqCpbtyQltyLe CpbtyAxle1_TqCpbtyRateIncLeLe CpbtyAxle1_PadWearRi CpbtyAxle1_TqCpbtyRateDecLe CpbtyAxle1_BrkEgyCpctyRi CpbtyAxle1_TqCpbtyMaxRi CpbtyAxle1_BrkEgyCpctyLe CpbtyAxle1_TqCpbtyRateIncLeRi CpbtyAxle1_TqCpbtyRateQltyRi CpbtyAxle1_CRC CpbtyAxle1_PadWearQltyRi CpbtyAxle1_TqCpbtyRateDecRi CpbtyAxle1_TqCpbtyRateQltyLe CpbtyAxle1_PadWearLe CpbtyAxle1_TqCpbtyMinRi CpbtyAxle1_TqCpbtyQltyRi CpbtyAxle1_TqCpbtyMinLe CpbtyAxle1_BrkEgyCpctyQltyLe CpbtyAxle1_TqCpbtyMaxLe;
SIG_GROUP_ 439 CombinedWheelSpeed_sg 1 : CombinedWheelSpeed_CRC CombinedWheelSpeed_SqC CombinedWheelSpeed_Quality CombinedWheelSpeed_Speed;
SIG_GROUP_ 439 EACompound_sg 1 : EACompound_CRC EACompound_SystemState EACompound_AppliedRatio EACompound_SqC;
SIG_GROUP_ 439 TCMSupply_sg 1 : TCMSupply_SqC TCMSupply_CRC TCMSupply_TrailerPressure;
SIG_GROUP_ 315 SteeringWheel_sg 1 : SteeringWheel_AngleCRC SteeringWheel_AngleCounter SteeringWheel_AngleValue;
SIG_GROUP_ 1491 DiagFaultStat_FAS_sg 1 : DiagFaultStat_FAS_FailTA DiagFaultStat_FAS_EcuAdr DiagFaultStat_FAS_DtcIdA DiagFaultStat_FAS_DtcIdB DiagFaultStat_FAS_FailTB;
